VERSION ""

NS_ :

BS_:

BU_: BMS2 BMS1
VAL_TABLE_ PWM_LossOfCom 3 "reserved - same as 0x0 for now" 2 "reserved - same as 0x0 for now" 1 "remain the last received command until communicatino recovers" 0 "default - set output to 0%" ;

BO_ 3221225472 VECTOR__INDEPENDENT_SIG_MSG: 0 Vector__XXX
 SG_ BMS9_N_PosInsR_Copy_1 : 0|16@0+ (1,0) [0|65535] "" Vector__XXX
 SG_ BMS9_N_NegInsR : 0|16@0+ (1,0) [0|65535] "" Vector__XXX
 SG_ BMS9_N_PosInsR : 0|16@0+ (1,0) [0|65535] "" Vector__XXX
 SG_ BMS2_3_Checksum : 0|8@0+ (1,0) [0|255] "" Vector__XXX
 SG_ BMS2_3_F_CellOverV : 0|1@0+ (1,0) [0|1] "" Vector__XXX
 SG_ BMS2_3_F_CellUnderV : 0|1@0+ (1,0) [0|1] "" Vector__XXX
 SG_ BMS2_3_F_CellVoltagedropout : 0|1@0+ (1,0) [0|1] "" Vector__XXX
 SG_ BMS2_3_F_BattOverV : 0|1@0+ (1,0) [0|1] "" Vector__XXX
 SG_ BMS2_3_F_BattUnderV : 0|1@0+ (1,0) [0|1] "" Vector__XXX
 SG_ BMS2_3_RollingCounter : 0|4@0+ (1,0) [0|15] "" Vector__XXX
 SG_ BMS2_9_F_BattSupplyingOverI : 0|2@0+ (1,0) [0|3] "" Vector__XXX
 SG_ BMS2_9_F_QCNegativeRelay : 0|2@0+ (1,0) [0|3] "" Vector__XXX
 SG_ BMS2_9_F_MainPositiveRelayCoil : 0|2@0+ (1,0) [0|3] "" Vector__XXX
 SG_ BMS2_9_F_MainNegativeRelayCoil : 0|2@0+ (1,0) [0|3] "" Vector__XXX
 SG_ BMS2_9_F_PrechargeRelayCoil : 0|2@0+ (1,0) [0|3] "" Vector__XXX
 SG_ BMS2_9_F_QCPositiveRelayCoil : 0|2@0+ (1,0) [0|3] "" Vector__XXX
 SG_ BMS2_9_F_MainPositiveRelay : 0|2@0+ (1,0) [0|3] "" Vector__XXX
 SG_ BMS2_9_F_QCNegativeRelayCoil : 0|2@0+ (1,0) [0|3] "" Vector__XXX
 SG_ BMS2_9_F_CellBalancingCircuit : 0|1@0+ (1,0) [0|1] "" Vector__XXX
 SG_ BMS2_9_F_BattOverChgErr : 0|1@0+ (1,0) [0|1] "" Vector__XXX
 SG_ BMS2_9_F_BattPluginChgOverI : 0|2@0+ (1,0) [0|3] "" Vector__XXX
 SG_ BMS2_9_F_PrechargeRelayOpenStuck : 0|1@0+ (1,0) [0|1] "" Vector__XXX
 SG_ BMS2_9_F_MSDFuse : 0|1@0+ (1,0) [0|1] "" Vector__XXX
 SG_ BMS2_9_F_HVBattTempRisingOverspe : 0|1@0+ (1,0) [0|1] "" Vector__XXX
 SG_ BMS2_9_F_BattRegenerativeOverI : 0|2@0+ (1,0) [0|3] "" Vector__XXX
 SG_ BMS2_9_F_MainNegativeRelay : 0|2@0+ (1,0) [0|3] "" Vector__XXX
 SG_ BMS2_9_F_PrechargeRelay : 0|2@0+ (1,0) [0|3] "" Vector__XXX
 SG_ BMS2_9_F_QCPositiveRelay : 0|2@0+ (1,0) [0|3] "" Vector__XXX
 SG_ BMS3_F_CellOverV : 0|1@0+ (1,0) [0|1] "" Vector__XXX
 SG_ BMS3_F_CellUnderV : 0|1@0+ (1,0) [0|1] "" Vector__XXX
 SG_ BMS3_F_CellVoltagedropout : 0|1@0+ (1,0) [0|1] "" Vector__XXX
 SG_ BMS3_F_BattOverV : 0|1@0+ (1,0) [0|1] "" Vector__XXX
 SG_ BMS3_F_BattUnderV : 0|1@0+ (1,0) [0|1] "" Vector__XXX
 SG_ HCU_2_RelayOn : 0|1@0+ (1,0) [0|1] "" Vector__XXX
 SG_ HCU_2_PWM_LossOfCom : 0|2@0+ (1,0) [0|3] "" Vector__XXX
 SG_ HCU_2_PWM_Dutycycle : 0|8@0+ (0.5,0) [0|127.5] "%" Vector__XXX
 SG_ HCU_2_OBCRelayStatus : 0|1@0+ (1,0) [0|1] "" Vector__XXX
 SG_ HCU_2_ChargingStopRequest : 0|2@0+ (1,0) [0|3] "" Vector__XXX
 SG_ HCU_2_ChargerAllow : 0|1@0+ (1,0) [0|1] "" Vector__XXX
 SG_ HCU_2_CCStatus : 0|1@0+ (1,0) [0|1] "" Vector__XXX
 SG_ HCU2_2_RelayOn : 0|1@0+ (1,0) [0|1] "" Vector__XXX
 SG_ HCU2_2_PWM_LossOfCom : 0|2@0+ (1,0) [0|3] "" Vector__XXX
 SG_ HCU2_2_PWM_Dutycycle : 0|8@0+ (0.5,0) [0|127.5] "%" Vector__XXX
 SG_ HCU2_2_OBCRelayStatus : 0|1@0+ (1,0) [0|1] "" Vector__XXX
 SG_ HCU2_2_ChargingStopRequest : 0|2@0+ (1,0) [0|3] "" Vector__XXX
 SG_ HCU2_2_ChargerAllow : 0|1@0+ (1,0) [0|1] "" Vector__XXX
 SG_ HCU2_2_CCStatus : 0|1@0+ (1,0) [0|1] "" Vector__XXX

BO_ 1192 BMS_12: 4 BMS1
 SG_ BMS12_N_TempMinModule : 31|8@0+ (1,0) [0|44] "" Vector__XXX
 SG_ BMS12_N_TempMaxModule : 23|8@0+ (1,0) [0|44] "" Vector__XXX
 SG_ BMS12_N_CellVolMinModule : 15|8@0+ (1,0) [0|44] "" Vector__XXX
 SG_ BMS12_N_CellVolMaxModule : 7|8@0+ (1,0) [0|44] "" Vector__XXX

BO_ 1208 BMS2_12: 4 BMS2
 SG_ BMS2_12_N_TempMaxModule : 31|8@0+ (1,0) [0|44] ""  BMS2
 SG_ BMS2_12_N_CellVolMinModule : 23|8@0+ (1,0) [0|44] ""  BMS2
 SG_ BMS2_12_N_CellVolMaxModule : 15|8@0+ (1,0) [0|44] ""  BMS2
 SG_ BMS2_12_N_TempMinModule : 7|8@0+ (1,0) [0|44] ""  BMS2

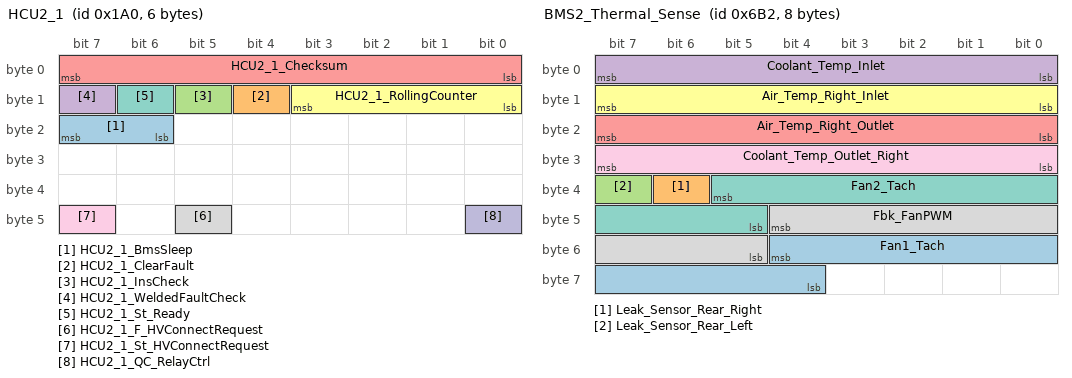
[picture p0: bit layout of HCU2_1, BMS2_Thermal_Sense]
BO_ 416 HCU2_1: 6 Vector__XXX
 SG_ HCU2_1_BmsSleep : 23|2@0+ (1,0) [0|3] ""  BMS2
 SG_ HCU2_1_ClearFault : 12|1@0+ (1,0) [0|0] ""  BMS2
 SG_ HCU2_1_InsCheck : 13|1@0+ (1,0) [0|1] ""  BMS2
 SG_ HCU2_1_WeldedFaultCheck : 15|1@0+ (1,0) [0|1] ""  BMS2
 SG_ HCU2_1_Checksum : 7|8@0+ (1,0) [0|255] ""  BMS2
 SG_ HCU2_1_RollingCounter : 11|4@0+ (1,0) [0|15] ""  BMS2
 SG_ HCU2_1_St_Ready : 14|1@0+ (1,0) [0|1] ""  BMS2
 SG_ HCU2_1_F_HVConnectRequest : 45|1@0+ (1,0) [0|1] ""  BMS2
 SG_ HCU2_1_St_HVConnectRequest : 47|1@0+ (1,0) [0|1] ""  BMS2
 SG_ HCU2_1_QC_RelayCtrl : 40|1@0+ (1,0) [0|1] ""  BMS2

BO_ 1191 BMS_11: 1 BMS1
 SG_ BMS11_St_RSPositiveRelay : 3|1@0+ (1,0) [0|1] "" Vector__XXX
 SG_ BMS11_St_RSNegativeRelay : 4|1@0+ (1,0) [0|1] "" Vector__XXX
 SG_ BMS11_St_LSPositiveRelay : 1|1@0+ (1,0) [0|1] "" Vector__XXX
 SG_ BMS11_St_LSNegativeRelay : 2|1@0+ (1,0) [0|1] "" Vector__XXX
 SG_ BMS11_St_CenterNegativeRelay : 0|1@0+ (1,0) [0|1] "" Vector__XXX

BO_ 1201 BMS2_3: 8 BMS2
 SG_ BMS2_3_N_CellVoltageMin : 52|13@0+ (1,0) [0|5000] "mV" Vector__XXX
 SG_ BMS2_3_N_CellVoltageMax : 36|13@0+ (1,0) [0|5000] "mV" Vector__XXX
 SG_ BMS2_3_N_NegInsR : 23|16@0+ (1,0) [0|65534] "K��" Vector__XXX
 SG_ BMS2_3_N_PosInsR : 7|16@0+ (1,0) [0|65534] "K��" Vector__XXX

BO_ 1185 BMS_3: 8 BMS1
 SG_ BMS3_N_CellVoltageMin : 52|13@0+ (1,0) [0|5000] "mV" Vector__XXX
 SG_ BMS3_N_CellVoltageMax : 36|13@0+ (1,0) [0|5000] "mV" Vector__XXX
 SG_ BMS3_N_NegInsR : 23|16@0+ (1,0) [0|65534] "K��" Vector__XXX
 SG_ BMS3_N_PosInsR : 7|16@0+ (1,0) [0|65534] "k��" Vector__XXX

BO_ 1712 Thermal_Actuator_Cmd: 8 Vector__XXX
 SG_ Pump_PWMFrequency : 39|8@0+ (0.5,0) [0|127.5] "kHz" Vector__XXX
 SG_ WP_DutyCycle : 31|8@0+ (1,0) [0|100] "%" Vector__XXX
 SG_ Fan_PWMFrequency : 16|8@1- (0.5,0) [-64|63.5] "kHz" Vector__XXX
 SG_ Fan_DutyCycle : 15|8@0+ (1,0) [0|100] "%" Vector__XXX
 SG_ TEC_1_Relay : 6|1@0+ (1,0) [0|1] "" Vector__XXX
 SG_ TEC_2_Relay : 7|1@0+ (1,0) [0|1] "" Vector__XXX

BO_ 1714 BMS2_Thermal_Sense: 8 BMS2
 SG_ Fan1_Tach : 52|9@0+ (16,0) [0|8176] "" Vector__XXX
 SG_ Leak_Sensor_Rear_Right : 38|1@0+ (1,0) [0|1] "" Vector__XXX
 SG_ Leak_Sensor_Rear_Left : 39|1@0+ (1,0) [0|1] "" Vector__XXX
 SG_ Coolant_Temp_Inlet : 7|8@0- (1,0) [-128|127] "" Vector__XXX
 SG_ Air_Temp_Right_Outlet : 23|8@0- (1,0) [-128|127] "" Vector__XXX
 SG_ Air_Temp_Right_Inlet : 15|8@0- (1,0) [-128|127] "" Vector__XXX
 SG_ Fan2_Tach : 37|9@0+ (16,0) [0|8176] "" Vector__XXX
 SG_ Fbk_FanPWM : 44|8@0+ (0.4,0) [0|100] "%" Vector__XXX
 SG_ Coolant_Temp_Outlet_Right : 31|8@0- (1,0) [-128|127] "" Vector__XXX

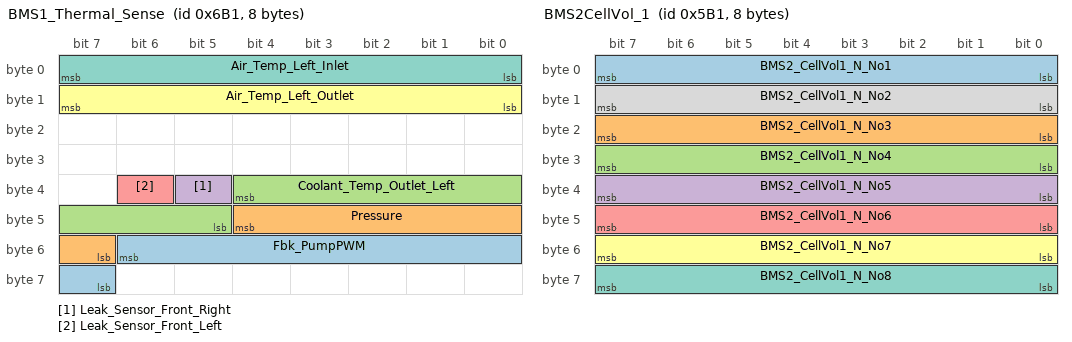
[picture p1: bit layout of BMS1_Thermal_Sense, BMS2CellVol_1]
BO_ 1713 BMS1_Thermal_Sense: 8 BMS1
 SG_ Fbk_PumpPWM : 54|8@0+ (0.4,0) [0|100] "%" Vector__XXX
 SG_ Pressure : 44|6@0+ (1,0) [0|63] "psi" Vector__XXX
 SG_ Coolant_Temp_Outlet_Left : 36|8@0- (1,0) [-128|127] "" Vector__XXX
 SG_ Leak_Sensor_Front_Right : 37|1@0+ (1,0) [0|1] "" Vector__XXX
 SG_ Leak_Sensor_Front_Left : 38|1@0+ (1,0) [0|1] "" Vector__XXX
 SG_ Air_Temp_Left_Outlet : 15|8@0- (1,0) [-128|127] "" Vector__XXX
 SG_ Air_Temp_Left_Inlet : 7|8@0- (1,0) [-128|127] "" Vector__XXX

BO_ 1533 BMS2_HWSerialNumber: 8 BMS2
 SG_ BMS2_HWSerialNumber : 7|64@0+ (1,0) [0|0] "" Vector__XXX

BO_ 1531 BMS1_HWSerialNumber: 8 BMS1
 SG_ BMS1_HWSerialNumber : 7|64@0+ (1,0) [0|1.84467440737096E+019] "" Vector__XXX

BO_ 1483 BMS2Diag: 8 BMS2
 SG_ BCM2Diag_VoltRangeFault m1 : 57|2@0+ (1,0) [0|3] "" Vector__XXX
 SG_ BCM2Diag_TtlVoltSampAbnorm m1 : 55|2@0+ (1,0) [0|3] "" Vector__XXX
 SG_ BCM2Diag_TempRangeFault m1 : 59|2@0+ (1,0) [0|3] "" Vector__XXX
 SG_ BCM2Diag_SuppVoltTooLow m1 : 53|2@0+ (1,0) [0|3] "" Vector__XXX
 SG_ BCM2Diag_SeriousOvercurrFault m1 : 51|2@0+ (1,0) [0|3] "" Vector__XXX
 SG_ BCM2Diag_SDMCommLost m1 : 49|2@0+ (1,0) [0|3] "" Vector__XXX
 SG_ BCM2Diag_RTCFault m1 : 47|2@0+ (1,0) [0|3] "" Vector__XXX
 SG_ BCM2Diag_PrsrSnsrShrtToGnd m1 : 43|2@0+ (1,0) [0|3] "" Vector__XXX
 SG_ BCM2Diag_PrsrSnsrOC m1 : 41|2@0+ (1,0) [0|3] "" Vector__XXX
 SG_ BCM2Diag_PrechrgWthLoadFault m1 : 39|2@0+ (1,0) [0|3] "" Vector__XXX
 SG_ BCM2Diag_PrechrgRelayCantClose m1 : 37|2@0+ (1,0) [0|3] "" Vector__XXX
 SG_ BCM2Diag_PrechrgFail m1 : 35|2@0+ (1,0) [0|3] "" Vector__XXX
 SG_ BCM2Diag_PosRelayStuck m1 : 33|2@0+ (1,0) [0|3] "" Vector__XXX
 SG_ BCM2Diag_PosRelayCantClose m1 : 31|2@0+ (1,0) [0|3] "" Vector__XXX
 SG_ BCM2Diag_PackVoltTooLowLvl2 m1 : 29|2@0+ (1,0) [0|3] "" Vector__XXX
 SG_ BCM2Diag_PackVoltTooLowLvl1 m1 : 27|2@0+ (1,0) [0|3] "" Vector__XXX
 SG_ BCM2Diag_PackVoltTooHighLvl2 m1 : 25|2@0+ (1,0) [0|3] "" Vector__XXX
 SG_ BCM2Diag_PackVoltTooHighLvl1 m1 : 23|2@0+ (1,0) [0|3] "" Vector__XXX
 SG_ BCM2Diag_NVMFault m1 : 21|2@0+ (1,0) [0|3] "" Vector__XXX
 SG_ BCM2Diag_NegRelayStuck m1 : 19|2@0+ (1,0) [0|3] "" Vector__XXX
 SG_ BCM2Diag_NegRelayCantClose m1 : 17|2@0+ (1,0) [0|3] "" Vector__XXX
 SG_ BCM2Diag_Mulitplexer M : 63|2@0+ (1,0) [0|3] "" Vector__XXX
 SG_ BCM2Diag_LeakSnsrShrtToGnd m1 : 15|2@0+ (1,0) [0|3] "" Vector__XXX
 SG_ BCM2Diag_LeakSnsrOC m1 : 13|2@0+ (1,0) [0|3] "" Vector__XXX
 SG_ BCM2Diag_InsFaultLvl3 m1 : 11|2@0+ (1,0) [0|3] "" Vector__XXX
 SG_ BCM2Diag_InsFaultLvl2 m1 : 9|2@0+ (1,0) [0|3] "" Vector__XXX
 SG_ BCM2Diag_InsFaultLvl1 m1 : 7|2@0+ (1,0) [0|3] "" Vector__XXX
 SG_ BCM2Diag_HVModCommLoss m1 : 5|2@0+ (1,0) [0|3] "" Vector__XXX
 SG_ BCM2Diag_HVILFault m1 : 3|2@0+ (1,0) [0|3] "" Vector__XXX
 SG_ BCM2Diag_GenertdCurrTooHighLvl2 m1 : 1|2@0+ (1,0) [0|3] "" Vector__XXX
 SG_ BCM2Diag_GenertdCurrTooHighLvl1 m0 : 57|2@0+ (1,0) [0|3] "" Vector__XXX
 SG_ BCM2Diag_FuseFault m0 : 59|2@0+ (1,0) [0|3] "" Vector__XXX
 SG_ BCM2Diag_DischrgCurrTooHighLvl2 m0 : 61|2@0+ (1,0) [0|3] "" Vector__XXX
 SG_ BCM2Diag_DischrgCurrTooHighLvl1 m1 : 45|2@0+ (1,0) [0|3] "" Vector__XXX
 SG_ BCM2Diag_CurrSnsrNoComRelayStuck m0 : 49|2@0+ (1,0) [0|3] "" Vector__XXX
 SG_ BCM2Diag_CurrSnsrFault m0 : 51|2@0+ (1,0) [0|3] "" Vector__XXX
 SG_ BCM2Diag_CurrSnsrCommTimedout m0 : 53|2@0+ (1,0) [0|3] "" Vector__XXX
 SG_ BCM2Diag_CellVoltSamplLineBrk m0 : 55|2@0+ (1,0) [0|3] "" Vector__XXX
 SG_ BCM2Diag_CellVoltDiffHigh m0 : 41|2@0+ (1,0) [0|3] "" Vector__XXX
 SG_ BCM2Diag_CellUndrVoltLvl3 m0 : 43|2@0+ (1,0) [0|3] "" Vector__XXX
 SG_ BCM2Diag_CellUndrVoltLvl2 m0 : 45|2@0+ (1,0) [0|3] "" Vector__XXX
 SG_ BCM2Diag_CellundrVoltLvl1 m0 : 47|2@0+ (1,0) [0|3] "" Vector__XXX
 SG_ BCM2Diag_CellTempTooLowLvl3 m0 : 33|2@0+ (1,0) [0|3] "" Vector__XXX
 SG_ BCM2Diag_CellTempTooLowLvl2 m0 : 35|2@0+ (1,0) [0|3] "" Vector__XXX
 SG_ BCM2Diag_CellTempTooLowLvl1 m0 : 37|2@0+ (1,0) [0|3] "" Vector__XXX
 SG_ BCM2Diag_CellTempTooHighLvl2 m0 : 39|2@0+ (1,0) [0|3] "" Vector__XXX
 SG_ BCM2Diag_CellTempTooHighLvl1 m0 : 25|2@0+ (1,0) [0|3] "" Vector__XXX
 SG_ BCM2Diag_CellTempTooHighLv3 m0 : 27|2@0+ (1,0) [0|3] "" Vector__XXX
 SG_ BCM2Diag_CellTempSamplLineBrk m0 : 29|2@0+ (1,0) [0|3] "" Vector__XXX
 SG_ BCM2Diag_CellTempDiffHigh m0 : 31|2@0+ (1,0) [0|3] "" Vector__XXX
 SG_ BCM2Diag_CellOvrVoltLvl3 m0 : 17|2@0+ (1,0) [0|3] "" Vector__XXX
 SG_ BCM2Diag_CellOvrVoltLvl2 m0 : 19|2@0+ (1,0) [0|3] "" Vector__XXX
 SG_ BCM2Diag_CellOvrVoltLvl1 m0 : 21|2@0+ (1,0) [0|3] "" Vector__XXX
 SG_ BCM2Diag_CellBalancFault m0 : 23|2@0+ (1,0) [0|3] "" Vector__XXX
 SG_ BCM2Diag_CANCRCFailure m0 : 9|2@0+ (1,0) [0|3] "" Vector__XXX
 SG_ BCM2Diag_CANCounterAbnormal m0 : 11|2@0+ (1,0) [0|3] "" Vector__XXX
 SG_ BCM2Diag_BilatrlPosNegRelayStuck m0 : 13|2@0+ (1,0) [0|3] "" Vector__XXX
 SG_ BCM2Diag_AirTempSnsrShrtToGnd m0 : 15|2@0+ (1,0) [0|3] "" Vector__XXX
 SG_ BCM2Diag_AirTempSnsrOC m0 : 1|2@0+ (1,0) [0|3] "" Vector__XXX
 SG_ BCM2Diag_AFECommLost m0 : 3|2@0+ (1,0) [0|3] "" Vector__XXX
 SG_ BCM2Diag_12VBattVoltTooLow m0 : 5|2@0+ (1,0) [0|3] "" Vector__XXX
 SG_ BCM2Diag_12VBattVoltTooHigh m0 : 7|2@0+ (1,0) [0|3] "" Vector__XXX

BO_ 1440 BMS1Diag: 8 BMS1
 SG_ BCM1Diag_VoltRangeFault m1 : 59|2@0+ (1,0) [0|3] "" Vector__XXX
 SG_ BCM1Diag_TtlVoltSampAbnorm m1 : 57|2@0+ (1,0) [0|3] "" Vector__XXX
 SG_ BCM1Diag_TempRangeFault m1 : 55|2@0+ (1,0) [0|3] "" Vector__XXX
 SG_ BCM1Diag_SuppVoltTooLow m1 : 53|2@0+ (1,0) [0|3] "" Vector__XXX
 SG_ BCM1Diag_SeriousOvercurrFault m1 : 51|2@0+ (1,0) [0|3] "" Vector__XXX
 SG_ BCM1Diag_SDMCommLost m1 : 49|2@0+ (1,0) [0|3] "" Vector__XXX
 SG_ BCM1Diag_RTCFault m1 : 47|2@0+ (1,0) [0|3] "" Vector__XXX
 SG_ BCM1Diag_PrsrSnsrShrtToGnd m1 : 45|2@0+ (1,0) [0|3] "" Vector__XXX
 SG_ BCM1Diag_PrsrSnsrOC m1 : 43|2@0+ (1,0) [0|3] "" Vector__XXX
 SG_ BCM1Diag_PrechrgWthLoadFault m1 : 41|2@0+ (1,0) [0|3] "" Vector__XXX
 SG_ BCM1Diag_PrechrgRelayCantClose m1 : 39|2@0+ (1,0) [0|3] "" Vector__XXX
 SG_ BCM1Diag_PrechrgFail m1 : 37|2@0+ (1,0) [0|3] "" Vector__XXX
 SG_ BCM1Diag_PosRelayStuck m1 : 35|2@0+ (1,0) [0|3] "" Vector__XXX
 SG_ BCM1Diag_PosRelayCantClose m1 : 33|2@0+ (1,0) [0|3] "" Vector__XXX
 SG_ BCM1Diag_PackVoltTooLowLvl2 m1 : 31|2@0+ (1,0) [0|3] "" Vector__XXX
 SG_ BCM1Diag_PackVoltTooLowLvl1 m1 : 29|2@0+ (1,0) [0|3] "" Vector__XXX
 SG_ BCM1Diag_PackVoltTooHighLvl2 m1 : 27|2@0+ (1,0) [0|3] "" Vector__XXX
 SG_ BCM1Diag_PackVoltTooHighLvl1 m1 : 25|2@0+ (1,0) [0|3] "" Vector__XXX
 SG_ BCM1Diag_NVMFault m1 : 23|2@0+ (1,0) [0|3] "" Vector__XXX
 SG_ BCM1Diag_NegRelayStuck m1 : 19|2@0+ (1,0) [0|3] "" Vector__XXX
 SG_ BCM1Diag_NegRelayCantClose m1 : 21|2@0+ (1,0) [0|3] "" Vector__XXX
 SG_ BCM1Diag_Mulitplexer M : 63|2@0+ (1,0) [0|3] "" Vector__XXX
 SG_ BCM1Diag_LeakSnsrShrtToGnd m1 : 17|2@0+ (1,0) [0|3] "" Vector__XXX
 SG_ BCM1Diag_LeakSnsrOC m1 : 15|2@0+ (1,0) [0|3] "" Vector__XXX
 SG_ BCM1Diag_InsFaultLvl3 m1 : 13|2@0+ (1,0) [0|3] "" Vector__XXX
 SG_ BCM1Diag_InsFaultLvl2 m1 : 11|2@0+ (1,0) [0|3] "" Vector__XXX
 SG_ BCM1Diag_InsFaultLvl1 m1 : 9|2@0+ (1,0) [0|3] "" Vector__XXX
 SG_ BCM1Diag_HVModCommLoss m1 : 7|2@0+ (1,0) [0|3] "" Vector__XXX
 SG_ BCM1Diag_HVILFault m1 : 5|2@0+ (1,0) [0|3] "" Vector__XXX
 SG_ BCM1Diag_GenertdCurrTooHighLvl2 m1 : 3|2@0+ (1,0) [0|3] "" Vector__XXX
 SG_ BCM1Diag_GenertdCurrTooHighLvl1 m0 : 57|2@0+ (1,0) [0|3] "" Vector__XXX
 SG_ BCM1Diag_FuseFault m0 : 59|2@0+ (1,0) [0|3] "" Vector__XXX
 SG_ BCM1Diag_DischrgCurrTooHighLvl2 m0 : 61|2@0+ (1,0) [0|3] "" Vector__XXX
 SG_ BCM1Diag_DischrgCurrTooHighLvl1 m1 : 1|2@0+ (1,0) [0|3] "" Vector__XXX
 SG_ BCM1Diag_CurrSnsrNoComRelayStuck m0 : 49|2@0+ (1,0) [0|3] "" Vector__XXX
 SG_ BCM1Diag_CurrSnsrFault m0 : 51|2@0+ (1,0) [0|3] "" Vector__XXX
 SG_ BCM1Diag_CurrSnsrCommTimedout m0 : 53|2@0+ (1,0) [0|3] "" Vector__XXX
 SG_ BCM1Diag_CellVoltSamplLineBrk m0 : 55|2@0+ (1,0) [0|3] "" Vector__XXX
 SG_ BCM1Diag_CellVoltDiffHigh m0 : 41|2@0+ (1,0) [0|3] "" Vector__XXX
 SG_ BCM1Diag_CellUndrVoltLvl3 m0 : 43|2@0+ (1,0) [0|3] "" Vector__XXX
 SG_ BCM1Diag_CellUndrVoltLvl2 m0 : 45|2@0+ (1,0) [0|3] "" Vector__XXX
 SG_ BCM1Diag_CellundrVoltLvl1 m0 : 47|2@0+ (1,0) [0|3] "" Vector__XXX
 SG_ BCM1Diag_CellTempTooLowLvl3 m0 : 33|2@0+ (1,0) [0|3] "" Vector__XXX
 SG_ BCM1Diag_CellTempTooLowLvl2 m0 : 35|2@0+ (1,0) [0|3] "" Vector__XXX
 SG_ BCM1Diag_CellTempTooLowLvl1 m0 : 37|2@0+ (1,0) [0|3] "" Vector__XXX
 SG_ BCM1Diag_CellTempTooHighLvl2 m0 : 39|2@0+ (1,0) [0|3] "" Vector__XXX
 SG_ BCM1Diag_CellTempTooHighLvl1 m0 : 25|2@0+ (1,0) [0|3] "" Vector__XXX
 SG_ BCM1Diag_CellTempTooHighLv3 m0 : 27|2@0+ (1,0) [0|3] "" Vector__XXX
 SG_ BCM1Diag_CellTempSamplLineBrk m0 : 29|2@0+ (1,0) [0|3] "" Vector__XXX
 SG_ BCM1Diag_CellTempDiffHigh m0 : 31|2@0+ (1,0) [0|3] "" Vector__XXX
 SG_ BCM1Diag_CellOvrVoltLvl3 m0 : 17|2@0+ (1,0) [0|3] "" Vector__XXX
 SG_ BCM1Diag_CellOvrVoltLvl2 m0 : 19|2@0+ (1,0) [0|3] "" Vector__XXX
 SG_ BCM1Diag_CellOvrVoltLvl1 m0 : 21|2@0+ (1,0) [0|3] "" Vector__XXX
 SG_ BCM1Diag_CellBalancFault m0 : 23|2@0+ (1,0) [0|3] "" Vector__XXX
 SG_ BCM1Diag_CANCRCFailure m0 : 9|2@0+ (1,0) [0|3] "" Vector__XXX
 SG_ BCM1Diag_CANCounterAbnormal m0 : 11|2@0+ (1,0) [0|3] "" Vector__XXX
 SG_ BCM1Diag_BilatrlPosNegRelayStuck m0 : 13|2@0+ (1,0) [0|3] "" Vector__XXX
 SG_ BCM1Diag_AirTempSnsrShrtToGnd m0 : 15|2@0+ (1,0) [0|3] "" Vector__XXX
 SG_ BCM1Diag_AirTempSnsrOC m0 : 1|2@0+ (1,0) [0|3] "" Vector__XXX
 SG_ BCM1Diag_AFECommLost m0 : 3|2@0+ (1,0) [0|3] "" Vector__XXX
 SG_ BCM1Diag_12VBattVoltTooLow m0 : 5|2@0+ (1,0) [0|3] "" Vector__XXX
 SG_ BCM1Diag_12VBattVoltTooHigh m0 : 7|2@0+ (1,0) [0|3] "" Vector__XXX

BO_ 1532 BMS2_FirmwareVersion: 8 BMS2
 SG_ BMS2_FirmwareVersion : 7|64@0+ (1,0) [0|0] "" Vector__XXX

BO_ 1530 BMS1_FirmwareVersion: 8 BMS1
 SG_ BMS1_FirmwareVersion : 7|64@0+ (1,0) [0|1.84467440737096E+019] "" Vector__XXX

BO_ 1469 BMS2_CMATemp_Fr01: 8 BMS2
 SG_ BMS2_CMATemp_Multiplexer M : 4|4@1+ (1,0) [0|15] "" Vector__XXX
 SG_ BMS2_CMATemp_N_No9 m0 : 43|5@0+ (3,-28) [-28|65] "degC" Vector__XXX
 SG_ BMS2_CMATemp_N_No48 m3 : 60|5@0+ (3,-28) [-28|65] "degC" Vector__XXX
 SG_ BMS2_CMATemp_N_No47 m3 : 49|5@0+ (3,-28) [-28|65] "degC" Vector__XXX
 SG_ BMS2_CMATemp_N_No46 m3 : 54|5@0+ (3,-28) [-28|65] "degC" Vector__XXX
 SG_ BMS2_CMATemp_N_No45 m3 : 43|5@0+ (3,-28) [-28|65] "degC" Vector__XXX
 SG_ BMS2_CMATemp_N_No44 m3 : 32|5@0+ (3,-28) [-28|65] "degC" Vector__XXX
 SG_ BMS2_CMATemp_N_No43 m3 : 37|5@0+ (3,-28) [-28|65] "degC" Vector__XXX
 SG_ BMS2_CMATemp_N_No42 m3 : 26|5@0+ (3,-28) [-28|65] "degC" Vector__XXX
 SG_ BMS2_CMATemp_N_No41 m3 : 31|5@0+ (3,-28) [-28|65] "degC" Vector__XXX
 SG_ BMS2_CMATemp_N_No40 m3 : 20|5@0+ (3,-28) [-28|65] "degC" Vector__XXX
 SG_ BMS2_CMATemp_N_No39 m3 : 9|5@0+ (3,-28) [-28|65] "degC" Vector__XXX
 SG_ BMS2_CMATemp_N_No38 m3 : 14|5@0+ (3,-28) [-28|65] "degC" Vector__XXX
 SG_ BMS2_CMATemp_N_No37 m3 : 3|5@0+ (3,-28) [-28|65] "degC" Vector__XXX
 SG_ BMS2_CMATemp_N_No36 m2 : 60|5@0+ (3,-28) [-28|65] "degC" Vector__XXX
 SG_ BMS2_CMATemp_N_No35 m2 : 49|5@0+ (3,-28) [-28|65] "degC" Vector__XXX
 SG_ BMS2_CMATemp_N_No34 m2 : 54|5@0+ (3,-28) [-28|65] "degC" Vector__XXX
 SG_ BMS2_CMATemp_N_No33 m2 : 43|5@0+ (3,-28) [-28|65] "degC" Vector__XXX
 SG_ BMS2_CMATemp_N_No32 m2 : 32|5@0+ (3,-28) [-28|65] "degC" Vector__XXX
 SG_ BMS2_CMATemp_N_No31 m2 : 37|5@0+ (3,-28) [-28|65] "degC" Vector__XXX
 SG_ BMS2_CMATemp_N_No30 m2 : 26|5@0+ (3,-28) [-28|65] "degC" Vector__XXX
 SG_ BMS2_CMATemp_N_No29 m2 : 31|5@0+ (3,-28) [-28|65] "degC" Vector__XXX
 SG_ BMS2_CMATemp_N_No28 m2 : 20|5@0+ (3,-28) [-28|65] "degC" Vector__XXX
 SG_ BMS2_CMATemp_N_No27 m2 : 9|5@0+ (3,-28) [-28|65] "degC" Vector__XXX
 SG_ BMS2_CMATemp_N_No26 m2 : 14|5@0+ (3,-28) [-28|65] "degC" Vector__XXX
 SG_ BMS2_CMATemp_N_No25 m2 : 3|5@0+ (3,-28) [-28|65] "degC" Vector__XXX
 SG_ BMS2_CMATemp_N_No24 m1 : 60|5@0+ (3,-28) [-28|65] "degC" Vector__XXX
 SG_ BMS2_CMATemp_N_No23 m1 : 49|5@0+ (3,-28) [-28|65] "degC" Vector__XXX
 SG_ BMS2_CMATemp_N_No22 m1 : 54|5@0+ (3,-28) [-28|65] "degC" Vector__XXX
 SG_ BMS2_CMATemp_N_No21 m1 : 43|5@0+ (3,-28) [-28|65] "degC" Vector__XXX
 SG_ BMS2_CMATemp_N_No20 m1 : 32|5@0+ (3,-28) [-28|65] "degC" Vector__XXX
 SG_ BMS2_CMATemp_N_No19 m1 : 37|5@0+ (3,-28) [-28|65] "degC" Vector__XXX
 SG_ BMS2_CMATemp_N_No18 m1 : 26|5@0+ (3,-28) [-28|65] "degC" Vector__XXX
 SG_ BMS2_CMATemp_N_No17 m1 : 31|5@0+ (3,-28) [-28|65] "degC" Vector__XXX
 SG_ BMS2_CMATemp_N_No16 m1 : 20|5@0+ (3,-28) [-28|65] "degC" Vector__XXX
 SG_ BMS2_CMATemp_N_No15 m1 : 9|5@0+ (3,-28) [-28|65] "degC" Vector__XXX
 SG_ BMS2_CMATemp_N_No14 m1 : 14|5@0+ (3,-28) [-28|65] "degC" Vector__XXX
 SG_ BMS2_CMATemp_N_No13 m1 : 3|5@0+ (3,-28) [-28|65] "degC" Vector__XXX
 SG_ BMS2_CMATemp_N_No12 m0 : 60|5@0+ (3,-28) [-28|65] "degC" Vector__XXX
 SG_ BMS2_CMATemp_N_No11 m0 : 49|5@0+ (3,-28) [-28|65] "degC" Vector__XXX
 SG_ BMS2_CMATemp_N_No10 m0 : 54|5@0+ (3,-28) [-28|65] "degC" Vector__XXX
 SG_ BMS2_CMATemp_N_No1 m0 : 3|5@0+ (3,-28) [-28|65] "degC" Vector__XXX
 SG_ BMS2_CMATemp_N_No3 m0 : 9|5@0+ (3,-28) [-28|65] "degC" Vector__XXX
 SG_ BMS2_CMATemp_N_No4 m0 : 20|5@0+ (3,-28) [-28|65] "degC" Vector__XXX
 SG_ BMS2_CMATemp_N_No5 m0 : 31|5@0+ (3,-28) [-28|65] "degC" Vector__XXX
 SG_ BMS2_CMATemp_N_No6 m0 : 26|5@0+ (3,-28) [-28|65] "degC" Vector__XXX
 SG_ BMS2_CMATemp_N_No7 m0 : 37|5@0+ (3,-28) [-28|65] "degC" Vector__XXX
 SG_ BMS2_CMATemp_N_No8 m0 : 32|5@0+ (3,-28) [-28|65] "degC" Vector__XXX
 SG_ BMS2_CMATemp_N_No2 m0 : 14|5@0+ (3,-28) [-28|65] "degC" Vector__XXX

BO_ 1457 BMS2CellVol_1: 8 BMS2
 SG_ BMS2_CellVol1_N_No1 : 7|8@0+ (20,0) [0|5000] "mV" Vector__XXX
 SG_ BMS2_CellVol1_N_No3 : 23|8@0+ (20,0) [0|5000] "mV" Vector__XXX
 SG_ BMS2_CellVol1_N_No4 : 31|8@0+ (20,0) [0|5000] "mV" Vector__XXX
 SG_ BMS2_CellVol1_N_No5 : 39|8@0+ (20,0) [0|5000] "mV" Vector__XXX
 SG_ BMS2_CellVol1_N_No6 : 47|8@0+ (20,0) [0|5000] "mV" Vector__XXX
 SG_ BMS2_CellVol1_N_No7 : 55|8@0+ (20,0) [0|5000] "mV" Vector__XXX
 SG_ BMS2_CellVol1_N_No8 : 63|8@0+ (20,0) [0|5000] "mV" Vector__XXX
 SG_ BMS2_CellVol1_N_No2 : 15|8@0+ (20,0) [0|5000] "mV" Vector__XXX

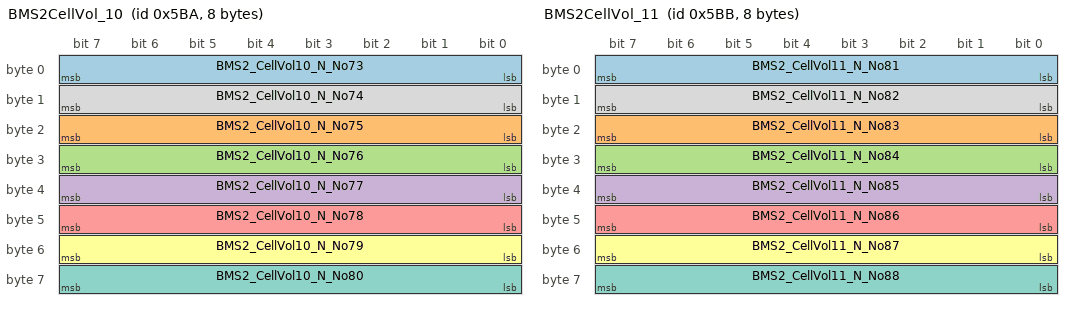
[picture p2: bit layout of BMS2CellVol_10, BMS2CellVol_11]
BO_ 1466 BMS2CellVol_10: 8 BMS2
 SG_ BMS2_CellVol10_N_No73 : 7|8@0+ (20,0) [0|5000] "mV" Vector__XXX
 SG_ BMS2_CellVol10_N_No75 : 23|8@0+ (20,0) [0|5000] "mV" Vector__XXX
 SG_ BMS2_CellVol10_N_No76 : 31|8@0+ (20,0) [0|5000] "mV" Vector__XXX
 SG_ BMS2_CellVol10_N_No77 : 39|8@0+ (20,0) [0|5000] "mV" Vector__XXX
 SG_ BMS2_CellVol10_N_No78 : 47|8@0+ (20,0) [0|5000] "mV" Vector__XXX
 SG_ BMS2_CellVol10_N_No79 : 55|8@0+ (20,0) [0|5000] "mV" Vector__XXX
 SG_ BMS2_CellVol10_N_No80 : 63|8@0+ (20,0) [0|5000] "mV" Vector__XXX
 SG_ BMS2_CellVol10_N_No74 : 15|8@0+ (20,0) [0|5000] "mV" Vector__XXX

BO_ 1467 BMS2CellVol_11: 8 BMS2
 SG_ BMS2_CellVol11_N_No81 : 7|8@0+ (20,0) [0|5000] "mV" Vector__XXX
 SG_ BMS2_CellVol11_N_No83 : 23|8@0+ (20,0) [0|5000] "mV" Vector__XXX
 SG_ BMS2_CellVol11_N_No84 : 31|8@0+ (20,0) [0|5000] "mV" Vector__XXX
 SG_ BMS2_CellVol11_N_No85 : 39|8@0+ (20,0) [0|5000] "mV" Vector__XXX
 SG_ BMS2_CellVol11_N_No86 : 47|8@0+ (20,0) [0|5000] "mV" Vector__XXX
 SG_ BMS2_CellVol11_N_No87 : 55|8@0+ (20,0) [0|5000] "mV" Vector__XXX
 SG_ BMS2_CellVol11_N_No88 : 63|8@0+ (20,0) [0|5000] "mV" Vector__XXX
 SG_ BMS2_CellVol11_N_No82 : 15|8@0+ (20,0) [0|5000] "mV" Vector__XXX

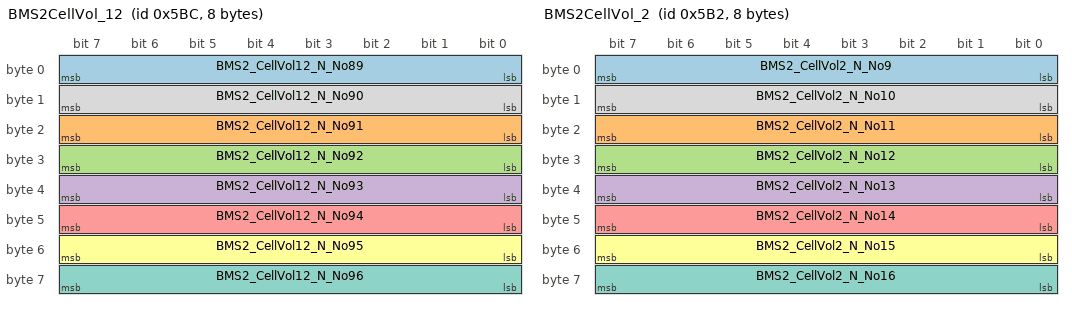
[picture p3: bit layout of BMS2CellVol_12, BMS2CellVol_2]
BO_ 1468 BMS2CellVol_12: 8 BMS2
 SG_ BMS2_CellVol12_N_No89 : 7|8@0+ (20,0) [0|5000] "mV" Vector__XXX
 SG_ BMS2_CellVol12_N_No91 : 23|8@0+ (20,0) [0|5000] "mV" Vector__XXX
 SG_ BMS2_CellVol12_N_No92 : 31|8@0+ (20,0) [0|5000] "mV" Vector__XXX
 SG_ BMS2_CellVol12_N_No93 : 39|8@0+ (20,0) [0|5000] "mV" Vector__XXX
 SG_ BMS2_CellVol12_N_No94 : 47|8@0+ (20,0) [0|5000] "mV" Vector__XXX
 SG_ BMS2_CellVol12_N_No95 : 55|8@0+ (20,0) [0|5000] "mV" Vector__XXX
 SG_ BMS2_CellVol12_N_No96 : 63|8@0+ (20,0) [0|5000] "mV" Vector__XXX
 SG_ BMS2_CellVol12_N_No90 : 15|8@0+ (20,0) [0|5000] "mV" Vector__XXX

BO_ 1458 BMS2CellVol_2: 8 BMS2
 SG_ BMS2_CellVol2_N_No9 : 7|8@0+ (20,0) [0|5000] "mV" Vector__XXX
 SG_ BMS2_CellVol2_N_No11 : 23|8@0+ (20,0) [0|5000] "mV" Vector__XXX
 SG_ BMS2_CellVol2_N_No12 : 31|8@0+ (20,0) [0|5000] "mV" Vector__XXX
 SG_ BMS2_CellVol2_N_No13 : 39|8@0+ (20,0) [0|5000] "mV" Vector__XXX
 SG_ BMS2_CellVol2_N_No14 : 47|8@0+ (20,0) [0|5000] "mV" Vector__XXX
 SG_ BMS2_CellVol2_N_No15 : 55|8@0+ (20,0) [0|5000] "mV" Vector__XXX
 SG_ BMS2_CellVol2_N_No16 : 63|8@0+ (20,0) [0|5000] "mV" Vector__XXX
 SG_ BMS2_CellVol2_N_No10 : 15|8@0+ (20,0) [0|5000] "mV" Vector__XXX

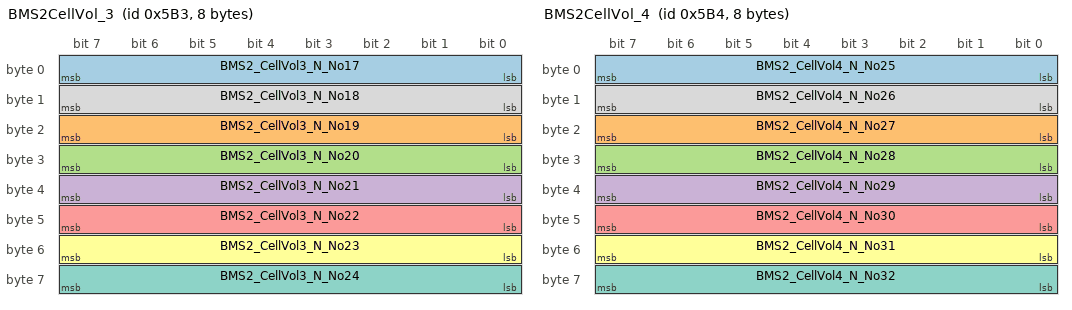
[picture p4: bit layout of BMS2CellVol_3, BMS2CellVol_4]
BO_ 1459 BMS2CellVol_3: 8 BMS2
 SG_ BMS2_CellVol3_N_No17 : 7|8@0+ (20,0) [0|5000] "mV" Vector__XXX
 SG_ BMS2_CellVol3_N_No19 : 23|8@0+ (20,0) [0|5000] "mV" Vector__XXX
 SG_ BMS2_CellVol3_N_No20 : 31|8@0+ (20,0) [0|5000] "mV" Vector__XXX
 SG_ BMS2_CellVol3_N_No21 : 39|8@0+ (20,0) [0|5000] "mV" Vector__XXX
 SG_ BMS2_CellVol3_N_No22 : 47|8@0+ (20,0) [0|5000] "mV" Vector__XXX
 SG_ BMS2_CellVol3_N_No23 : 55|8@0+ (20,0) [0|5000] "mV" Vector__XXX
 SG_ BMS2_CellVol3_N_No24 : 63|8@0+ (20,0) [0|5000] "mV" Vector__XXX
 SG_ BMS2_CellVol3_N_No18 : 15|8@0+ (20,0) [0|5000] "mV" Vector__XXX

BO_ 1460 BMS2CellVol_4: 8 BMS2
 SG_ BMS2_CellVol4_N_No25 : 7|8@0+ (20,0) [0|5000] "mV" Vector__XXX
 SG_ BMS2_CellVol4_N_No27 : 23|8@0+ (20,0) [0|5000] "mV" Vector__XXX
 SG_ BMS2_CellVol4_N_No28 : 31|8@0+ (20,0) [0|5000] "mV" Vector__XXX
 SG_ BMS2_CellVol4_N_No29 : 39|8@0+ (20,0) [0|5000] "mV" Vector__XXX
 SG_ BMS2_CellVol4_N_No30 : 47|8@0+ (20,0) [0|5000] "mV" Vector__XXX
 SG_ BMS2_CellVol4_N_No31 : 55|8@0+ (20,0) [0|5000] "mV" Vector__XXX
 SG_ BMS2_CellVol4_N_No32 : 63|8@0+ (20,0) [0|5000] "mV" Vector__XXX
 SG_ BMS2_CellVol4_N_No26 : 15|8@0+ (20,0) [0|5000] "mV" Vector__XXX

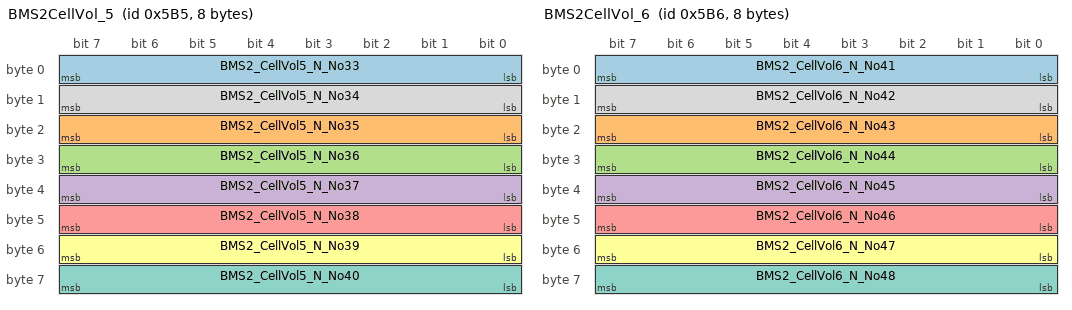
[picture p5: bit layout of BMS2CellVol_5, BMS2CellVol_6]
BO_ 1461 BMS2CellVol_5: 8 BMS2
 SG_ BMS2_CellVol5_N_No33 : 7|8@0+ (20,0) [0|5000] "mV" Vector__XXX
 SG_ BMS2_CellVol5_N_No35 : 23|8@0+ (20,0) [0|5000] "mV" Vector__XXX
 SG_ BMS2_CellVol5_N_No36 : 31|8@0+ (20,0) [0|5000] "mV" Vector__XXX
 SG_ BMS2_CellVol5_N_No37 : 39|8@0+ (20,0) [0|5000] "mV" Vector__XXX
 SG_ BMS2_CellVol5_N_No38 : 47|8@0+ (20,0) [0|5000] "mV" Vector__XXX
 SG_ BMS2_CellVol5_N_No39 : 55|8@0+ (20,0) [0|5000] "mV" Vector__XXX
 SG_ BMS2_CellVol5_N_No40 : 63|8@0+ (20,0) [0|5000] "mV" Vector__XXX
 SG_ BMS2_CellVol5_N_No34 : 15|8@0+ (20,0) [0|5000] "mV" Vector__XXX

BO_ 1462 BMS2CellVol_6: 8 BMS2
 SG_ BMS2_CellVol6_N_No41 : 7|8@0+ (20,0) [0|5000] "mV" Vector__XXX
 SG_ BMS2_CellVol6_N_No43 : 23|8@0+ (20,0) [0|5000] "mV" Vector__XXX
 SG_ BMS2_CellVol6_N_No44 : 31|8@0+ (20,0) [0|5000] "mV" Vector__XXX
 SG_ BMS2_CellVol6_N_No45 : 39|8@0+ (20,0) [0|5000] "mV" Vector__XXX
 SG_ BMS2_CellVol6_N_No46 : 47|8@0+ (20,0) [0|5000] "mV" Vector__XXX
 SG_ BMS2_CellVol6_N_No47 : 55|8@0+ (20,0) [0|5000] "mV" Vector__XXX
 SG_ BMS2_CellVol6_N_No48 : 63|8@0+ (20,0) [0|5000] "mV" Vector__XXX
 SG_ BMS2_CellVol6_N_No42 : 15|8@0+ (20,0) [0|5000] "mV" Vector__XXX

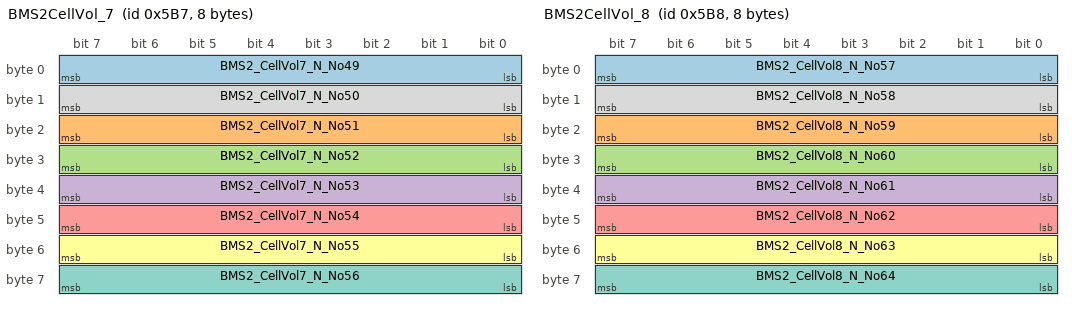
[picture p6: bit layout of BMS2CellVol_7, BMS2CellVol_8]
BO_ 1463 BMS2CellVol_7: 8 BMS2
 SG_ BMS2_CellVol7_N_No49 : 7|8@0+ (20,0) [0|5000] "mV" Vector__XXX
 SG_ BMS2_CellVol7_N_No51 : 23|8@0+ (20,0) [0|5000] "mV" Vector__XXX
 SG_ BMS2_CellVol7_N_No52 : 31|8@0+ (20,0) [0|5000] "mV" Vector__XXX
 SG_ BMS2_CellVol7_N_No53 : 39|8@0+ (20,0) [0|5000] "mV" Vector__XXX
 SG_ BMS2_CellVol7_N_No54 : 47|8@0+ (20,0) [0|5000] "mV" Vector__XXX
 SG_ BMS2_CellVol7_N_No55 : 55|8@0+ (20,0) [0|5000] "mV" Vector__XXX
 SG_ BMS2_CellVol7_N_No56 : 63|8@0+ (20,0) [0|5000] "mV" Vector__XXX
 SG_ BMS2_CellVol7_N_No50 : 15|8@0+ (20,0) [0|5000] "mV" Vector__XXX

BO_ 1464 BMS2CellVol_8: 8 BMS2
 SG_ BMS2_CellVol8_N_No57 : 7|8@0+ (20,0) [0|5000] "mV" Vector__XXX
 SG_ BMS2_CellVol8_N_No59 : 23|8@0+ (20,0) [0|5000] "mV" Vector__XXX
 SG_ BMS2_CellVol8_N_No60 : 31|8@0+ (20,0) [0|5000] "mV" Vector__XXX
 SG_ BMS2_CellVol8_N_No61 : 39|8@0+ (20,0) [0|5000] "mV" Vector__XXX
 SG_ BMS2_CellVol8_N_No62 : 47|8@0+ (20,0) [0|5000] "mV" Vector__XXX
 SG_ BMS2_CellVol8_N_No63 : 55|8@0+ (20,0) [0|5000] "mV" Vector__XXX
 SG_ BMS2_CellVol8_N_No64 : 63|8@0+ (20,0) [0|5000] "mV" Vector__XXX
 SG_ BMS2_CellVol8_N_No58 : 15|8@0+ (20,0) [0|5000] "mV" Vector__XXX

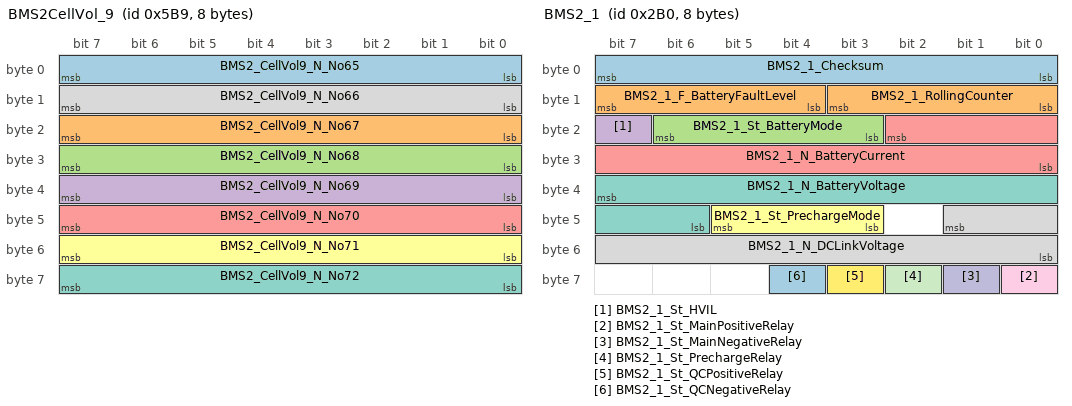
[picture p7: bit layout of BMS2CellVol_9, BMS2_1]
BO_ 1465 BMS2CellVol_9: 8 BMS2
 SG_ BMS2_CellVol9_N_No65 : 7|8@0+ (20,0) [0|5000] "mV" Vector__XXX
 SG_ BMS2_CellVol9_N_No67 : 23|8@0+ (20,0) [0|5000] "mV" Vector__XXX
 SG_ BMS2_CellVol9_N_No68 : 31|8@0+ (20,0) [0|5000] "mV" Vector__XXX
 SG_ BMS2_CellVol9_N_No69 : 39|8@0+ (20,0) [0|5000] "mV" Vector__XXX
 SG_ BMS2_CellVol9_N_No70 : 47|8@0+ (20,0) [0|5000] "mV" Vector__XXX
 SG_ BMS2_CellVol9_N_No71 : 55|8@0+ (20,0) [0|5000] "mV" Vector__XXX
 SG_ BMS2_CellVol9_N_No72 : 63|8@0+ (20,0) [0|5000] "mV" Vector__XXX
 SG_ BMS2_CellVol9_N_No66 : 15|8@0+ (20,0) [0|5000] "mV" Vector__XXX

BO_ 688 BMS2_1: 8 BMS2
 SG_ BMS2_1_Checksum : 7|8@0+ (1,0) [0|255] "" Vector__XXX
 SG_ BMS2_1_F_BatteryFaultLevel : 15|4@0+ (1,0) [0|15] "" Vector__XXX
 SG_ BMS2_1_St_BatteryMode : 22|4@0+ (1,0) [0|15] "" Vector__XXX
 SG_ BMS2_1_St_HVIL : 23|1@0+ (1,0) [0|1] "" Vector__XXX
 SG_ BMS2_1_N_BatteryCurrent : 18|11@0+ (1,-800) [-800|800] "A" Vector__XXX
 SG_ BMS2_1_St_PrechargeMode : 45|3@0+ (1,0) [0|7] "" Vector__XXX
 SG_ BMS2_1_N_BatteryVoltage : 39|10@0+ (1,0) [0|510] "V" Vector__XXX
 SG_ BMS2_1_N_DCLinkVoltage : 41|10@0+ (1,0) [0|510] "V" Vector__XXX
 SG_ BMS2_1_St_MainPositiveRelay : 56|1@0+ (1,0) [0|1] "" Vector__XXX
 SG_ BMS2_1_St_MainNegativeRelay : 57|1@0+ (1,0) [0|1] "" Vector__XXX
 SG_ BMS2_1_St_PrechargeRelay : 58|1@0+ (1,0) [0|1] "" Vector__XXX
 SG_ BMS2_1_St_QCPositiveRelay : 59|1@0+ (1,0) [0|1] "" Vector__XXX
 SG_ BMS2_1_St_QCNegativeRelay : 60|1@0+ (1,0) [0|1] "" Vector__XXX
 SG_ BMS2_1_RollingCounter : 11|4@0+ (1,0) [0|15] "" Vector__XXX

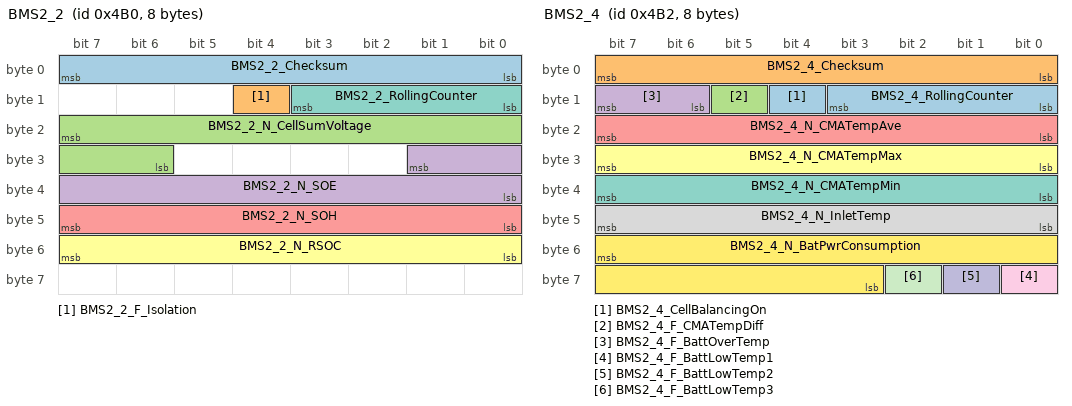
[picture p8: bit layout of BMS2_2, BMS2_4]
BO_ 1200 BMS2_2: 8 BMS2
 SG_ BMS2_2_Checksum : 7|8@0+ (1,0) [0|255] "" Vector__XXX
 SG_ BMS2_2_F_Isolation : 12|1@0+ (1,0) [0|1] "" Vector__XXX
 SG_ BMS2_2_N_CellSumVoltage : 23|10@0+ (1,0) [0|510] "V" Vector__XXX
 SG_ BMS2_2_N_SOE : 25|10@0+ (0.1,0) [0|60] "kWh" Vector__XXX
 SG_ BMS2_2_N_SOH : 47|8@0+ (0.5,0) [0|100] "%" Vector__XXX
 SG_ BMS2_2_N_RSOC : 55|8@0+ (0.5,0) [0|100] "%" Vector__XXX
 SG_ BMS2_2_RollingCounter : 11|4@0+ (1,0) [0|15] "" Vector__XXX

BO_ 1202 BMS2_4: 8 BMS2
 SG_ BMS2_4_CellBalancingOn : 12|1@0+ (1,0) [0|1] "" Vector__XXX
 SG_ BMS2_4_Checksum : 7|8@0+ (1,0) [0|255] "" Vector__XXX
 SG_ BMS2_4_F_CMATempDiff : 13|1@0+ (1,0) [0|1] "" Vector__XXX
 SG_ BMS2_4_F_BattOverTemp : 15|2@0+ (1,0) [0|3] "" Vector__XXX
 SG_ BMS2_4_N_CMATempAve : 23|8@0+ (1,-40) [-40|120] "��" Vector__XXX
 SG_ BMS2_4_N_CMATempMax : 31|8@0+ (1,-40) [-40|120] "��" Vector__XXX
 SG_ BMS2_4_N_CMATempMin : 39|8@0+ (1,-40) [-40|120] "��" Vector__XXX
 SG_ BMS2_4_N_InletTemp : 47|8@0+ (1,-40) [-40|120] "��" Vector__XXX
 SG_ BMS2_4_F_BattLowTemp1 : 56|1@0+ (1,0) [0|1] "" Vector__XXX
 SG_ BMS2_4_F_BattLowTemp2 : 57|1@0+ (1,0) [0|1] "" Vector__XXX
 SG_ BMS2_4_F_BattLowTemp3 : 58|1@0+ (1,0) [0|1] "" Vector__XXX
 SG_ BMS2_4_N_BatPwrConsumption : 55|13@0+ (0.1,-360) [-360|360] "kW" Vector__XXX
 SG_ BMS2_4_RollingCounter : 11|4@0+ (1,0) [0|15] "" Vector__XXX

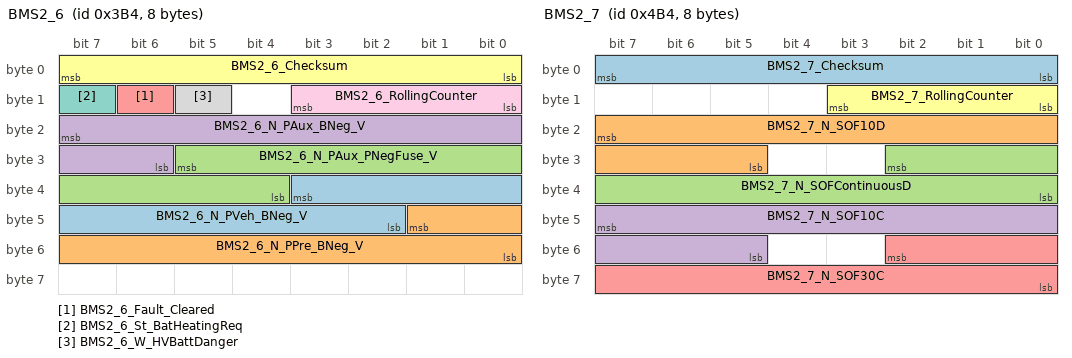
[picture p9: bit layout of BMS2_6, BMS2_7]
BO_ 948 BMS2_6: 8 BMS2
 SG_ BMS2_6_N_PVeh_BNeg_V : 35|10@0+ (1,0) [0|1023] "V" Vector__XXX
 SG_ BMS2_6_N_PPre_BNeg_V : 41|10@0+ (1,0) [0|1023] "V" Vector__XXX
 SG_ BMS2_6_N_PAux_PNegFuse_V : 29|10@0+ (1,0) [0|1023] "V" Vector__XXX
 SG_ BMS2_6_N_PAux_BNeg_V : 23|10@0+ (1,0) [0|1023] "V" Vector__XXX
 SG_ BMS2_6_Fault_Cleared : 14|1@0+ (1,0) [0|1] "" Vector__XXX
 SG_ BMS2_6_Checksum : 7|8@0+ (1,0) [0|255] "" Vector__XXX
 SG_ BMS2_6_St_BatHeatingReq : 15|1@0+ (1,0) [0|1] "" Vector__XXX
 SG_ BMS2_6_W_HVBattDanger : 13|1@0+ (1,0) [0|1] "" Vector__XXX
 SG_ BMS2_6_RollingCounter : 11|4@0+ (1,0) [0|15] "" Vector__XXX

BO_ 1204 BMS2_7: 8 BMS2
 SG_ BMS2_7_Checksum : 7|8@0+ (1,0) [0|255] "" Vector__XXX
 SG_ BMS2_7_N_SOF10D : 23|11@0+ (0.2,0) [0|409.2] "kW" Vector__XXX
 SG_ BMS2_7_N_SOFContinuousD : 26|11@0+ (0.2,0) [0|409.2] "kW" Vector__XXX
 SG_ BMS2_7_N_SOF10C : 47|11@0+ (0.2,0) [0|409.2] "kW" Vector__XXX
 SG_ BMS2_7_N_SOF30C : 50|11@0+ (0.2,0) [0|409.2] "kW" Vector__XXX
 SG_ BMS2_7_RollingCounter : 11|4@0+ (1,0) [0|15] "" Vector__XXX

BO_ 1205 BMS2_8: 8 BMS2
 SG_ BMS2_8_Checksum : 7|8@0+ (1,0) [0|255] "" Vector__XXX
 SG_ BMS2_8_N_SOF30D : 23|11@0+ (0.2,0) [0|409.2] "kW" Vector__XXX
 SG_ BMS2_8_N_SOF2D : 47|11@0+ (0.2,0) [0|409.2] "kW" Vector__XXX
 SG_ BMS2_8_N_SOF2C : 50|11@0+ (0.2,0) [0|409.2] "kW" Vector__XXX
 SG_ BMS2_8_RollingCounter : 11|4@0+ (1,0) [0|15] "" Vector__XXX

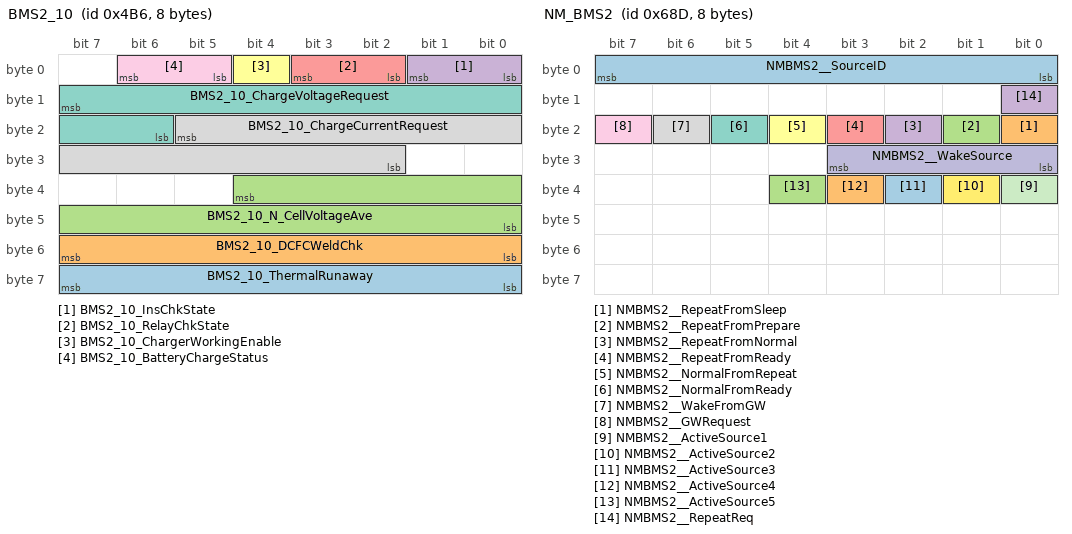
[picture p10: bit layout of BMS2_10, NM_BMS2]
BO_ 1206 BMS2_10: 8 BMS2
 SG_ BMS2_10_ThermalRunaway : 56|8@1- (1,0) [0|0] ""  BMS2
 SG_ BMS2_10_DCFCWeldChk : 48|8@1- (1,0) [0|2] ""  BMS2
 SG_ BMS2_10_N_CellVoltageAve : 36|13@0+ (1,0) [0|5000] "mV" Vector__XXX
 SG_ BMS2_10_InsChkState : 1|2@0+ (1,0) [0|3] "" Vector__XXX
 SG_ BMS2_10_RelayChkState : 3|2@0+ (1,0) [0|3] "" Vector__XXX
 SG_ BMS2_10_ChargerWorkingEnable : 4|1@0+ (1,0) [0|1] "" Vector__XXX
 SG_ BMS2_10_ChargeVoltageRequest : 15|10@0+ (1,0) [0|500] "V" Vector__XXX
 SG_ BMS2_10_ChargeCurrentRequest : 21|12@0+ (1,0) [0|4095] "A" Vector__XXX
 SG_ BMS2_10_BatteryChargeStatus : 6|2@0+ (1,0) [0|3] "" Vector__XXX

BO_ 1696 Dev_BMS2_1: 8 BMS2
 SG_ DevBMS2_1_N_ColdFanPWM : 23|8@0+ (0.4,0) [0|100] "%" Vector__XXX

BO_ 1677 NM_BMS2: 8 BMS2
 SG_ NMBMS2__SourceID : 7|8@0+ (1,0) [0|255] "" Vector__XXX
 SG_ NMBMS2__RepeatFromSleep : 16|1@0+ (1,0) [0|1] "" Vector__XXX
 SG_ NMBMS2__RepeatFromPrepare : 17|1@0+ (1,0) [0|1] "" Vector__XXX
 SG_ NMBMS2__RepeatFromNormal : 18|1@0+ (1,0) [0|1] "" Vector__XXX
 SG_ NMBMS2__RepeatFromReady : 19|1@0+ (1,0) [0|1] "" Vector__XXX
 SG_ NMBMS2__NormalFromRepeat : 20|1@0+ (1,0) [0|1] "" Vector__XXX
 SG_ NMBMS2__NormalFromReady : 21|1@0+ (1,0) [0|1] "" Vector__XXX
 SG_ NMBMS2__WakeFromGW : 22|1@0+ (1,0) [0|1] "" Vector__XXX
 SG_ NMBMS2__GWRequest : 23|1@0+ (1,0) [0|1] "" Vector__XXX
 SG_ NMBMS2__WakeSource : 27|4@0+ (1,0) [0|15] "" Vector__XXX
 SG_ NMBMS2__ActiveSource1 : 32|1@0+ (1,0) [0|1] "" Vector__XXX
 SG_ NMBMS2__ActiveSource2 : 33|1@0+ (1,0) [0|1] "" Vector__XXX
 SG_ NMBMS2__ActiveSource3 : 34|1@0+ (1,0) [0|1] "" Vector__XXX
 SG_ NMBMS2__ActiveSource4 : 35|1@0+ (1,0) [0|1] "" Vector__XXX
 SG_ NMBMS2__ActiveSource5 : 36|1@0+ (1,0) [0|1] "" Vector__XXX
 SG_ NMBMS2__RepeatReq : 8|1@0+ (1,0) [0|1] "" Vector__XXX

BO_ 883 BCM2_1: 8 Vector__XXX
 SG_ BCM2_1_Checksum : 7|8@0+ (1,0) [0|255] ""  BMS2
 SG_ BCM2_1_RollingCounter : 11|4@0+ (1,0) [0|15] ""  BMS2
 SG_ BCM2_1_St_KL15 : 13|1@0+ (1,0) [0|1] ""  BMS2
 SG_ BCM2_1_St_KLR : 14|1@0+ (1,0) [0|1] ""  BMS2
 SG_ BCM2_1_St_KL50 : 15|1@0+ (1,0) [0|1] ""  BMS2

BO_ 320 Brake2_1: 8 Vector__XXX
 SG_ BR2_1_Checksum : 7|8@0+ (1,0) [0|255] ""  BMS2
 SG_ BR2_1_RollingCounter : 11|4@0+ (1,0) [0|15] ""  BMS2
 SG_ BR2_1_F_VehicleSpeed : 39|1@0+ (1,0) [0|1] ""  BMS2
 SG_ BR2_1_N_VehicleSpeed : 38|15@0+ (0.01,0) [0|327.67] "km/h"  BMS2

BO_ 1152 ICM2_1: 8 Vector__XXX
 SG_ ICM2_1_Checksum : 7|8@0+ (1,0) [0|255] ""  BMS2
 SG_ ICM2_1_RollingCounter : 11|4@0+ (1,0) [0|15] ""  BMS2
 SG_ ICM2_1_N_Odograph : 27|20@0+ (1,0) [0|999999] "kilometer"  BMS2

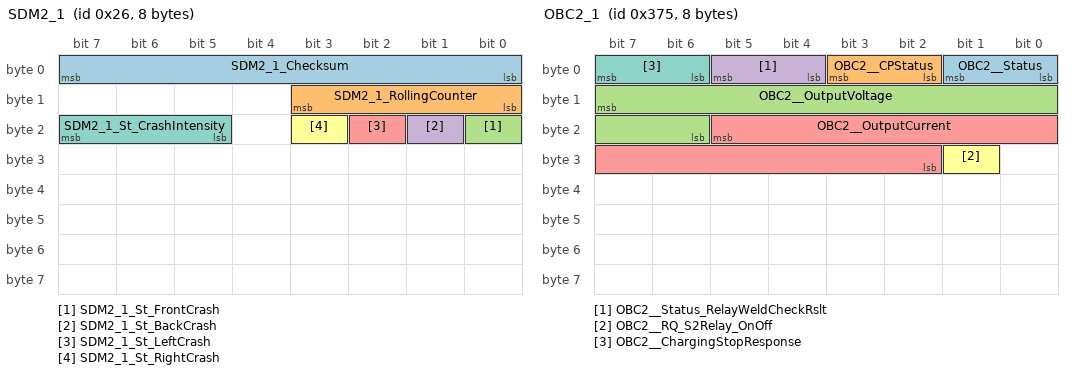
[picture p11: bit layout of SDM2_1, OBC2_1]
BO_ 38 SDM2_1: 8 Vector__XXX
 SG_ SDM2_1_Checksum : 7|8@0+ (1,0) [0|255] ""  BMS2
 SG_ SDM2_1_RollingCounter : 11|4@0+ (1,0) [0|15] ""  BMS2
 SG_ SDM2_1_St_FrontCrash : 16|1@0+ (1,0) [0|1] ""  BMS2
 SG_ SDM2_1_St_BackCrash : 17|1@0+ (1,0) [0|1] ""  BMS2
 SG_ SDM2_1_St_LeftCrash : 18|1@0+ (1,0) [0|1] ""  BMS2
 SG_ SDM2_1_St_RightCrash : 19|1@0+ (1,0) [0|1] ""  BMS2
 SG_ SDM2_1_St_CrashIntensity : 23|3@0+ (1,0) [0|7] ""  BMS2

BO_ 885 OBC2_1: 8 Vector__XXX
 SG_ OBC2__Status : 1|2@0+ (1,0) [0|3] ""  BMS2
 SG_ OBC2__CPStatus : 3|2@0+ (1,0) [0|3] ""  BMS2
 SG_ OBC2__OutputVoltage : 15|10@0+ (1,0) [0|500] "V"  BMS2
 SG_ OBC2__Status_RelayWeldCheckRslt : 5|2@0+ (1,0) [0|3] ""  BMS2
 SG_ OBC2__OutputCurrent : 21|12@0+ (0.01,0) [0|40.94] "A"  BMS2
 SG_ OBC2__RQ_S2Relay_OnOff : 25|1@0+ (1,0) [0|1] ""  BMS2
 SG_ OBC2__ChargingStopResponse : 7|2@0+ (1,0) [0|3] ""  BMS2

BO_ 1453 BMS1_CMATemp_Fr01: 8 BMS1
 SG_ BMSCMATemp_N_No48 m3 : 60|5@0+ (3,-28) [-28|65] "degC" Vector__XXX
 SG_ BMSCMATemp_N_No47 m3 : 49|5@0+ (3,-28) [-28|65] "degC" Vector__XXX
 SG_ BMSCMATemp_N_No46 m3 : 54|5@0+ (3,-28) [-28|65] "degC" Vector__XXX
 SG_ BMSCMATemp_N_No45 m3 : 43|5@0+ (3,-28) [-28|65] "degC" Vector__XXX
 SG_ BMSCMATemp_N_No44 m3 : 32|5@0+ (3,-28) [-28|65] "degC" Vector__XXX
 SG_ BMSCMATemp_N_No43 m3 : 37|5@0+ (3,-28) [-28|65] "degC" Vector__XXX
 SG_ BMSCMATemp_N_No42 m3 : 26|5@0+ (3,-28) [-28|65] "degC" Vector__XXX
 SG_ BMSCMATemp_N_No41 m3 : 31|5@0+ (3,-28) [-28|65] "degC" Vector__XXX
 SG_ BMSCMATemp_N_No40 m3 : 20|5@0+ (3,-28) [-28|65] "degC" Vector__XXX
 SG_ BMSCMATemp_N_No39 m3 : 9|5@0+ (3,-28) [-28|65] "degC" Vector__XXX
 SG_ BMSCMATemp_N_No38 m3 : 14|5@0+ (3,-28) [-28|65] "degC" Vector__XXX
 SG_ BMSCMATemp_N_No37 m3 : 3|5@0+ (3,-28) [-28|65] "degC" Vector__XXX
 SG_ BMSCMATemp_N_No36 m2 : 60|5@0+ (3,-28) [-28|65] "degC" Vector__XXX
 SG_ BMSCMATemp_N_No35 m2 : 49|5@0+ (3,-28) [-28|65] "degC" Vector__XXX
 SG_ BMSCMATemp_N_No34 m2 : 54|5@0+ (3,-28) [-28|65] "degC" Vector__XXX
 SG_ BMSCMATemp_N_No33 m2 : 43|5@0+ (3,-28) [-28|65] "degC" Vector__XXX
 SG_ BMSCMATemp_N_No32 m2 : 32|5@0+ (3,-28) [-28|65] "degC" Vector__XXX
 SG_ BMSCMATemp_N_No31 m2 : 37|5@0+ (3,-28) [-28|65] "degC" Vector__XXX
 SG_ BMSCMATemp_N_No30 m2 : 26|5@0+ (3,-28) [-28|65] "degC" Vector__XXX
 SG_ BMSCMATemp_N_No29 m2 : 31|5@0+ (3,-28) [-28|65] "degC" Vector__XXX
 SG_ BMSCMATemp_N_No28 m2 : 20|5@0+ (3,-28) [-28|65] "degC" Vector__XXX
 SG_ BMSCMATemp_N_No27 m2 : 9|5@0+ (3,-28) [-28|65] "degC" Vector__XXX
 SG_ BMSCMATemp_N_No26 m2 : 14|5@0+ (3,-28) [-28|65] "degC" Vector__XXX
 SG_ BMSCMATemp_N_No25 m2 : 3|5@0+ (3,-28) [-28|65] "degC" Vector__XXX
 SG_ BMSCMATemp_N_No24 m1 : 60|5@0+ (3,-28) [-28|65] "degC" Vector__XXX
 SG_ BMSCMATemp_N_No23 m1 : 49|5@0+ (3,-28) [-28|65] "degC" Vector__XXX
 SG_ BMSCMATemp_N_No22 m1 : 54|5@0+ (3,-28) [-28|65] "degC" Vector__XXX
 SG_ BMSCMATemp_N_No21 m1 : 43|5@0+ (3,-28) [-28|65] "degC" Vector__XXX
 SG_ BMSCMATemp_N_No20 m1 : 32|5@0+ (3,-28) [-28|65] "degC" Vector__XXX
 SG_ BMSCMATemp_N_No19 m1 : 37|5@0+ (3,-28) [-28|65] "degC" Vector__XXX
 SG_ BMSCMATemp_N_No18 m1 : 26|5@0+ (3,-28) [-28|65] "degC" Vector__XXX
 SG_ BMSCMATemp_N_No17 m1 : 31|5@0+ (3,-28) [-28|65] "degC" Vector__XXX
 SG_ BMSCMATemp_N_No16 m1 : 20|5@0+ (3,-28) [-28|65] "degC" Vector__XXX
 SG_ BMSCMATemp_N_No15 m1 : 9|5@0+ (3,-28) [-28|65] "degC" Vector__XXX
 SG_ BMSCMATemp_N_No14 m1 : 14|5@0+ (3,-28) [-28|65] "degC" Vector__XXX
 SG_ BMSCMATemp_N_No13 m1 : 3|5@0+ (3,-28) [-28|65] "degC" Vector__XXX
 SG_ BMSCMATemp_Multiplexer M : 7|4@0+ (1,0) [0|15] "" Vector__XXX
 SG_ BMSCMATemp_N_No9 m0 : 43|5@0+ (3,-28) [-28|65] "degC" Vector__XXX
 SG_ BMSCMATemp_N_No12 m0 : 60|5@0+ (3,-28) [-28|65] "degC" Vector__XXX
 SG_ BMSCMATemp_N_No11 m0 : 49|5@0+ (3,-28) [-28|65] "degC" Vector__XXX
 SG_ BMSCMATemp_N_No10 m0 : 54|5@0+ (3,-28) [-28|65] "degC" Vector__XXX
 SG_ BMSCMATemp_N_No1 m0 : 3|5@0+ (3,-28) [-28|65] "degC" Vector__XXX
 SG_ BMSCMATemp_N_No3 m0 : 9|5@0+ (3,-28) [-28|65] "degC" Vector__XXX
 SG_ BMSCMATemp_N_No4 m0 : 20|5@0+ (3,-28) [-28|65] "degC" Vector__XXX
 SG_ BMSCMATemp_N_No5 m0 : 31|5@0+ (3,-28) [-28|65] "degC" Vector__XXX
 SG_ BMSCMATemp_N_No6 m0 : 26|5@0+ (3,-28) [-28|65] "degC" Vector__XXX
 SG_ BMSCMATemp_N_No7 m0 : 37|5@0+ (3,-28) [-28|65] "degC" Vector__XXX
 SG_ BMSCMATemp_N_No8 m0 : 32|5@0+ (3,-28) [-28|65] "degC" Vector__XXX
 SG_ BMSCMATemp_N_No2 m0 : 14|5@0+ (3,-28) [-28|65] "��" Vector__XXX

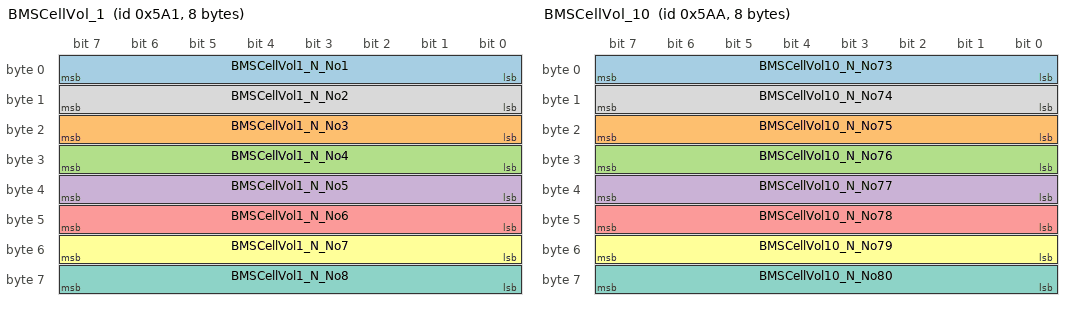
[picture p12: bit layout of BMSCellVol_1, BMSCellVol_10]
BO_ 1441 BMSCellVol_1: 8 BMS1
 SG_ BMSCellVol1_N_No1 : 7|8@0+ (20,0) [0|5000] "mV" Vector__XXX
 SG_ BMSCellVol1_N_No3 : 23|8@0+ (20,0) [0|5000] "mV" Vector__XXX
 SG_ BMSCellVol1_N_No4 : 31|8@0+ (20,0) [0|5000] "mV" Vector__XXX
 SG_ BMSCellVol1_N_No5 : 39|8@0+ (20,0) [0|5000] "mV" Vector__XXX
 SG_ BMSCellVol1_N_No6 : 47|8@0+ (20,0) [0|5000] "mV" Vector__XXX
 SG_ BMSCellVol1_N_No7 : 55|8@0+ (20,0) [0|5000] "mV" Vector__XXX
 SG_ BMSCellVol1_N_No8 : 63|8@0+ (20,0) [0|5000] "mV" Vector__XXX
 SG_ BMSCellVol1_N_No2 : 15|8@0+ (20,0) [0|5000] "mV" Vector__XXX

BO_ 1450 BMSCellVol_10: 8 BMS1
 SG_ BMSCellVol10_N_No73 : 7|8@0+ (20,0) [0|5000] "mV" Vector__XXX
 SG_ BMSCellVol10_N_No75 : 23|8@0+ (20,0) [0|5000] "mV" Vector__XXX
 SG_ BMSCellVol10_N_No76 : 31|8@0+ (20,0) [0|5000] "mV" Vector__XXX
 SG_ BMSCellVol10_N_No77 : 39|8@0+ (20,0) [0|5000] "mV" Vector__XXX
 SG_ BMSCellVol10_N_No78 : 47|8@0+ (20,0) [0|5000] "mV" Vector__XXX
 SG_ BMSCellVol10_N_No79 : 55|8@0+ (20,0) [0|5000] "mV" Vector__XXX
 SG_ BMSCellVol10_N_No80 : 63|8@0+ (20,0) [0|5000] "mV" Vector__XXX
 SG_ BMSCellVol10_N_No74 : 15|8@0+ (20,0) [0|5000] "mV" Vector__XXX

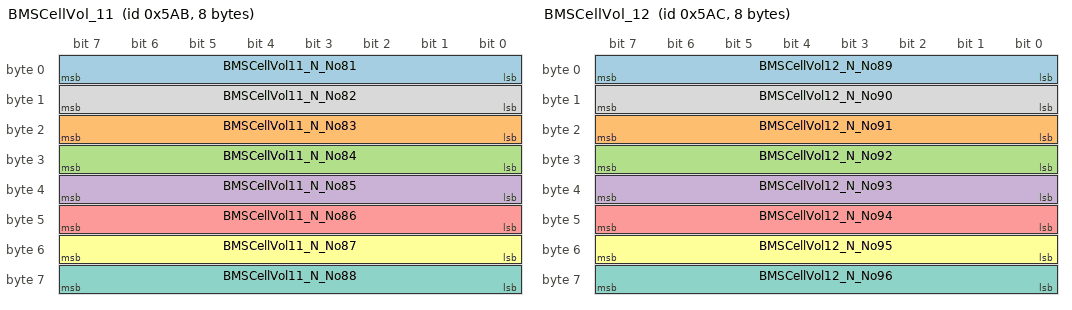
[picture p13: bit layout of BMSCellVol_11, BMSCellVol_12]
BO_ 1451 BMSCellVol_11: 8 BMS1
 SG_ BMSCellVol11_N_No81 : 7|8@0+ (20,0) [0|5000] "mV" Vector__XXX
 SG_ BMSCellVol11_N_No83 : 23|8@0+ (20,0) [0|5000] "mV" Vector__XXX
 SG_ BMSCellVol11_N_No84 : 31|8@0+ (20,0) [0|5000] "mV" Vector__XXX
 SG_ BMSCellVol11_N_No85 : 39|8@0+ (20,0) [0|5000] "mV" Vector__XXX
 SG_ BMSCellVol11_N_No86 : 47|8@0+ (20,0) [0|5000] "mV" Vector__XXX
 SG_ BMSCellVol11_N_No87 : 55|8@0+ (20,0) [0|5000] "mV" Vector__XXX
 SG_ BMSCellVol11_N_No88 : 63|8@0+ (20,0) [0|5000] "mV" Vector__XXX
 SG_ BMSCellVol11_N_No82 : 15|8@0+ (20,0) [0|5000] "mV" Vector__XXX

BO_ 1452 BMSCellVol_12: 8 BMS1
 SG_ BMSCellVol12_N_No89 : 7|8@0+ (20,0) [0|5000] "mV" Vector__XXX
 SG_ BMSCellVol12_N_No91 : 23|8@0+ (20,0) [0|5000] "mV" Vector__XXX
 SG_ BMSCellVol12_N_No92 : 31|8@0+ (20,0) [0|5000] "mV" Vector__XXX
 SG_ BMSCellVol12_N_No93 : 39|8@0+ (20,0) [0|5000] "mV" Vector__XXX
 SG_ BMSCellVol12_N_No94 : 47|8@0+ (20,0) [0|5000] "mV" Vector__XXX
 SG_ BMSCellVol12_N_No95 : 55|8@0+ (20,0) [0|5000] "mV" Vector__XXX
 SG_ BMSCellVol12_N_No96 : 63|8@0+ (20,0) [0|5000] "mV" Vector__XXX
 SG_ BMSCellVol12_N_No90 : 15|8@0+ (20,0) [0|5000] "mV" Vector__XXX

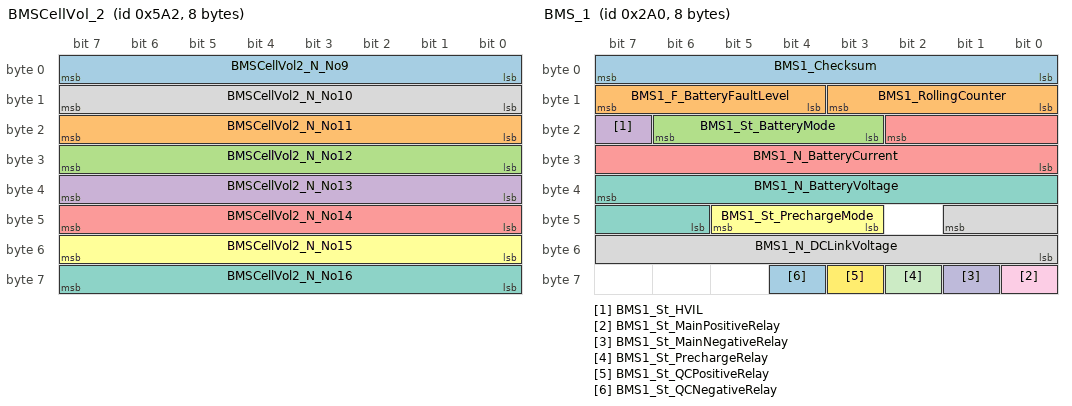
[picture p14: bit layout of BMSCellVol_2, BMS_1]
BO_ 1442 BMSCellVol_2: 8 BMS1
 SG_ BMSCellVol2_N_No9 : 7|8@0+ (20,0) [0|5000] "mV" Vector__XXX
 SG_ BMSCellVol2_N_No11 : 23|8@0+ (20,0) [0|5000] "mV" Vector__XXX
 SG_ BMSCellVol2_N_No12 : 31|8@0+ (20,0) [0|5000] "mV" Vector__XXX
 SG_ BMSCellVol2_N_No13 : 39|8@0+ (20,0) [0|5000] "mV" Vector__XXX
 SG_ BMSCellVol2_N_No14 : 47|8@0+ (20,0) [0|5000] "mV" Vector__XXX
 SG_ BMSCellVol2_N_No15 : 55|8@0+ (20,0) [0|5000] "mV" Vector__XXX
 SG_ BMSCellVol2_N_No16 : 63|8@0+ (20,0) [0|5000] "mV" Vector__XXX
 SG_ BMSCellVol2_N_No10 : 15|8@0+ (20,0) [0|5000] "mV" Vector__XXX

BO_ 1443 BMSCellVol_3: 8 BMS1
 SG_ BMSCellVol3_N_No17 : 7|8@0+ (20,0) [0|5000] "mV" Vector__XXX
 SG_ BMSCellVol3_N_No19 : 23|8@0+ (20,0) [0|5000] "mV" Vector__XXX
 SG_ BMSCellVol3_N_No20 : 31|8@0+ (20,0) [0|5000] "mV" Vector__XXX
 SG_ BMSCellVol3_N_No21 : 39|8@0+ (20,0) [0|5000] "mV" Vector__XXX
 SG_ BMSCellVol3_N_No22 : 47|8@0+ (20,0) [0|5000] "mV" Vector__XXX
 SG_ BMSCellVol3_N_No23 : 55|8@0+ (20,0) [0|5000] "mV" Vector__XXX
 SG_ BMSCellVol3_N_No24 : 63|8@0+ (20,0) [0|5000] "mV" Vector__XXX
 SG_ BMSCellVol3_N_No18 : 15|8@0+ (20,0) [0|5000] "mV" Vector__XXX

BO_ 1444 BMSCellVol_4: 8 BMS1
 SG_ BMSCellVol4_N_No25 : 7|8@0+ (20,0) [0|5000] "mV" Vector__XXX
 SG_ BMSCellVol4_N_No27 : 23|8@0+ (20,0) [0|5000] "mV" Vector__XXX
 SG_ BMSCellVol4_N_No28 : 31|8@0+ (20,0) [0|5000] "mV" Vector__XXX
 SG_ BMSCellVol4_N_No29 : 39|8@0+ (20,0) [0|5000] "mV" Vector__XXX
 SG_ BMSCellVol4_N_No30 : 47|8@0+ (20,0) [0|5000] "mV" Vector__XXX
 SG_ BMSCellVol4_N_No31 : 55|8@0+ (20,0) [0|5000] "mV" Vector__XXX
 SG_ BMSCellVol4_N_No32 : 63|8@0+ (20,0) [0|5000] "mV" Vector__XXX
 SG_ BMSCellVol4_N_No26 : 15|8@0+ (20,0) [0|5000] "mV" Vector__XXX

BO_ 1445 BMSCellVol_5: 8 BMS1
 SG_ BMSCellVol5_N_No33 : 7|8@0+ (20,0) [0|5000] "mV" Vector__XXX
 SG_ BMSCellVol5_N_No35 : 23|8@0+ (20,0) [0|5000] "mV" Vector__XXX
 SG_ BMSCellVol5_N_No36 : 31|8@0+ (20,0) [0|5000] "mV" Vector__XXX
 SG_ BMSCellVol5_N_No37 : 39|8@0+ (20,0) [0|5000] "mV" Vector__XXX
 SG_ BMSCellVol5_N_No38 : 47|8@0+ (20,0) [0|5000] "mV" Vector__XXX
 SG_ BMSCellVol5_N_No39 : 55|8@0+ (20,0) [0|5000] "mV" Vector__XXX
 SG_ BMSCellVol5_N_No40 : 63|8@0+ (20,0) [0|5000] "mV" Vector__XXX
 SG_ BMSCellVol5_N_No34 : 15|8@0+ (20,0) [0|5000] "mV" Vector__XXX

BO_ 1446 BMSCellVol_6: 8 BMS1
 SG_ BMSCellVol6_N_No41 : 7|8@0+ (20,0) [0|5000] "mV" Vector__XXX
 SG_ BMSCellVol6_N_No43 : 23|8@0+ (20,0) [0|5000] "mV" Vector__XXX
 SG_ BMSCellVol6_N_No44 : 31|8@0+ (20,0) [0|5000] "mV" Vector__XXX
 SG_ BMSCellVol6_N_No45 : 39|8@0+ (20,0) [0|5000] "mV" Vector__XXX
 SG_ BMSCellVol6_N_No46 : 47|8@0+ (20,0) [0|5000] "mV" Vector__XXX
 SG_ BMSCellVol6_N_No47 : 55|8@0+ (20,0) [0|5000] "mV" Vector__XXX
 SG_ BMSCellVol6_N_No48 : 63|8@0+ (20,0) [0|5000] "mV" Vector__XXX
 SG_ BMSCellVol6_N_No42 : 15|8@0+ (20,0) [0|5000] "mV" Vector__XXX

BO_ 1447 BMSCellVol_7: 8 BMS1
 SG_ BMSCellVol7_N_No49 : 7|8@0+ (20,0) [0|5000] "mV" Vector__XXX
 SG_ BMSCellVol7_N_No51 : 23|8@0+ (20,0) [0|5000] "mV" Vector__XXX
 SG_ BMSCellVol7_N_No52 : 31|8@0+ (20,0) [0|5000] "mV" Vector__XXX
 SG_ BMSCellVol7_N_No53 : 39|8@0+ (20,0) [0|5000] "mV" Vector__XXX
 SG_ BMSCellVol7_N_No54 : 47|8@0+ (20,0) [0|5000] "mV" Vector__XXX
 SG_ BMSCellVol7_N_No55 : 55|8@0+ (20,0) [0|5000] "mV" Vector__XXX
 SG_ BMSCellVol7_N_No56 : 63|8@0+ (20,0) [0|5000] "mV" Vector__XXX
 SG_ BMSCellVol7_N_No50 : 15|8@0+ (20,0) [0|5000] "mV" Vector__XXX

BO_ 1448 BMSCellVol_8: 8 BMS1
 SG_ BMSCellVol8_N_No57 : 7|8@0+ (20,0) [0|5000] "mV" Vector__XXX
 SG_ BMSCellVol8_N_No59 : 23|8@0+ (20,0) [0|5000] "mV" Vector__XXX
 SG_ BMSCellVol8_N_No60 : 31|8@0+ (20,0) [0|5000] "mV" Vector__XXX
 SG_ BMSCellVol8_N_No61 : 39|8@0+ (20,0) [0|5000] "mV" Vector__XXX
 SG_ BMSCellVol8_N_No62 : 47|8@0+ (20,0) [0|5000] "mV" Vector__XXX
 SG_ BMSCellVol8_N_No63 : 55|8@0+ (20,0) [0|5000] "mV" Vector__XXX
 SG_ BMSCellVol8_N_No64 : 63|8@0+ (20,0) [0|5000] "mV" Vector__XXX
 SG_ BMSCellVol8_N_No58 : 15|8@0+ (20,0) [0|5000] "mV" Vector__XXX

BO_ 1449 BMSCellVol_9: 8 BMS1
 SG_ BMSCellVol9_N_No65 : 7|8@0+ (20,0) [0|5000] "mV" Vector__XXX
 SG_ BMSCellVol9_N_No67 : 23|8@0+ (20,0) [0|5000] "mV" Vector__XXX
 SG_ BMSCellVol9_N_No68 : 31|8@0+ (20,0) [0|5000] "mV" Vector__XXX
 SG_ BMSCellVol9_N_No69 : 39|8@0+ (20,0) [0|5000] "mV" Vector__XXX
 SG_ BMSCellVol9_N_No70 : 47|8@0+ (20,0) [0|5000] "mV" Vector__XXX
 SG_ BMSCellVol9_N_No71 : 55|8@0+ (20,0) [0|5000] "mV" Vector__XXX
 SG_ BMSCellVol9_N_No72 : 63|8@0+ (20,0) [0|5000] "mV" Vector__XXX
 SG_ BMSCellVol9_N_No66 : 15|8@0+ (20,0) [0|5000] "mV" Vector__XXX

BO_ 672 BMS_1: 8 BMS1
 SG_ BMS1_Checksum : 7|8@0+ (1,0) [0|255] "" Vector__XXX
 SG_ BMS1_F_BatteryFaultLevel : 15|4@0+ (1,0) [0|15] "" Vector__XXX
 SG_ BMS1_St_BatteryMode : 22|4@0+ (1,0) [0|15] "" Vector__XXX
 SG_ BMS1_St_HVIL : 23|1@0+ (1,0) [0|1] "" Vector__XXX
 SG_ BMS1_N_BatteryCurrent : 18|11@0+ (1,-800) [-800|800] "A" Vector__XXX
 SG_ BMS1_St_PrechargeMode : 45|3@0+ (1,0) [0|7] "" Vector__XXX
 SG_ BMS1_N_BatteryVoltage : 39|10@0+ (1,0) [0|510] "V" Vector__XXX
 SG_ BMS1_N_DCLinkVoltage : 41|10@0+ (1,0) [0|510] "V" Vector__XXX
 SG_ BMS1_St_MainPositiveRelay : 56|1@0+ (1,0) [0|1] "" Vector__XXX
 SG_ BMS1_St_MainNegativeRelay : 57|1@0+ (1,0) [0|1] "" Vector__XXX
 SG_ BMS1_St_PrechargeRelay : 58|1@0+ (1,0) [0|1] "" Vector__XXX
 SG_ BMS1_St_QCPositiveRelay : 59|1@0+ (1,0) [0|1] "" Vector__XXX
 SG_ BMS1_St_QCNegativeRelay : 60|1@0+ (1,0) [0|1] "" Vector__XXX
 SG_ BMS1_RollingCounter : 11|4@0+ (1,0) [0|15] "" Vector__XXX

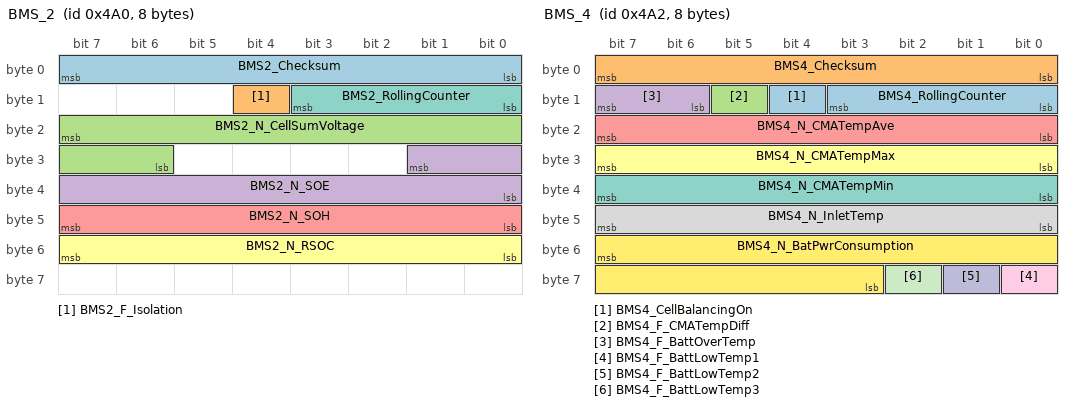
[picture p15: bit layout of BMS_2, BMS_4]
BO_ 1184 BMS_2: 8 BMS1
 SG_ BMS2_Checksum : 7|8@0+ (1,0) [0|255] "" Vector__XXX
 SG_ BMS2_F_Isolation : 12|1@0+ (1,0) [0|1] "" Vector__XXX
 SG_ BMS2_N_CellSumVoltage : 23|10@0+ (1,0) [0|510] "V" Vector__XXX
 SG_ BMS2_N_SOE : 25|10@0+ (0.1,0) [0|60] "kWh" Vector__XXX
 SG_ BMS2_N_SOH : 47|8@0+ (0.5,0) [0|100] "%" Vector__XXX
 SG_ BMS2_N_RSOC : 55|8@0+ (0.5,0) [0|100] "%" Vector__XXX
 SG_ BMS2_RollingCounter : 11|4@0+ (1,0) [0|15] "" Vector__XXX

BO_ 1186 BMS_4: 8 BMS1
 SG_ BMS4_CellBalancingOn : 12|1@0+ (1,0) [0|1] "" Vector__XXX
 SG_ BMS4_Checksum : 7|8@0+ (1,0) [0|255] "" Vector__XXX
 SG_ BMS4_F_CMATempDiff : 13|1@0+ (1,0) [0|1] "" Vector__XXX
 SG_ BMS4_F_BattOverTemp : 15|2@0+ (1,0) [0|3] "" Vector__XXX
 SG_ BMS4_N_CMATempAve : 23|8@0+ (1,-40) [-40|120] "��" Vector__XXX
 SG_ BMS4_N_CMATempMax : 31|8@0+ (1,-40) [-40|120] "��" Vector__XXX
 SG_ BMS4_N_CMATempMin : 39|8@0+ (1,-40) [-40|120] "��" Vector__XXX
 SG_ BMS4_N_InletTemp : 47|8@0+ (1,-40) [-40|120] "��" Vector__XXX
 SG_ BMS4_F_BattLowTemp1 : 56|1@0+ (1,0) [0|1] "" Vector__XXX
 SG_ BMS4_F_BattLowTemp2 : 57|1@0+ (1,0) [0|1] "" Vector__XXX
 SG_ BMS4_F_BattLowTemp3 : 58|1@0+ (1,0) [0|1] "" Vector__XXX
 SG_ BMS4_N_BatPwrConsumption : 55|13@0+ (0.1,-360) [-360|360] "kW" Vector__XXX
 SG_ BMS4_RollingCounter : 11|4@0+ (1,0) [0|15] "" Vector__XXX

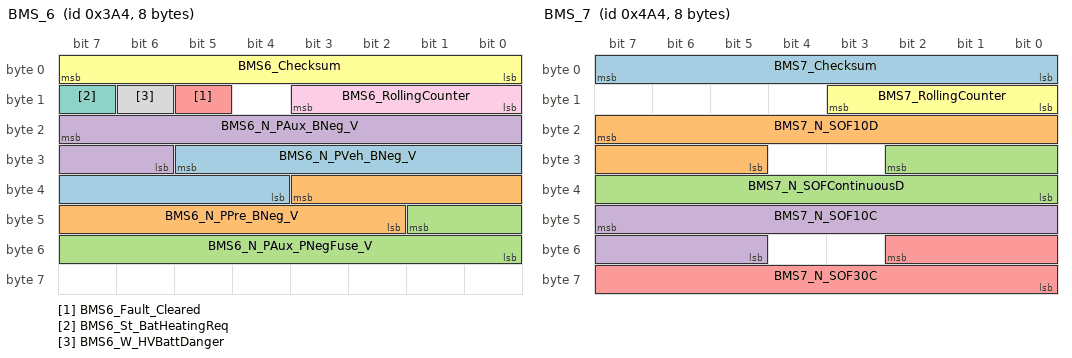
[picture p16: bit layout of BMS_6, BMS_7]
BO_ 932 BMS_6: 8 BMS1
 SG_ BMS6_N_PVeh_BNeg_V : 29|10@0+ (1,0) [0|1023] "V" Vector__XXX
 SG_ BMS6_N_PPre_BNeg_V : 35|10@0+ (1,0) [0|1023] "V" Vector__XXX
 SG_ BMS6_N_PAux_PNegFuse_V : 41|10@0+ (1,0) [0|1023] "V" Vector__XXX
 SG_ BMS6_N_PAux_BNeg_V : 23|10@0+ (1,0) [0|1023] "V" Vector__XXX
 SG_ BMS6_Fault_Cleared : 13|1@0+ (1,0) [0|1] "" Vector__XXX
 SG_ BMS6_Checksum : 7|8@0+ (1,0) [0|255] "" Vector__XXX
 SG_ BMS6_St_BatHeatingReq : 15|1@0+ (1,0) [0|1] "" Vector__XXX
 SG_ BMS6_W_HVBattDanger : 14|1@0+ (1,0) [0|1] "" Vector__XXX
 SG_ BMS6_RollingCounter : 11|4@0+ (1,0) [0|15] "" Vector__XXX

BO_ 1188 BMS_7: 8 BMS1
 SG_ BMS7_Checksum : 7|8@0+ (1,0) [0|255] "" Vector__XXX
 SG_ BMS7_N_SOF10D : 23|11@0+ (0.2,0) [0|409.2] "kW" Vector__XXX
 SG_ BMS7_N_SOFContinuousD : 26|11@0+ (0.2,0) [0|409.2] "kW" Vector__XXX
 SG_ BMS7_N_SOF10C : 47|11@0+ (0.2,0) [0|409.2] "kW" Vector__XXX
 SG_ BMS7_N_SOF30C : 50|11@0+ (0.2,0) [0|409.2] "kW" Vector__XXX
 SG_ BMS7_RollingCounter : 11|4@0+ (1,0) [0|15] "" Vector__XXX

BO_ 1189 BMS_8: 8 BMS1
 SG_ BMS8_Checksum : 7|8@0+ (1,0) [0|255] "" Vector__XXX
 SG_ BMS8_N_SOF30D : 23|11@0+ (0.2,0) [0|409.2] "kW" Vector__XXX
 SG_ BMS8_N_SOF2D : 47|11@0+ (0.2,0) [0|409.2] "kW" Vector__XXX
 SG_ BMS8_N_SOF2C : 50|11@0+ (0.2,0) [0|409.2] "kW" Vector__XXX
 SG_ BMS8_RollingCounter : 11|4@0+ (1,0) [0|15] "" Vector__XXX

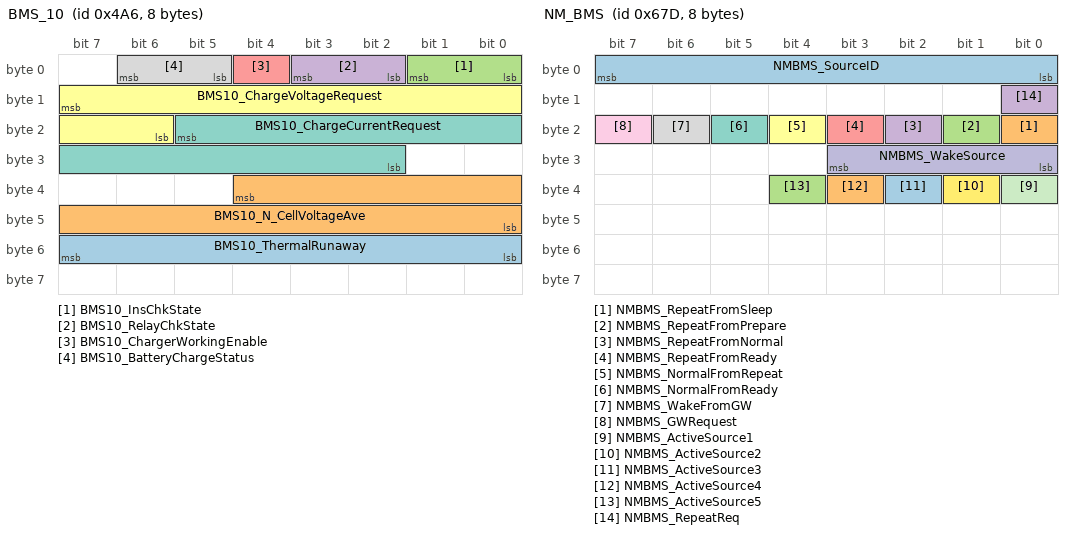
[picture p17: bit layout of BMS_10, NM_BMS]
BO_ 1190 BMS_10: 8 BMS1
 SG_ BMS10_ThermalRunaway : 48|8@1- (1,0) [0|0] ""  BMS1
 SG_ BMS10_N_CellVoltageAve : 36|13@0+ (1,0) [0|5000] "mV" Vector__XXX
 SG_ BMS10_InsChkState : 1|2@0+ (1,0) [0|3] "" Vector__XXX
 SG_ BMS10_RelayChkState : 3|2@0+ (1,0) [0|3] "" Vector__XXX
 SG_ BMS10_ChargerWorkingEnable : 4|1@0+ (1,0) [0|1] "" Vector__XXX
 SG_ BMS10_ChargeVoltageRequest : 15|10@0+ (1,0) [0|500] "" Vector__XXX
 SG_ BMS10_ChargeCurrentRequest : 21|12@0+ (1,0) [0|4095] "A" Vector__XXX
 SG_ BMS10_BatteryChargeStatus : 6|2@0+ (1,0) [0|3] "" Vector__XXX

BO_ 1680 Dev_BMS_1: 8 BMS1
 SG_ DevBMS1_N_ColdFanPWM : 23|8@0+ (0.4,0) [0|100] "%" Vector__XXX

BO_ 1661 NM_BMS: 8 BMS1
 SG_ NMBMS_SourceID : 7|8@0+ (1,0) [0|255] "" Vector__XXX
 SG_ NMBMS_RepeatFromSleep : 16|1@0+ (1,0) [0|1] "" Vector__XXX
 SG_ NMBMS_RepeatFromPrepare : 17|1@0+ (1,0) [0|1] "" Vector__XXX
 SG_ NMBMS_RepeatFromNormal : 18|1@0+ (1,0) [0|1] "" Vector__XXX
 SG_ NMBMS_RepeatFromReady : 19|1@0+ (1,0) [0|1] "" Vector__XXX
 SG_ NMBMS_NormalFromRepeat : 20|1@0+ (1,0) [0|1] "" Vector__XXX
 SG_ NMBMS_NormalFromReady : 21|1@0+ (1,0) [0|1] "" Vector__XXX
 SG_ NMBMS_WakeFromGW : 22|1@0+ (1,0) [0|1] "" Vector__XXX
 SG_ NMBMS_GWRequest : 23|1@0+ (1,0) [0|1] "" Vector__XXX
 SG_ NMBMS_WakeSource : 27|4@0+ (1,0) [0|15] "" Vector__XXX
 SG_ NMBMS_ActiveSource1 : 32|1@0+ (1,0) [0|1] "" Vector__XXX
 SG_ NMBMS_ActiveSource2 : 33|1@0+ (1,0) [0|1] "" Vector__XXX
 SG_ NMBMS_ActiveSource3 : 34|1@0+ (1,0) [0|1] "" Vector__XXX
 SG_ NMBMS_ActiveSource4 : 35|1@0+ (1,0) [0|1] "" Vector__XXX
 SG_ NMBMS_ActiveSource5 : 36|1@0+ (1,0) [0|1] "" Vector__XXX
 SG_ NMBMS_RepeatReq : 8|1@0+ (1,0) [0|1] "" Vector__XXX

BO_ 1848 Diag_BMS_Resp: 8 BMS1
 SG_ Diag_BMS_Resp_b0 : 7|8@0+ (1,0) [0|255] "" Vector__XXX
 SG_ Diag_BMS_Resp_b2 : 23|8@0+ (1,0) [0|255] "" Vector__XXX
 SG_ Diag_BMS_Resp_b3 : 31|8@0+ (1,0) [0|255] "" Vector__XXX
 SG_ Diag_BMS_Resp_b4 : 39|8@0+ (1,0) [0|255] "" Vector__XXX
 SG_ Diag_BMS_Resp_b5 : 47|8@0+ (1,0) [0|255] "" Vector__XXX
 SG_ Diag_BMS_Resp_b6 : 55|8@0+ (1,0) [0|255] "" Vector__XXX
 SG_ Diag_BMS_Resp_b7 : 63|8@0+ (1,0) [0|255] "" Vector__XXX
 SG_ Diag_BMS_Resp_b1 : 15|8@0+ (1,0) [0|255] "" Vector__XXX

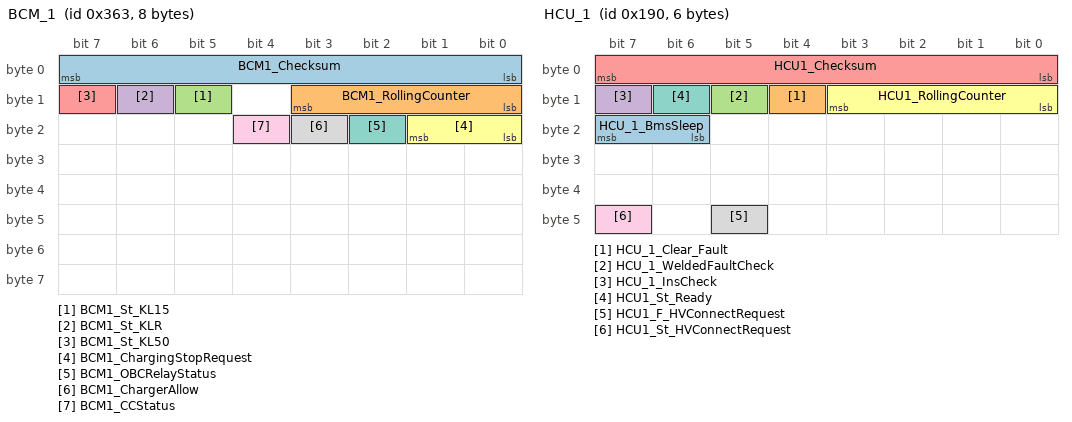
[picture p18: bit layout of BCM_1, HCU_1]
BO_ 867 BCM_1: 8 Vector__XXX
 SG_ BCM1_Checksum : 7|8@0+ (1,0) [0|255] ""  BMS1
 SG_ BCM1_RollingCounter : 11|4@0+ (1,0) [0|15] ""  BMS1
 SG_ BCM1_St_KL15 : 13|1@0+ (1,0) [0|1] ""  BMS1
 SG_ BCM1_St_KLR : 14|1@0+ (1,0) [0|1] ""  BMS1
 SG_ BCM1_St_KL50 : 15|1@0+ (1,0) [0|1] ""  BMS1
 SG_ BCM1_ChargingStopRequest : 17|2@0+ (1,0) [0|3] ""  BMS1
 SG_ BCM1_OBCRelayStatus : 18|1@0+ (1,0) [0|1] ""  BMS1
 SG_ BCM1_ChargerAllow : 19|1@0+ (1,0) [0|1] ""  BMS1
 SG_ BCM1_CCStatus : 20|1@0+ (1,0) [0|1] ""  BMS1

BO_ 304 Brake_1: 8 Vector__XXX
 SG_ BR1_Checksum : 7|8@0+ (1,0) [0|255] ""  BMS1
 SG_ BR1_RollingCounter : 11|4@0+ (1,0) [0|15] ""  BMS1
 SG_ BR1_F_VehicleSpeed : 39|1@0+ (1,0) [0|1] ""  BMS1
 SG_ BR1_N_VehicleSpeed : 38|15@0+ (0.01,0) [0|327.67] "km/h"  BMS1

BO_ 400 HCU_1: 6 Vector__XXX
 SG_ HCU_1_BmsSleep : 23|2@0+ (1,0) [0|3] ""  BMS1
 SG_ HCU_1_Clear_Fault : 12|1@0+ (1,0) [0|1] ""  BMS1
 SG_ HCU_1_WeldedFaultCheck : 13|1@0+ (1,0) [0|1] ""  BMS1
 SG_ HCU_1_InsCheck : 15|1@0+ (1,0) [0|1] ""  BMS1
 SG_ HCU1_Checksum : 7|8@0+ (1,0) [0|255] ""  BMS1
 SG_ HCU1_RollingCounter : 11|4@0+ (1,0) [0|15] ""  BMS1
 SG_ HCU1_St_Ready : 14|1@0+ (1,0) [0|1] ""  BMS1
 SG_ HCU1_F_HVConnectRequest : 45|1@0+ (1,0) [0|1] ""  BMS1
 SG_ HCU1_St_HVConnectRequest : 47|1@0+ (1,0) [0|1] ""  BMS1

BO_ 1136 ICM_1: 8 Vector__XXX
 SG_ ICM1_Checksum : 7|8@0+ (1,0) [0|255] ""  BMS1
 SG_ ICM1_RollingCounter : 11|4@0+ (1,0) [0|15] ""  BMS1
 SG_ ICM1_N_Odograph : 27|20@0+ (1,0) [0|999999] "kilometer"  BMS1

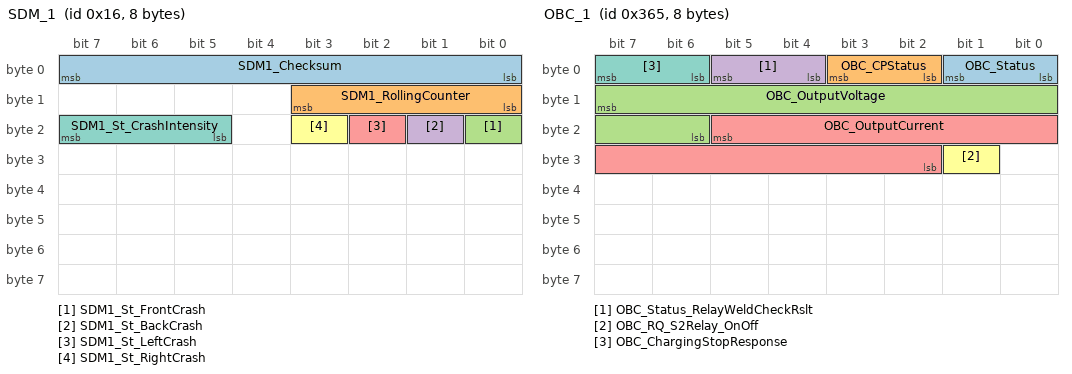
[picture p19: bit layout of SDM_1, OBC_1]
BO_ 22 SDM_1: 8 Vector__XXX
 SG_ SDM1_Checksum : 7|8@0+ (1,0) [0|255] ""  BMS1
 SG_ SDM1_RollingCounter : 11|4@0+ (1,0) [0|15] ""  BMS1
 SG_ SDM1_St_FrontCrash : 16|1@0+ (1,0) [0|1] ""  BMS1
 SG_ SDM1_St_BackCrash : 17|1@0+ (1,0) [0|1] ""  BMS1
 SG_ SDM1_St_LeftCrash : 18|1@0+ (1,0) [0|1] ""  BMS1
 SG_ SDM1_St_RightCrash : 19|1@0+ (1,0) [0|1] ""  BMS1
 SG_ SDM1_St_CrashIntensity : 23|3@0+ (1,0) [0|7] ""  BMS1

BO_ 1840 Diag_BMS_ReqPhsy: 8 Vector__XXX
 SG_ Diag_BMS_ReqPhsy_b0 : 7|8@0+ (1,0) [0|255] ""  BMS1
 SG_ Diag_BMS_ReqPhsy_b1 : 15|8@0+ (1,0) [0|255] ""  BMS1
 SG_ Diag_BMS_ReqPhsy_b2 : 23|8@0+ (1,0) [0|255] ""  BMS1
 SG_ Diag_BMS_ReqPhsy_b3 : 31|8@0+ (1,0) [0|255] ""  BMS1
 SG_ Diag_BMS_ReqPhsy_b4 : 39|8@0+ (1,0) [0|255] ""  BMS1
 SG_ Diag_BMS_ReqPhsy_b5 : 47|8@0+ (1,0) [0|255] ""  BMS1
 SG_ Diag_BMS_ReqPhsy_b6 : 55|8@0+ (1,0) [0|255] ""  BMS1
 SG_ Diag_BMS_ReqPhsy_b7 : 63|8@0+ (1,0) [0|255] ""  BMS1

BO_ 2015 Diag_HCAN_ReqFunc: 8 Vector__XXX
 SG_ Diag_HCAN_ReqFunc_b0 : 7|8@0+ (1,0) [0|255] ""  BMS1
 SG_ Diag_HCAN_ReqFunc_b1 : 15|8@0+ (1,0) [0|255] ""  BMS1
 SG_ Diag_HCAN_ReqFunc_b2 : 23|8@0+ (1,0) [0|255] ""  BMS1
 SG_ Diag_HCAN_ReqFunc_b3 : 31|8@0+ (1,0) [0|255] ""  BMS1
 SG_ Diag_HCAN_ReqFunc_b4 : 39|8@0+ (1,0) [0|255] ""  BMS1
 SG_ Diag_HCAN_ReqFunc_b5 : 47|8@0+ (1,0) [0|255] ""  BMS1
 SG_ Diag_HCAN_ReqFunc_b6 : 55|8@0+ (1,0) [0|255] ""  BMS1
 SG_ Diag_HCAN_ReqFunc_b7 : 63|8@0+ (1,0) [0|255] ""  BMS1

BO_ 869 OBC_1: 8 Vector__XXX
 SG_ OBC_Status : 1|2@0+ (1,0) [0|3] ""  BMS1
 SG_ OBC_CPStatus : 3|2@0+ (1,0) [0|3] ""  BMS1
 SG_ OBC_OutputVoltage : 15|10@0+ (1,0) [0|500] "V"  BMS1
 SG_ OBC_Status_RelayWeldCheckRslt : 5|2@0+ (1,0) [0|3] ""  BMS1
 SG_ OBC_OutputCurrent : 21|12@0+ (0.01,0) [0|40.94] "A"  BMS1
 SG_ OBC_RQ_S2Relay_OnOff : 25|1@0+ (1,0) [0|1] ""  BMS1
 SG_ OBC_ChargingStopResponse : 7|2@0+ (1,0) [0|3] ""  BMS1

CM_ " ";
CM_ BO_ 3221225472 "This is a message for not used signals, created by Vector CANdb++ DBC OLE DB Provider.";
CM_ SG_ 3221225472 BMS2_3_Checksum "Checksum";
CM_ SG_ 3221225472 BMS2_3_F_CellOverV "Cell OverVoltage fault state";
CM_ SG_ 3221225472 BMS2_3_F_CellUnderV "Cell UnderVoltage fault state";
CM_ SG_ 3221225472 BMS2_3_F_CellVoltagedropout "Cell Voltage Dropout fault state";
CM_ SG_ 3221225472 BMS2_3_F_BattOverV "Battery Voltage OverVoltage  fault state";
CM_ SG_ 3221225472 BMS2_3_F_BattUnderV "Battery Voltage UnderVoltage  fault state";
CM_ SG_ 3221225472 BMS2_3_RollingCounter "RollingCounter";
CM_ SG_ 3221225472 BMS2_9_F_BattSupplyingOverI "HV Battery Supplying Over Current";
CM_ SG_ 3221225472 BMS2_9_F_QCNegativeRelay "QC- Relay Diagnosis not used";
CM_ SG_ 3221225472 BMS2_9_F_MainPositiveRelayCoil "Main+ Relay Coil Diagnosis";
CM_ SG_ 3221225472 BMS2_9_F_MainNegativeRelayCoil "Main- Relay Coil Diagnosis";
CM_ SG_ 3221225472 BMS2_9_F_PrechargeRelayCoil "Precharge Relay Coil Diagnosis";
CM_ SG_ 3221225472 BMS2_9_F_QCPositiveRelayCoil "QC+ Relay Coil Diagnosis not used";
CM_ SG_ 3221225472 BMS2_9_F_MainPositiveRelay "Main+ Relay Diagnosis";
CM_ SG_ 3221225472 BMS2_9_F_QCNegativeRelayCoil "QC- Relay Coil Diagnosis not used";
CM_ SG_ 3221225472 BMS2_9_F_CellBalancingCircuit "Cell balancing Circuit Fault";
CM_ SG_ 3221225472 BMS2_9_F_BattOverChgErr "Battery OverCharge Fault";
CM_ SG_ 3221225472 BMS2_9_F_BattPluginChgOverI "HV Battery Plugin Charge Over Current";
CM_ SG_ 3221225472 BMS2_9_F_PrechargeRelayOpenStuck "Precharge Relay Open Stuck Fault";
CM_ SG_ 3221225472 BMS2_9_F_MSDFuse "MSD Fuse Fault";
CM_ SG_ 3221225472 BMS2_9_F_HVBattTempRisingOverspe "HV Battery Temperature Rising Overspeed ";
CM_ SG_ 3221225472 BMS2_9_F_BattRegenerativeOverI "HV Battery Regenerative Over Current";
CM_ SG_ 3221225472 BMS2_9_F_MainNegativeRelay "Main- Relay Diagnosis";
CM_ SG_ 3221225472 BMS2_9_F_PrechargeRelay "Precharge relay Diagnosis";
CM_ SG_ 3221225472 BMS2_9_F_QCPositiveRelay "QC+ Relay Diagnosis not used";
CM_ SG_ 3221225472 BMS3_F_CellOverV "Cell OverVoltage fault state";
CM_ SG_ 3221225472 BMS3_F_CellUnderV "Cell UnderVoltage fault state";
CM_ SG_ 3221225472 BMS3_F_CellVoltagedropout "Cell Voltage Dropout fault state";
CM_ SG_ 3221225472 BMS3_F_BattOverV "Battery Voltage OverVoltage  fault state";
CM_ SG_ 3221225472 BMS3_F_BattUnderV "Battery Voltage UnderVoltage  fault state";
CM_ SG_ 3221225472 HCU_2_RelayOn "Relay  close check comand ";
CM_ SG_ 3221225472 HCU_2_OBCRelayStatus "OBC Relay (+) Status  ";
CM_ SG_ 3221225472 HCU_2_ChargingStopRequest "Charging stop request to Charger";
CM_ SG_ 3221225472 HCU_2_ChargerAllow "Allow to charger";
CM_ SG_ 3221225472 HCU_2_CCStatus "CC Status for normal charge";
CM_ SG_ 3221225472 HCU2_2_OBCRelayStatus "OBC Relay (+) Status  ";
CM_ SG_ 3221225472 HCU2_2_ChargingStopRequest "Charging stop request to Charger";
CM_ SG_ 3221225472 HCU2_2_ChargerAllow "Allow to charger";
CM_ SG_ 3221225472 HCU2_2_CCStatus "CC Status for normal charge";
CM_ SG_ 416 HCU2_1_BmsSleep "Ctrl BMS go to sleep mode";
CM_ SG_ 416 HCU2_1_Checksum "Checksum";
CM_ SG_ 416 HCU2_1_RollingCounter "RollingCounter";
CM_ SG_ 416 HCU2_1_St_Ready "Ready Status";
CM_ SG_ 416 HCU2_1_F_HVConnectRequest "High Voltage Connect Request Valid";
CM_ SG_ 416 HCU2_1_St_HVConnectRequest "High Voltage Connect Request";
CM_ SG_ 1201 BMS2_3_N_CellVoltageMin "Cell Voltage Min";
CM_ SG_ 1201 BMS2_3_N_CellVoltageMax "Cell Voltage Max";
CM_ SG_ 1201 BMS2_3_N_PosInsR "DC Link Positive Insulation";
CM_ SG_ 1185 BMS3_N_CellVoltageMin "Cell Voltage Min";
CM_ SG_ 1185 BMS3_N_CellVoltageMax "Cell Voltage Max";
CM_ SG_ 1185 BMS3_N_NegInsR "DC Link Negative Insulation";
CM_ SG_ 1185 BMS3_N_PosInsR "DC Link Positive Insulation";
CM_ SG_ 1469 BMS2_CMATemp_N_No9 "No9 CMA Temp";
CM_ SG_ 1469 BMS2_CMATemp_N_No24 "No24 CMA Temp";
CM_ SG_ 1469 BMS2_CMATemp_N_No23 "No23 CMA Temp";
CM_ SG_ 1469 BMS2_CMATemp_N_No22 "No22 CMA Temp";
CM_ SG_ 1469 BMS2_CMATemp_N_No21 "No21 CMA Temp";
CM_ SG_ 1469 BMS2_CMATemp_N_No20 "No20 CMA Temp";
CM_ SG_ 1469 BMS2_CMATemp_N_No19 "No19 CMA Temp";
CM_ SG_ 1469 BMS2_CMATemp_N_No18 "No18 CMA Temp";
CM_ SG_ 1469 BMS2_CMATemp_N_No17 "No17 CMA Temp";
CM_ SG_ 1469 BMS2_CMATemp_N_No16 "No16 CMA Temp";
CM_ SG_ 1469 BMS2_CMATemp_N_No15 "No15 CMA Temp";
CM_ SG_ 1469 BMS2_CMATemp_N_No14 "No14 CMA Temp";
CM_ SG_ 1469 BMS2_CMATemp_N_No13 "No13 CMA Temp";
CM_ SG_ 1469 BMS2_CMATemp_N_No12 "No12 CMA Temp";
CM_ SG_ 1469 BMS2_CMATemp_N_No11 "No11 CMA Temp";
CM_ SG_ 1469 BMS2_CMATemp_N_No10 "No10 CMA Temp";
CM_ SG_ 1469 BMS2_CMATemp_N_No1 "No1 CMA Temp";
CM_ SG_ 1469 BMS2_CMATemp_N_No3 "No3 CMA Temp";
CM_ SG_ 1469 BMS2_CMATemp_N_No4 "No4 CMA Temp";
CM_ SG_ 1469 BMS2_CMATemp_N_No5 "No5 CMA Temp";
CM_ SG_ 1469 BMS2_CMATemp_N_No6 "No6 CMA Temp";
CM_ SG_ 1469 BMS2_CMATemp_N_No7 "No7 CMA Temp";
CM_ SG_ 1469 BMS2_CMATemp_N_No8 "No8 CMA Temp";
CM_ SG_ 1469 BMS2_CMATemp_N_No2 "No2 CMA Temp";
CM_ SG_ 1457 BMS2_CellVol1_N_No1 "No1 Cell Voltage";
CM_ SG_ 1457 BMS2_CellVol1_N_No3 "No3 Cell Voltage";
CM_ SG_ 1457 BMS2_CellVol1_N_No4 "No4 Cell Voltage";
CM_ SG_ 1457 BMS2_CellVol1_N_No5 "No5 Cell Voltage";
CM_ SG_ 1457 BMS2_CellVol1_N_No6 "No6 Cell Voltage";
CM_ SG_ 1457 BMS2_CellVol1_N_No7 "No7 Cell Voltage";
CM_ SG_ 1457 BMS2_CellVol1_N_No8 "No8 Cell Voltage";
CM_ SG_ 1457 BMS2_CellVol1_N_No2 "No2 Cell Voltage";
CM_ SG_ 1466 BMS2_CellVol10_N_No73 "No73 Cell Voltage";
CM_ SG_ 1466 BMS2_CellVol10_N_No75 "No75 Cell Voltage";
CM_ SG_ 1466 BMS2_CellVol10_N_No76 "No76 Cell Voltage";
CM_ SG_ 1466 BMS2_CellVol10_N_No77 "No77 Cell Voltage";
CM_ SG_ 1466 BMS2_CellVol10_N_No78 "No78 Cell Voltage";
CM_ SG_ 1466 BMS2_CellVol10_N_No79 "No79 Cell Voltage";
CM_ SG_ 1466 BMS2_CellVol10_N_No80 "No80 Cell Voltage";
CM_ SG_ 1466 BMS2_CellVol10_N_No74 "No74 Cell Voltage";
CM_ SG_ 1467 BMS2_CellVol11_N_No81 "No81 Cell Voltage";
CM_ SG_ 1467 BMS2_CellVol11_N_No83 "No83 Cell Voltage";
CM_ SG_ 1467 BMS2_CellVol11_N_No84 "No84 Cell Voltage";
CM_ SG_ 1467 BMS2_CellVol11_N_No85 "No85 Cell Voltage";
CM_ SG_ 1467 BMS2_CellVol11_N_No86 "No86 Cell Voltage";
CM_ SG_ 1467 BMS2_CellVol11_N_No87 "No87 Cell Voltage";
CM_ SG_ 1467 BMS2_CellVol11_N_No88 "No88 Cell Voltage";
CM_ SG_ 1467 BMS2_CellVol11_N_No82 "No82 Cell Voltage";
CM_ SG_ 1468 BMS2_CellVol12_N_No89 "No89 Cell Voltage";
CM_ SG_ 1468 BMS2_CellVol12_N_No91 "No91 Cell Voltage";
CM_ SG_ 1468 BMS2_CellVol12_N_No92 "No92 Cell Voltage";
CM_ SG_ 1468 BMS2_CellVol12_N_No93 "No93 Cell Voltage";
CM_ SG_ 1468 BMS2_CellVol12_N_No94 "No94 Cell Voltage";
CM_ SG_ 1468 BMS2_CellVol12_N_No95 "No95 Cell Voltage";
CM_ SG_ 1468 BMS2_CellVol12_N_No96 "No96 Cell Voltage";
CM_ SG_ 1468 BMS2_CellVol12_N_No90 "No90 Cell Voltage";
CM_ SG_ 1458 BMS2_CellVol2_N_No9 "No9 Cell Voltage";
CM_ SG_ 1458 BMS2_CellVol2_N_No11 "No11 Cell Voltage";
CM_ SG_ 1458 BMS2_CellVol2_N_No12 "No12 Cell Voltage";
CM_ SG_ 1458 BMS2_CellVol2_N_No13 "No13 Cell Voltage";
CM_ SG_ 1458 BMS2_CellVol2_N_No14 "No14 Cell Voltage";
CM_ SG_ 1458 BMS2_CellVol2_N_No15 "No15 Cell Voltage";
CM_ SG_ 1458 BMS2_CellVol2_N_No16 "No16 Cell Voltage";
CM_ SG_ 1458 BMS2_CellVol2_N_No10 "No10 Cell Voltage";
CM_ SG_ 1459 BMS2_CellVol3_N_No17 "No17 Cell Voltage";
CM_ SG_ 1459 BMS2_CellVol3_N_No19 "No19 Cell Voltage";
CM_ SG_ 1459 BMS2_CellVol3_N_No20 "No20 Cell Voltage";
CM_ SG_ 1459 BMS2_CellVol3_N_No21 "No21 Cell Voltage";
CM_ SG_ 1459 BMS2_CellVol3_N_No22 "No22 Cell Voltage";
CM_ SG_ 1459 BMS2_CellVol3_N_No23 "No23 Cell Voltage";
CM_ SG_ 1459 BMS2_CellVol3_N_No24 "No24 Cell Voltage";
CM_ SG_ 1459 BMS2_CellVol3_N_No18 "No18 Cell Voltage";
CM_ SG_ 1460 BMS2_CellVol4_N_No25 "No25 Cell Voltage";
CM_ SG_ 1460 BMS2_CellVol4_N_No27 "No27 Cell Voltage";
CM_ SG_ 1460 BMS2_CellVol4_N_No28 "No28 Cell Voltage";
CM_ SG_ 1460 BMS2_CellVol4_N_No29 "No29 Cell Voltage";
CM_ SG_ 1460 BMS2_CellVol4_N_No30 "No30 Cell Voltage";
CM_ SG_ 1460 BMS2_CellVol4_N_No31 "No31 Cell Voltage";
CM_ SG_ 1460 BMS2_CellVol4_N_No32 "No32 Cell Voltage";
CM_ SG_ 1460 BMS2_CellVol4_N_No26 "No26 Cell Voltage";
CM_ SG_ 1461 BMS2_CellVol5_N_No33 "No33 Cell Voltage";
CM_ SG_ 1461 BMS2_CellVol5_N_No35 "No35 Cell Voltage";
CM_ SG_ 1461 BMS2_CellVol5_N_No36 "No36 Cell Voltage";
CM_ SG_ 1461 BMS2_CellVol5_N_No37 "No37 Cell Voltage";
CM_ SG_ 1461 BMS2_CellVol5_N_No38 "No38 Cell Voltage";
CM_ SG_ 1461 BMS2_CellVol5_N_No39 "No39 Cell Voltage";
CM_ SG_ 1461 BMS2_CellVol5_N_No40 "No40 Cell Voltage";
CM_ SG_ 1461 BMS2_CellVol5_N_No34 "No34 Cell Voltage";
CM_ SG_ 1462 BMS2_CellVol6_N_No41 "No41 Cell Voltage";
CM_ SG_ 1462 BMS2_CellVol6_N_No43 "No43 Cell Voltage";
CM_ SG_ 1462 BMS2_CellVol6_N_No44 "No44 Cell Voltage";
CM_ SG_ 1462 BMS2_CellVol6_N_No45 "No45 Cell Voltage";
CM_ SG_ 1462 BMS2_CellVol6_N_No46 "No46 Cell Voltage";
CM_ SG_ 1462 BMS2_CellVol6_N_No47 "No47 Cell Voltage";
CM_ SG_ 1462 BMS2_CellVol6_N_No48 "No48 Cell Voltage";
CM_ SG_ 1462 BMS2_CellVol6_N_No42 "No42 Cell Voltage";
CM_ SG_ 1463 BMS2_CellVol7_N_No49 "No49 Cell Voltage";
CM_ SG_ 1463 BMS2_CellVol7_N_No51 "No51 Cell Voltage";
CM_ SG_ 1463 BMS2_CellVol7_N_No52 "No52 Cell Voltage";
CM_ SG_ 1463 BMS2_CellVol7_N_No53 "No53 Cell Voltage";
CM_ SG_ 1463 BMS2_CellVol7_N_No54 "No54 Cell Voltage";
CM_ SG_ 1463 BMS2_CellVol7_N_No55 "No55 Cell Voltage";
CM_ SG_ 1463 BMS2_CellVol7_N_No56 "No56 Cell Voltage";
CM_ SG_ 1463 BMS2_CellVol7_N_No50 "No50 Cell Voltage";
CM_ SG_ 1464 BMS2_CellVol8_N_No57 "No57 Cell Voltage";
CM_ SG_ 1464 BMS2_CellVol8_N_No59 "No59 Cell Voltage";
CM_ SG_ 1464 BMS2_CellVol8_N_No60 "No60 Cell Voltage";
CM_ SG_ 1464 BMS2_CellVol8_N_No61 "No61 Cell Voltage";
CM_ SG_ 1464 BMS2_CellVol8_N_No62 "No62 Cell Voltage";
CM_ SG_ 1464 BMS2_CellVol8_N_No63 "No63 Cell Voltage";
CM_ SG_ 1464 BMS2_CellVol8_N_No64 "No64 Cell Voltage";
CM_ SG_ 1464 BMS2_CellVol8_N_No58 "No58 Cell Voltage";
CM_ SG_ 1465 BMS2_CellVol9_N_No65 "No65 Cell Voltage";
CM_ SG_ 1465 BMS2_CellVol9_N_No67 "No67 Cell Voltage";
CM_ SG_ 1465 BMS2_CellVol9_N_No68 "No68 Cell Voltage";
CM_ SG_ 1465 BMS2_CellVol9_N_No69 "No69 Cell Voltage";
CM_ SG_ 1465 BMS2_CellVol9_N_No70 "No70 Cell Voltage";
CM_ SG_ 1465 BMS2_CellVol9_N_No71 "No71 Cell Voltage";
CM_ SG_ 1465 BMS2_CellVol9_N_No72 "No72 Cell Voltage";
CM_ SG_ 1465 BMS2_CellVol9_N_No66 "No66 Cell Voltage";
CM_ SG_ 688 BMS2_1_Checksum "Checksum";
CM_ SG_ 688 BMS2_1_F_BatteryFaultLevel "Battery Fault Level";
CM_ SG_ 688 BMS2_1_St_BatteryMode "Battery Mode";
CM_ SG_ 688 BMS2_1_St_HVIL "HVIL Status";
CM_ SG_ 688 BMS2_1_N_BatteryCurrent "Battery Current
Charge is Negative polarity
Discharge is Positive Polarity";
CM_ SG_ 688 BMS2_1_St_PrechargeMode "Precharge Mode";
CM_ SG_ 688 BMS2_1_N_BatteryVoltage "Battery Voltage";
CM_ SG_ 688 BMS2_1_N_DCLinkVoltage "DC Link Voltage(Bus Voltage)";
CM_ SG_ 688 BMS2_1_St_MainPositiveRelay "Main+ Relay Status";
CM_ SG_ 688 BMS2_1_St_MainNegativeRelay "Main- Relay Status";
CM_ SG_ 688 BMS2_1_St_PrechargeRelay "Precharge Relay Status";
CM_ SG_ 688 BMS2_1_St_QCPositiveRelay "QC + Relay Status
S7N0 not used";
CM_ SG_ 688 BMS2_1_St_QCNegativeRelay "QC - Relay Status
S7N0 not used";
CM_ SG_ 688 BMS2_1_RollingCounter "RollingCounter";
CM_ SG_ 1200 BMS2_2_Checksum "Checksum";
CM_ SG_ 1200 BMS2_2_F_Isolation "Isolation Status";
CM_ SG_ 1200 BMS2_2_N_CellSumVoltage "Cell Sum Voltage";
CM_ SG_ 1200 BMS2_2_N_SOE "SOE";
CM_ SG_ 1200 BMS2_2_N_SOH "SOH";
CM_ SG_ 1200 BMS2_2_N_RSOC "RSOC(Related SOC)";
CM_ SG_ 1200 BMS2_2_RollingCounter "RollingCounter";
CM_ SG_ 1202 BMS2_4_Checksum "Checksum";
CM_ SG_ 1202 BMS2_4_F_CMATempDiff "CMA Temp Difference  fault state";
CM_ SG_ 1202 BMS2_4_F_BattOverTemp "Battery Over Temperature Fault";
CM_ SG_ 1202 BMS2_4_N_CMATempAve "CMA Temp Ave";
CM_ SG_ 1202 BMS2_4_N_CMATempMax "CMA Temp Max";
CM_ SG_ 1202 BMS2_4_N_CMATempMin "CMA Temp Min";
CM_ SG_ 1202 BMS2_4_N_InletTemp "Inlet Temp.(water inlet)";
CM_ SG_ 1202 BMS2_4_F_BattLowTemp1 "Battery Low Temperature Fault��Prohibit DC Charge��";
CM_ SG_ 1202 BMS2_4_F_BattLowTemp2 "Battery Low Temperature Fault��Prohibit AC Charge��";
CM_ SG_ 1202 BMS2_4_F_BattLowTemp3 "Battery Low Temperature Fault��Prohibit Discharge��";
CM_ SG_ 1202 BMS2_4_N_BatPwrConsumption "Battery Power Consumption
(the product of Cell Sum Voltage & Battery Current) 
Charge is Negative polarity
Discharge is Positive Polarity";
CM_ SG_ 1202 BMS2_4_RollingCounter "RollingCounter";
CM_ SG_ 948 BMS2_6_Checksum "Checksum";
CM_ SG_ 948 BMS2_6_St_BatHeatingReq "Battery Heating Request";
CM_ SG_ 948 BMS2_6_W_HVBattDanger "The warning for the HV battery danger status";
CM_ SG_ 948 BMS2_6_RollingCounter "RollingCounter";
CM_ SG_ 1204 BMS2_7_Checksum "Checksum";
CM_ SG_ 1204 BMS2_7_N_SOF10D "SOF 10sec(Discharge)";
CM_ SG_ 1204 BMS2_7_N_SOFContinuousD "SOF Continuoous(Discharge)";
CM_ SG_ 1204 BMS2_7_N_SOF10C "SOF 10sec(Charge)";
CM_ SG_ 1204 BMS2_7_N_SOF30C "SOF 30sec(Charge)";
CM_ SG_ 1204 BMS2_7_RollingCounter "RollingCounter";
CM_ SG_ 1205 BMS2_8_Checksum "Checksum";
CM_ SG_ 1205 BMS2_8_N_SOF30D "SOF 30sec(Discharge)";
CM_ SG_ 1205 BMS2_8_N_SOF2D "SOF 2sec(Discharge)";
CM_ SG_ 1205 BMS2_8_N_SOF2C "SOF 2sec(Charge)";
CM_ SG_ 1205 BMS2_8_RollingCounter "RollingCounter";
CM_ SG_ 1206 BMS2_10_N_CellVoltageAve "Cell Voltage Ave";
CM_ SG_ 1206 BMS2_10_InsChkState "Insulation checking  status ";
CM_ SG_ 1206 BMS2_10_RelayChkState " Relay checking  status  ";
CM_ SG_ 1206 BMS2_10_ChargerWorkingEnable "Charger working enable";
CM_ SG_ 1206 BMS2_10_ChargeVoltageRequest "Charge voltage request  ";
CM_ SG_ 1206 BMS2_10_ChargeCurrentRequest "Charge current request    ";
CM_ SG_ 1206 BMS2_10_BatteryChargeStatus "BMS charge status ";
CM_ SG_ 1677 NMBMS2__SourceID "The source node id";
CM_ SG_ 1677 NMBMS2__WakeSource "The wakeup source";
CM_ SG_ 1677 NMBMS2__ActiveSource1 "The NM active sorce is KL15";
CM_ SG_ 1677 NMBMS2__ActiveSource2 "The NM active sorce is Diagnose";
CM_ SG_ 1677 NMBMS2__ActiveSource3 "The NM active sorce is Repeat message timer has not expired";
CM_ SG_ 1677 NMBMS2__ActiveSource4 "The NM active sorce is AC Charging";
CM_ SG_ 1677 NMBMS2__ActiveSource5 "The NM active sorce is DC Charging";
CM_ SG_ 1677 NMBMS2__RepeatReq "The repeat message request";
CM_ SG_ 883 BCM2_1_Checksum "Checksum";
CM_ SG_ 883 BCM2_1_RollingCounter "RollingCounter";
CM_ SG_ 883 BCM2_1_St_KL15 "KL_15 Status";
CM_ SG_ 883 BCM2_1_St_KLR "KL_R Status";
CM_ SG_ 883 BCM2_1_St_KL50 "KL_50 Status";
CM_ SG_ 320 BR2_1_Checksum "Checksum";
CM_ SG_ 320 BR2_1_RollingCounter "RollingCounter";
CM_ SG_ 320 BR2_1_F_VehicleSpeed "Vehicle speed value valid";
CM_ SG_ 320 BR2_1_N_VehicleSpeed "Vehicle speed value";
CM_ SG_ 1152 ICM2_1_Checksum "Checksum";
CM_ SG_ 1152 ICM2_1_RollingCounter "RollingCounter";
CM_ SG_ 1152 ICM2_1_N_Odograph "The odograph output";
CM_ SG_ 38 SDM2_1_Checksum "Checksum";
CM_ SG_ 38 SDM2_1_RollingCounter "RollingCounter";
CM_ SG_ 38 SDM2_1_St_FrontCrash "Front Crash";
CM_ SG_ 38 SDM2_1_St_BackCrash "Back Crash";
CM_ SG_ 38 SDM2_1_St_LeftCrash "Left Crash";
CM_ SG_ 38 SDM2_1_St_RightCrash "Right Crash";
CM_ SG_ 38 SDM2_1_St_CrashIntensity "Crash Intensity";
CM_ SG_ 885 OBC2__Status "Charger status";
CM_ SG_ 885 OBC2__CPStatus "CP status";
CM_ SG_ 885 OBC2__OutputVoltage "Charger output voltage";
CM_ SG_ 885 OBC2__Status_RelayWeldCheckRslt "Relay Weld Check Result Status";
CM_ SG_ 885 OBC2__OutputCurrent "Charger output current";
CM_ SG_ 885 OBC2__RQ_S2Relay_OnOff "S2 Switch of Vehicle 220V AC Charging Relay On/Off Request";
CM_ SG_ 885 OBC2__ChargingStopResponse "Response for VCM_Charging stop request";
CM_ SG_ 1453 BMSCMATemp_N_No24 "No24 CMA Temp";
CM_ SG_ 1453 BMSCMATemp_N_No23 "No23 CMA Temp";
CM_ SG_ 1453 BMSCMATemp_N_No22 "No22 CMA Temp";
CM_ SG_ 1453 BMSCMATemp_N_No21 "No21 CMA Temp";
CM_ SG_ 1453 BMSCMATemp_N_No20 "No20 CMA Temp";
CM_ SG_ 1453 BMSCMATemp_N_No19 "No19 CMA Temp";
CM_ SG_ 1453 BMSCMATemp_N_No18 "No18 CMA Temp";
CM_ SG_ 1453 BMSCMATemp_N_No17 "No17 CMA Temp";
CM_ SG_ 1453 BMSCMATemp_N_No16 "No16 CMA Temp";
CM_ SG_ 1453 BMSCMATemp_N_No15 "No15 CMA Temp";
CM_ SG_ 1453 BMSCMATemp_N_No14 "No14 CMA Temp";
CM_ SG_ 1453 BMSCMATemp_N_No13 "No13 CMA Temp";
CM_ SG_ 1453 BMSCMATemp_N_No9 "No9 CMA Temp";
CM_ SG_ 1453 BMSCMATemp_N_No12 "No12 CMA Temp";
CM_ SG_ 1453 BMSCMATemp_N_No11 "No11 CMA Temp";
CM_ SG_ 1453 BMSCMATemp_N_No10 "No10 CMA Temp";
CM_ SG_ 1453 BMSCMATemp_N_No1 "No1 CMA Temp";
CM_ SG_ 1453 BMSCMATemp_N_No3 "No3 CMA Temp";
CM_ SG_ 1453 BMSCMATemp_N_No4 "No4 CMA Temp";
CM_ SG_ 1453 BMSCMATemp_N_No5 "No5 CMA Temp";
CM_ SG_ 1453 BMSCMATemp_N_No6 "No6 CMA Temp";
CM_ SG_ 1453 BMSCMATemp_N_No7 "No7 CMA Temp";
CM_ SG_ 1453 BMSCMATemp_N_No8 "No8 CMA Temp";
CM_ SG_ 1453 BMSCMATemp_N_No2 "No2 CMA Temp";
CM_ SG_ 1441 BMSCellVol1_N_No1 "No1 Cell Voltage";
CM_ SG_ 1441 BMSCellVol1_N_No3 "No3 Cell Voltage";
CM_ SG_ 1441 BMSCellVol1_N_No4 "No4 Cell Voltage";
CM_ SG_ 1441 BMSCellVol1_N_No5 "No5 Cell Voltage";
CM_ SG_ 1441 BMSCellVol1_N_No6 "No6 Cell Voltage";
CM_ SG_ 1441 BMSCellVol1_N_No7 "No7 Cell Voltage";
CM_ SG_ 1441 BMSCellVol1_N_No8 "No8 Cell Voltage";
CM_ SG_ 1441 BMSCellVol1_N_No2 "No2 Cell Voltage";
CM_ SG_ 1450 BMSCellVol10_N_No73 "No73 Cell Voltage";
CM_ SG_ 1450 BMSCellVol10_N_No75 "No75 Cell Voltage";
CM_ SG_ 1450 BMSCellVol10_N_No76 "No76 Cell Voltage";
CM_ SG_ 1450 BMSCellVol10_N_No77 "No77 Cell Voltage";
CM_ SG_ 1450 BMSCellVol10_N_No78 "No78 Cell Voltage";
CM_ SG_ 1450 BMSCellVol10_N_No79 "No79 Cell Voltage";
CM_ SG_ 1450 BMSCellVol10_N_No80 "No80 Cell Voltage";
CM_ SG_ 1450 BMSCellVol10_N_No74 "No74 Cell Voltage";
CM_ SG_ 1451 BMSCellVol11_N_No81 "No81 Cell Voltage";
CM_ SG_ 1451 BMSCellVol11_N_No83 "No83 Cell Voltage";
CM_ SG_ 1451 BMSCellVol11_N_No84 "No84 Cell Voltage";
CM_ SG_ 1451 BMSCellVol11_N_No85 "No85 Cell Voltage";
CM_ SG_ 1451 BMSCellVol11_N_No86 "No86 Cell Voltage";
CM_ SG_ 1451 BMSCellVol11_N_No87 "No87 Cell Voltage";
CM_ SG_ 1451 BMSCellVol11_N_No88 "No88 Cell Voltage";
CM_ SG_ 1451 BMSCellVol11_N_No82 "No82 Cell Voltage";
CM_ SG_ 1452 BMSCellVol12_N_No89 "No89 Cell Voltage";
CM_ SG_ 1452 BMSCellVol12_N_No91 "No91 Cell Voltage";
CM_ SG_ 1452 BMSCellVol12_N_No92 "No92 Cell Voltage";
CM_ SG_ 1452 BMSCellVol12_N_No93 "No93 Cell Voltage";
CM_ SG_ 1452 BMSCellVol12_N_No94 "No94 Cell Voltage";
CM_ SG_ 1452 BMSCellVol12_N_No95 "No95 Cell Voltage";
CM_ SG_ 1452 BMSCellVol12_N_No96 "No96 Cell Voltage";
CM_ SG_ 1452 BMSCellVol12_N_No90 "No90 Cell Voltage";
CM_ SG_ 1442 BMSCellVol2_N_No9 "No9 Cell Voltage";
CM_ SG_ 1442 BMSCellVol2_N_No11 "No11 Cell Voltage";
CM_ SG_ 1442 BMSCellVol2_N_No12 "No12 Cell Voltage";
CM_ SG_ 1442 BMSCellVol2_N_No13 "No13 Cell Voltage";
CM_ SG_ 1442 BMSCellVol2_N_No14 "No14 Cell Voltage";
CM_ SG_ 1442 BMSCellVol2_N_No15 "No15 Cell Voltage";
CM_ SG_ 1442 BMSCellVol2_N_No16 "No16 Cell Voltage";
CM_ SG_ 1442 BMSCellVol2_N_No10 "No10 Cell Voltage";
CM_ SG_ 1443 BMSCellVol3_N_No17 "No17 Cell Voltage";
CM_ SG_ 1443 BMSCellVol3_N_No19 "No19 Cell Voltage";
CM_ SG_ 1443 BMSCellVol3_N_No20 "No20 Cell Voltage";
CM_ SG_ 1443 BMSCellVol3_N_No21 "No21 Cell Voltage";
CM_ SG_ 1443 BMSCellVol3_N_No22 "No22 Cell Voltage";
CM_ SG_ 1443 BMSCellVol3_N_No23 "No23 Cell Voltage";
CM_ SG_ 1443 BMSCellVol3_N_No24 "No24 Cell Voltage";
CM_ SG_ 1443 BMSCellVol3_N_No18 "No18 Cell Voltage";
CM_ SG_ 1444 BMSCellVol4_N_No25 "No25 Cell Voltage";
CM_ SG_ 1444 BMSCellVol4_N_No27 "No27 Cell Voltage";
CM_ SG_ 1444 BMSCellVol4_N_No28 "No28 Cell Voltage";
CM_ SG_ 1444 BMSCellVol4_N_No29 "No29 Cell Voltage";
CM_ SG_ 1444 BMSCellVol4_N_No30 "No30 Cell Voltage";
CM_ SG_ 1444 BMSCellVol4_N_No31 "No31 Cell Voltage";
CM_ SG_ 1444 BMSCellVol4_N_No32 "No32 Cell Voltage";
CM_ SG_ 1444 BMSCellVol4_N_No26 "No26 Cell Voltage";
CM_ SG_ 1445 BMSCellVol5_N_No33 "No33 Cell Voltage";
CM_ SG_ 1445 BMSCellVol5_N_No35 "No35 Cell Voltage";
CM_ SG_ 1445 BMSCellVol5_N_No36 "No36 Cell Voltage";
CM_ SG_ 1445 BMSCellVol5_N_No37 "No37 Cell Voltage";
CM_ SG_ 1445 BMSCellVol5_N_No38 "No38 Cell Voltage";
CM_ SG_ 1445 BMSCellVol5_N_No39 "No39 Cell Voltage";
CM_ SG_ 1445 BMSCellVol5_N_No40 "No40 Cell Voltage";
CM_ SG_ 1445 BMSCellVol5_N_No34 "No34 Cell Voltage";
CM_ SG_ 1446 BMSCellVol6_N_No41 "No41 Cell Voltage";
CM_ SG_ 1446 BMSCellVol6_N_No43 "No43 Cell Voltage";
CM_ SG_ 1446 BMSCellVol6_N_No44 "No44 Cell Voltage";
CM_ SG_ 1446 BMSCellVol6_N_No45 "No45 Cell Voltage";
CM_ SG_ 1446 BMSCellVol6_N_No46 "No46 Cell Voltage";
CM_ SG_ 1446 BMSCellVol6_N_No47 "No47 Cell Voltage";
CM_ SG_ 1446 BMSCellVol6_N_No48 "No48 Cell Voltage";
CM_ SG_ 1446 BMSCellVol6_N_No42 "No42 Cell Voltage";
CM_ SG_ 1447 BMSCellVol7_N_No49 "No49 Cell Voltage";
CM_ SG_ 1447 BMSCellVol7_N_No51 "No51 Cell Voltage";
CM_ SG_ 1447 BMSCellVol7_N_No52 "No52 Cell Voltage";
CM_ SG_ 1447 BMSCellVol7_N_No53 "No53 Cell Voltage";
CM_ SG_ 1447 BMSCellVol7_N_No54 "No54 Cell Voltage";
CM_ SG_ 1447 BMSCellVol7_N_No55 "No55 Cell Voltage";
CM_ SG_ 1447 BMSCellVol7_N_No56 "No56 Cell Voltage";
CM_ SG_ 1447 BMSCellVol7_N_No50 "No50 Cell Voltage";
CM_ SG_ 1448 BMSCellVol8_N_No57 "No57 Cell Voltage";
CM_ SG_ 1448 BMSCellVol8_N_No59 "No59 Cell Voltage";
CM_ SG_ 1448 BMSCellVol8_N_No60 "No60 Cell Voltage";
CM_ SG_ 1448 BMSCellVol8_N_No61 "No61 Cell Voltage";
CM_ SG_ 1448 BMSCellVol8_N_No62 "No62 Cell Voltage";
CM_ SG_ 1448 BMSCellVol8_N_No63 "No63 Cell Voltage";
CM_ SG_ 1448 BMSCellVol8_N_No64 "No64 Cell Voltage";
CM_ SG_ 1448 BMSCellVol8_N_No58 "No58 Cell Voltage";
CM_ SG_ 1449 BMSCellVol9_N_No65 "No65 Cell Voltage";
CM_ SG_ 1449 BMSCellVol9_N_No67 "No67 Cell Voltage";
CM_ SG_ 1449 BMSCellVol9_N_No68 "No68 Cell Voltage";
CM_ SG_ 1449 BMSCellVol9_N_No69 "No69 Cell Voltage";
CM_ SG_ 1449 BMSCellVol9_N_No70 "No70 Cell Voltage";
CM_ SG_ 1449 BMSCellVol9_N_No71 "No71 Cell Voltage";
CM_ SG_ 1449 BMSCellVol9_N_No72 "No72 Cell Voltage";
CM_ SG_ 1449 BMSCellVol9_N_No66 "No66 Cell Voltage";
CM_ SG_ 672 BMS1_Checksum "Checksum";
CM_ SG_ 672 BMS1_F_BatteryFaultLevel "Battery Fault Level";
CM_ SG_ 672 BMS1_St_BatteryMode "Battery Mode";
CM_ SG_ 672 BMS1_St_HVIL "HVIL Status";
CM_ SG_ 672 BMS1_N_BatteryCurrent "Battery Current
Charge is Negative polarity
Discharge is Positive Polarity";
CM_ SG_ 672 BMS1_St_PrechargeMode "Precharge Mode";
CM_ SG_ 672 BMS1_N_BatteryVoltage "Battery Voltage";
CM_ SG_ 672 BMS1_N_DCLinkVoltage "DC Link Voltage(Bus Voltage)";
CM_ SG_ 672 BMS1_St_MainPositiveRelay "Main+ Relay Status";
CM_ SG_ 672 BMS1_St_MainNegativeRelay "Main- Relay Status";
CM_ SG_ 672 BMS1_St_PrechargeRelay "Precharge Relay Status";
CM_ SG_ 672 BMS1_St_QCPositiveRelay "QC + Relay Status
S7N0 not used";
CM_ SG_ 672 BMS1_St_QCNegativeRelay "QC - Relay Status
S7N0 not used";
CM_ SG_ 672 BMS1_RollingCounter "RollingCounter";
CM_ SG_ 1184 BMS2_Checksum "Checksum";
CM_ SG_ 1184 BMS2_F_Isolation "Isolation Status";
CM_ SG_ 1184 BMS2_N_CellSumVoltage "Cell Sum Voltage";
CM_ SG_ 1184 BMS2_N_SOE "SOE";
CM_ SG_ 1184 BMS2_N_SOH "SOH";
CM_ SG_ 1184 BMS2_N_RSOC "RSOC(Related SOC)";
CM_ SG_ 1184 BMS2_RollingCounter "RollingCounter";
CM_ SG_ 1186 BMS4_Checksum "Checksum";
CM_ SG_ 1186 BMS4_F_CMATempDiff "CMA Temp Difference  fault state";
CM_ SG_ 1186 BMS4_F_BattOverTemp "Battery Over Temperature Fault";
CM_ SG_ 1186 BMS4_N_CMATempAve "CMA Temp Ave";
CM_ SG_ 1186 BMS4_N_CMATempMax "CMA Temp Max";
CM_ SG_ 1186 BMS4_N_CMATempMin "CMA Temp Min";
CM_ SG_ 1186 BMS4_N_InletTemp "Inlet Temp.(water inlet)";
CM_ SG_ 1186 BMS4_F_BattLowTemp1 "Battery Low Temperature Fault��Prohibit DC Charge��";
CM_ SG_ 1186 BMS4_F_BattLowTemp2 "Battery Low Temperature Fault��Prohibit AC Charge��";
CM_ SG_ 1186 BMS4_F_BattLowTemp3 "Battery Low Temperature Fault��Prohibit Discharge��";
CM_ SG_ 1186 BMS4_N_BatPwrConsumption "Battery Power Consumption
(the product of Cell Sum Voltage & Battery Current) 
Charge is Negative polarity
Discharge is Positive Polarity";
CM_ SG_ 1186 BMS4_RollingCounter "RollingCounter";
CM_ SG_ 932 BMS6_Checksum "Checksum";
CM_ SG_ 932 BMS6_St_BatHeatingReq "Battery Heating Request";
CM_ SG_ 932 BMS6_W_HVBattDanger "The warning for the HV battery danger status";
CM_ SG_ 932 BMS6_RollingCounter "RollingCounter";
CM_ SG_ 1188 BMS7_Checksum "Checksum";
CM_ SG_ 1188 BMS7_N_SOF10D "SOF 10sec(Discharge)";
CM_ SG_ 1188 BMS7_N_SOFContinuousD "SOF Continuoous(Discharge)";
CM_ SG_ 1188 BMS7_N_SOF10C "SOF 10sec(Charge)";
CM_ SG_ 1188 BMS7_N_SOF30C "SOF 30sec(Charge)";
CM_ SG_ 1188 BMS7_RollingCounter "RollingCounter";
CM_ SG_ 1189 BMS8_Checksum "Checksum";
CM_ SG_ 1189 BMS8_N_SOF30D "SOF 30sec(Discharge)";
CM_ SG_ 1189 BMS8_N_SOF2D "SOF 2sec(Discharge)";
CM_ SG_ 1189 BMS8_N_SOF2C "SOF 2sec(Charge)";
CM_ SG_ 1189 BMS8_RollingCounter "RollingCounter";
CM_ SG_ 1190 BMS10_N_CellVoltageAve "Cell Voltage Ave";
CM_ SG_ 1190 BMS10_InsChkState "Insulation checking  status ";
CM_ SG_ 1190 BMS10_RelayChkState " Relay checking  status  ";
CM_ SG_ 1190 BMS10_ChargerWorkingEnable "Charger working enable";
CM_ SG_ 1190 BMS10_ChargeVoltageRequest "Charge voltage request  ";
CM_ SG_ 1190 BMS10_ChargeCurrentRequest "Charge current request    ";
CM_ SG_ 1190 BMS10_BatteryChargeStatus "BMS charge status ";
CM_ SG_ 1661 NMBMS_SourceID "The source node id";
CM_ SG_ 1661 NMBMS_WakeSource "The wakeup source";
CM_ SG_ 1661 NMBMS_ActiveSource1 "The NM active sorce is KL15";
CM_ SG_ 1661 NMBMS_ActiveSource2 "The NM active sorce is Diagnose";
CM_ SG_ 1661 NMBMS_ActiveSource3 "The NM active sorce is Repeat message timer has not expired";
CM_ SG_ 1661 NMBMS_ActiveSource4 "The NM active sorce is AC Charging";
CM_ SG_ 1661 NMBMS_ActiveSource5 "The NM active sorce is DC Charging";
CM_ SG_ 1661 NMBMS_RepeatReq "The repeat message request";
CM_ SG_ 867 BCM1_Checksum "Checksum";
CM_ SG_ 867 BCM1_RollingCounter "RollingCounter";
CM_ SG_ 867 BCM1_St_KL15 "KL_15 Status";
CM_ SG_ 867 BCM1_St_KLR "KL_R Status";
CM_ SG_ 867 BCM1_St_KL50 "KL_50 Status";
CM_ SG_ 304 BR1_Checksum "Checksum";
CM_ SG_ 304 BR1_RollingCounter "RollingCounter";
CM_ SG_ 304 BR1_F_VehicleSpeed "Vehicle speed value valid";
CM_ SG_ 304 BR1_N_VehicleSpeed "Vehicle speed value";
CM_ SG_ 400 HCU_1_BmsSleep "Ctrl BMS go to sleep mode";
CM_ SG_ 400 HCU_1_WeldedFaultCheck "Relay  open check comand";
CM_ SG_ 400 HCU_1_InsCheck "BMS  insulation check  command ";
CM_ SG_ 400 HCU1_Checksum "Checksum";
CM_ SG_ 400 HCU1_RollingCounter "RollingCounter";
CM_ SG_ 400 HCU1_St_Ready "Ready Status";
CM_ SG_ 400 HCU1_F_HVConnectRequest "High Voltage Connect Request Valid";
CM_ SG_ 400 HCU1_St_HVConnectRequest "High Voltage Connect Request";
CM_ SG_ 1136 ICM1_Checksum "Checksum";
CM_ SG_ 1136 ICM1_RollingCounter "RollingCounter";
CM_ SG_ 1136 ICM1_N_Odograph "The odograph output";
CM_ SG_ 22 SDM1_Checksum "Checksum";
CM_ SG_ 22 SDM1_RollingCounter "RollingCounter";
CM_ SG_ 22 SDM1_St_FrontCrash "Front Crash";
CM_ SG_ 22 SDM1_St_BackCrash "Back Crash";
CM_ SG_ 22 SDM1_St_LeftCrash "Left Crash";
CM_ SG_ 22 SDM1_St_RightCrash "Right Crash";
CM_ SG_ 22 SDM1_St_CrashIntensity "Crash Intensity";
CM_ SG_ 869 OBC_Status "Charger status";
CM_ SG_ 869 OBC_CPStatus "CP status";
CM_ SG_ 869 OBC_OutputVoltage "Charger output voltage";
CM_ SG_ 869 OBC_Status_RelayWeldCheckRslt "Relay Weld Check Result Status";
CM_ SG_ 869 OBC_OutputCurrent "Charger output current";
CM_ SG_ 869 OBC_RQ_S2Relay_OnOff "S2 Switch of Vehicle 220V AC Charging Relay On/Off Request";
CM_ SG_ 869 OBC_ChargingStopResponse "Response for VCM_Charging stop request";
BA_DEF_ BO_  "NmMessage" ENUM  "No","Yes";
BA_DEF_ BO_  "DiagState" ENUM  "No","Yes";
BA_DEF_ BO_  "DiagRequest" ENUM  "No","Yes";
BA_DEF_ BO_  "DiagResponse" ENUM  "No","Yes";
BA_DEF_ BO_  "GenMsgSendType" ENUM  "Cyclic","Event","Mixed";
BA_DEF_ BO_  "GenMsgCycleTime" INT 0 300000;
BA_DEF_ SG_  "GenSigStartValue" INT 0 300000;
BA_DEF_ BO_  "GenMsgCycleTimeFast" INT 0 300000;
BA_DEF_ BO_  "GenMsgNrOfRepetition" INT 0 300000;
BA_DEF_  "DBName" STRING ;
BA_DEF_ SG_  "GenSigValidAfterKL15" ENUM  "Y","N","Null";
BA_DEF_ SG_  "GenSigNote" STRING ;
BA_DEF_  "NmAsrWaitBusSleepTime" INT 0 65535;
BA_DEF_  "NmAsrRepeatMessageTime" INT 0 65535;
BA_DEF_  "NmAsrMessageCount" INT 1 256;
BA_DEF_  "NmAsrBaseAddress" HEX 0 2047;
BA_DEF_ BU_  "NmAsrCanMsgReducedTime" INT 0 65535;
BA_DEF_  "NmAsrCanMsgCycleTime" INT 1 65535;
BA_DEF_  "NmAsrTimeoutTime" INT 1 65535;
BA_DEF_ BU_  "NodeLayerModules" STRING ;
BA_DEF_ BU_  "ILUsed" ENUM  "No","Yes";
BA_DEF_  "Manufacturer" STRING ;
BA_DEF_  "NmType" STRING ;
BA_DEF_ BO_  "GenMsgILSupport" ENUM  "No","Yes";
BA_DEF_  "BusType" STRING ;
BA_DEF_ SG_  "SystemSignalLongSymbol" STRING ;
BA_DEF_DEF_  "NmMessage" "No";
BA_DEF_DEF_  "DiagState" "No";
BA_DEF_DEF_  "DiagRequest" "No";
BA_DEF_DEF_  "DiagResponse" "No";
BA_DEF_DEF_  "GenMsgSendType" "Cyclic";
BA_DEF_DEF_  "GenMsgCycleTime" 0;
BA_DEF_DEF_  "GenSigStartValue" 0;
BA_DEF_DEF_  "GenMsgCycleTimeFast" 0;
BA_DEF_DEF_  "GenMsgNrOfRepetition" 0;
BA_DEF_DEF_  "DBName" "";
BA_DEF_DEF_  "GenSigValidAfterKL15" "Null";
BA_DEF_DEF_  "GenSigNote" "";
BA_DEF_DEF_  "NmAsrWaitBusSleepTime" 1500;
BA_DEF_DEF_  "NmAsrRepeatMessageTime" 500;
BA_DEF_DEF_  "NmAsrMessageCount" 128;
BA_DEF_DEF_  "NmAsrBaseAddress" 1536;
BA_DEF_DEF_  "NmAsrCanMsgReducedTime" 100;
BA_DEF_DEF_  "NmAsrCanMsgCycleTime" 200;
BA_DEF_DEF_  "NmAsrTimeoutTime" 5000;
BA_DEF_DEF_  "NodeLayerModules" "CANoeILNLVector.dll";
BA_DEF_DEF_  "ILUsed" "Yes";
BA_DEF_DEF_  "Manufacturer" "Borgward";
BA_DEF_DEF_  "NmType" "NmAsr";
BA_DEF_DEF_  "GenMsgILSupport" "Yes";
BA_DEF_DEF_  "BusType" "CAN";
BA_DEF_DEF_  "SystemSignalLongSymbol" "";
BA_ "DBName" "HCAN";
BA_ "GenMsgCycleTime" BO_ 1192 1000;
BA_ "GenMsgCycleTime" BO_ 1208 1000;
BA_ "GenMsgCycleTime" BO_ 1191 10;
BA_ "GenMsgCycleTime" BO_ 1533 1000;
BA_ "GenMsgCycleTime" BO_ 1531 1000;
BA_ "GenMsgCycleTime" BO_ 1483 500;
BA_ "GenMsgCycleTime" BO_ 1440 500;
BA_ "GenMsgCycleTime" BO_ 1532 1000;
BA_ "GenMsgCycleTime" BO_ 1530 1000;
BA_ "GenMsgCycleTime" BO_ 1469 1000;
BA_ "GenMsgCycleTime" BO_ 1457 1000;
BA_ "GenMsgCycleTime" BO_ 1466 1000;
BA_ "GenMsgCycleTime" BO_ 1467 1000;
BA_ "GenMsgCycleTime" BO_ 1468 1000;
BA_ "GenMsgCycleTime" BO_ 1458 1000;
BA_ "GenMsgCycleTime" BO_ 1459 1000;
BA_ "GenMsgCycleTime" BO_ 1460 1000;
BA_ "GenMsgCycleTime" BO_ 1461 1000;
BA_ "GenMsgCycleTime" BO_ 1462 1000;
BA_ "GenMsgCycleTime" BO_ 1463 1000;
BA_ "GenMsgCycleTime" BO_ 1464 1000;
BA_ "GenMsgCycleTime" BO_ 1465 1000;
BA_ "GenMsgCycleTime" BO_ 688 10;
BA_ "GenMsgCycleTime" BO_ 1200 100;
BA_ "GenMsgCycleTime" BO_ 1202 200;
BA_ "GenMsgCycleTime" BO_ 948 200;
BA_ "GenMsgCycleTime" BO_ 1204 100;
BA_ "GenMsgCycleTime" BO_ 1205 100;
BA_ "GenMsgCycleTime" BO_ 1206 100;
BA_ "GenMsgCycleTime" BO_ 1696 500;
BA_ "GenMsgCycleTimeFast" BO_ 1677 100;
BA_ "GenMsgCycleTime" BO_ 1677 200;
BA_ "GenMsgSendType" BO_ 1677 2;
BA_ "NmMessage" BO_ 1677 1;
BA_ "GenMsgCycleTime" BO_ 883 100;
BA_ "GenMsgCycleTime" BO_ 320 10;
BA_ "GenMsgCycleTime" BO_ 1152 500;
BA_ "GenMsgNrOfRepetition" BO_ 38 250;
BA_ "GenMsgCycleTimeFast" BO_ 38 20;
BA_ "GenMsgCycleTime" BO_ 38 100;
BA_ "GenMsgSendType" BO_ 38 2;
BA_ "GenMsgCycleTime" BO_ 885 100;
BA_ "GenMsgCycleTime" BO_ 1453 1000;
BA_ "GenMsgCycleTime" BO_ 1441 1000;
BA_ "GenMsgCycleTime" BO_ 1450 1000;
BA_ "GenMsgCycleTime" BO_ 1451 1000;
BA_ "GenMsgCycleTime" BO_ 1452 1000;
BA_ "GenMsgCycleTime" BO_ 1442 1000;
BA_ "GenMsgCycleTime" BO_ 1443 1000;
BA_ "GenMsgCycleTime" BO_ 1444 1000;
BA_ "GenMsgCycleTime" BO_ 1445 1000;
BA_ "GenMsgCycleTime" BO_ 1446 1000;
BA_ "GenMsgCycleTime" BO_ 1447 1000;
BA_ "GenMsgCycleTime" BO_ 1448 1000;
BA_ "GenMsgCycleTime" BO_ 1449 1000;
BA_ "GenMsgCycleTime" BO_ 672 10;
BA_ "GenMsgCycleTime" BO_ 1184 100;
BA_ "GenMsgCycleTime" BO_ 1186 200;
BA_ "GenMsgCycleTime" BO_ 932 200;
BA_ "GenMsgCycleTime" BO_ 1188 100;
BA_ "GenMsgCycleTime" BO_ 1189 100;
BA_ "GenMsgCycleTime" BO_ 1190 100;
BA_ "GenMsgCycleTime" BO_ 1680 500;
BA_ "GenMsgCycleTimeFast" BO_ 1661 100;
BA_ "GenMsgCycleTime" BO_ 1661 200;
BA_ "GenMsgSendType" BO_ 1661 2;
BA_ "NmMessage" BO_ 1661 1;
BA_ "GenMsgSendType" BO_ 1848 1;
BA_ "DiagResponse" BO_ 1848 1;
BA_ "GenMsgCycleTime" BO_ 867 100;
BA_ "GenMsgCycleTime" BO_ 304 10;
BA_ "GenMsgCycleTime" BO_ 400 10;
BA_ "GenMsgCycleTime" BO_ 1136 500;
BA_ "GenMsgNrOfRepetition" BO_ 22 250;
BA_ "GenMsgCycleTimeFast" BO_ 22 20;
BA_ "GenMsgCycleTime" BO_ 22 100;
BA_ "GenMsgSendType" BO_ 22 2;
BA_ "GenMsgSendType" BO_ 1840 1;
BA_ "DiagRequest" BO_ 1840 1;
BA_ "GenMsgSendType" BO_ 2015 1;
BA_ "DiagState" BO_ 2015 1;
BA_ "GenMsgCycleTime" BO_ 869 100;
BA_ "GenSigNote" SG_ 3221225472 BMS2_3_F_CellOverV "�����ع�ѹ����";
BA_ "GenSigNote" SG_ 3221225472 BMS2_3_F_CellUnderV "������Ƿѹ����";
BA_ "GenSigNote" SG_ 3221225472 BMS2_3_F_CellVoltagedropout "��������һ���Բ��������ѹ�����";
BA_ "GenSigNote" SG_ 3221225472 BMS2_3_F_BattOverV "������ع�ѹ���������޵����ѹ*�ܵ�������";
BA_ "GenSigNote" SG_ 3221225472 BMS2_3_F_BattUnderV "�������Ƿѹ����";
BA_ "GenSigNote" SG_ 3221225472 BMS2_9_F_BattSupplyingOverI "������طŵ��������";
BA_ "GenSigNote" SG_ 3221225472 BMS2_9_F_QCNegativeRelay "ֱ����縺�̵����������";
BA_ "GenSigNote" SG_ 3221225472 BMS2_9_F_MainPositiveRelayCoil "�����̵�����Ȧ����";
BA_ "GenSigNote" SG_ 3221225472 BMS2_9_F_MainNegativeRelayCoil "�����̵�����Ȧ����";
BA_ "GenSigNote" SG_ 3221225472 BMS2_9_F_PrechargeRelayCoil "Ԥ��̵�����Ȧ����";
BA_ "GenSigNote" SG_ 3221225472 BMS2_9_F_QCPositiveRelayCoil "ֱ��������̵�����Ȧ����";
BA_ "GenSigNote" SG_ 3221225472 BMS2_9_F_MainPositiveRelay "�����̵����������";
BA_ "GenSigNote" SG_ 3221225472 BMS2_9_F_QCNegativeRelayCoil "ֱ����縺�̵�����Ȧ����";
BA_ "GenSigNote" SG_ 3221225472 BMS2_9_F_CellBalancingCircuit "�����·����";
BA_ "GenSigNote" SG_ 3221225472 BMS2_9_F_BattOverChgErr "������ع������";
BA_ "GenSigNote" SG_ 3221225472 BMS2_9_F_BattPluginChgOverI "���������ӳ���������";
BA_ "GenSigNote" SG_ 3221225472 BMS2_9_F_PrechargeRelayOpenStuck "Ԥ����迪·����";
BA_ "GenSigNote" SG_ 3221225472 BMS2_9_F_MSDFuse "MSD�۶�������";
BA_ "GenSigNote" SG_ 3221225472 BMS2_9_F_HVBattTempRisingOverspe "�����������";
BA_ "SystemSignalLongSymbol" SG_ 3221225472 BMS2_9_F_HVBattTempRisingOverspe "BMS2_9_F_HVBattTempRisingOverspeed";
BA_ "GenSigNote" SG_ 3221225472 BMS2_9_F_BattRegenerativeOverI "������ػس����������";
BA_ "GenSigNote" SG_ 3221225472 BMS2_9_F_MainNegativeRelay "�����̵����������";
BA_ "GenSigNote" SG_ 3221225472 BMS2_9_F_PrechargeRelay "Ԥ��̵����������";
BA_ "GenSigNote" SG_ 3221225472 BMS2_9_F_QCPositiveRelay "ֱ��������̵����������";
BA_ "GenSigNote" SG_ 3221225472 BMS3_F_CellOverV "�����ع�ѹ����";
BA_ "GenSigNote" SG_ 3221225472 BMS3_F_CellUnderV "������Ƿѹ����";
BA_ "GenSigNote" SG_ 3221225472 BMS3_F_CellVoltagedropout "��������һ���Բ��������ѹ�����";
BA_ "GenSigNote" SG_ 3221225472 BMS3_F_BattOverV "������ع�ѹ���������޵����ѹ*�ܵ�������";
BA_ "GenSigNote" SG_ 3221225472 BMS3_F_BattUnderV "�������Ƿѹ����";
BA_ "GenSigNote" SG_ 3221225472 HCU_2_RelayOn "�Ӵ����պϼ��";
BA_ "GenSigNote" SG_ 3221225472 HCU_2_OBCRelayStatus "OBC�̵���״̬";
BA_ "GenSigNote" SG_ 3221225472 HCU_2_ChargingStopRequest "VCM���ֹͣ����";
BA_ "GenSigNote" SG_ 3221225472 HCU_2_ChargerAllow "VCM����������";
BA_ "GenSigNote" SG_ 3221225472 HCU_2_CCStatus "CC��������״̬";
BA_ "GenSigNote" SG_ 3221225472 HCU2_2_OBCRelayStatus "OBC�̵���״̬";
BA_ "GenSigNote" SG_ 3221225472 HCU2_2_ChargingStopRequest "VCM���ֹͣ����";
BA_ "GenSigNote" SG_ 3221225472 HCU2_2_ChargerAllow "VCM����������";
BA_ "GenSigNote" SG_ 3221225472 HCU2_2_CCStatus "CC��������״̬";
BA_ "GenSigNote" SG_ 416 HCU2_1_BmsSleep "HCU����BMS����";
BA_ "GenSigNote" SG_ 416 HCU2_1_Checksum "Checksum";
BA_ "GenSigNote" SG_ 416 HCU2_1_RollingCounter "RollingCounter";
BA_ "GenSigNote" SG_ 416 HCU2_1_St_Ready "����ϵͳ׼������״̬";
BA_ "GenSigNote" SG_ 416 HCU2_1_F_HVConnectRequest "��ѹ����������Ч";
BA_ "GenSigStartValue" SG_ 416 HCU2_1_F_HVConnectRequest 1;
BA_ "GenSigNote" SG_ 416 HCU2_1_St_HVConnectRequest "��ѹ��������";
BA_ "GenSigNote" SG_ 1201 BMS2_3_N_CellVoltageMin "��С�����ѹ";
BA_ "GenSigNote" SG_ 1201 BMS2_3_N_CellVoltageMax "������ѹ";
BA_ "GenSigNote" SG_ 1201 BMS2_3_N_PosInsR "ĸ�������Գ����Ե����ֵ";
BA_ "GenSigNote" SG_ 1185 BMS3_N_CellVoltageMin "��С�����ѹ";
BA_ "GenSigNote" SG_ 1185 BMS3_N_CellVoltageMax "������ѹ";
BA_ "GenSigNote" SG_ 1185 BMS3_N_NegInsR "ĸ�߸����Գ����Ե����ֵ";
BA_ "GenSigNote" SG_ 1185 BMS3_N_PosInsR "ĸ�������Գ����Ե����ֵ";
BA_ "GenSigStartValue" SG_ 1714 Coolant_Temp_Inlet 30.4;
BA_ "GenSigStartValue" SG_ 1714 Coolant_Temp_Outlet_Right 30.4;
BA_ "GenSigStartValue" SG_ 1713 Coolant_Temp_Outlet_Left 30.4;
BA_ "GenSigNote" SG_ 1457 BMS2_CellVol1_N_No1 "�����ѹ";
BA_ "GenSigNote" SG_ 688 BMS2_1_Checksum "У���";
BA_ "GenSigNote" SG_ 688 BMS2_1_F_BatteryFaultLevel "��ع���״̬";
BA_ "GenSigNote" SG_ 688 BMS2_1_St_BatteryMode "���ģʽ";
BA_ "GenSigNote" SG_ 688 BMS2_1_St_HVIL "������ذ���ѹ����״̬";
BA_ "GenSigNote" SG_ 688 BMS2_1_N_BatteryCurrent "��ص���";
BA_ "GenSigStartValue" SG_ 688 BMS2_1_N_BatteryCurrent 800;
BA_ "GenSigNote" SG_ 688 BMS2_1_N_BatteryVoltage "��ص�ѹ���Ӵ���֮ǰ��";
BA_ "GenSigNote" SG_ 688 BMS2_1_N_DCLinkVoltage "ĸ�ߵ�ѹ���Ӵ���֮��";
BA_ "GenSigNote" SG_ 688 BMS2_1_St_MainPositiveRelay "�����̵���״̬";
BA_ "GenSigNote" SG_ 688 BMS2_1_St_MainNegativeRelay "�����̵���״̬";
BA_ "GenSigNote" SG_ 688 BMS2_1_St_PrechargeRelay "Ԥ��̵���״̬";
BA_ "GenSigNote" SG_ 688 BMS2_1_St_QCPositiveRelay "������̵���״̬";
BA_ "GenSigNote" SG_ 688 BMS2_1_St_QCNegativeRelay "��为�̵���״̬";
BA_ "GenSigNote" SG_ 688 BMS2_1_RollingCounter "������";
BA_ "GenSigNote" SG_ 1200 BMS2_2_Checksum "Checksum";
BA_ "GenSigNote" SG_ 1200 BMS2_2_F_Isolation "��Ե����״̬";
BA_ "GenSigNote" SG_ 1200 BMS2_2_N_CellSumVoltage "�����ܺ͵�ѹ";
BA_ "GenSigNote" SG_ 1200 BMS2_2_N_SOE "��ص���SOE";
BA_ "GenSigNote" SG_ 1200 BMS2_2_N_SOH "��ؽ�����SOH";
BA_ "GenSigNote" SG_ 1200 BMS2_2_N_RSOC "��ع���SOC";
BA_ "GenSigNote" SG_ 1200 BMS2_2_RollingCounter "RollingCounter";
BA_ "GenSigNote" SG_ 1202 BMS2_4_F_CMATempDiff "�¶Ȳ��챨��";
BA_ "GenSigNote" SG_ 1202 BMS2_4_F_BattOverTemp "��ظ��±���";
BA_ "GenSigNote" SG_ 1202 BMS2_4_N_CMATempAve "ģ��ƽ���¶�";
BA_ "GenSigStartValue" SG_ 1202 BMS2_4_N_CMATempAve 40;
BA_ "GenSigNote" SG_ 1202 BMS2_4_N_CMATempMax "ģ������¶�";
BA_ "GenSigStartValue" SG_ 1202 BMS2_4_N_CMATempMax 40;
BA_ "GenSigNote" SG_ 1202 BMS2_4_N_CMATempMin "ģ����С�¶�";
BA_ "GenSigStartValue" SG_ 1202 BMS2_4_N_CMATempMin 40;
BA_ "GenSigNote" SG_ 1202 BMS2_4_N_InletTemp "��ȴҺ��ˮ���¶�";
BA_ "GenSigStartValue" SG_ 1202 BMS2_4_N_InletTemp 40;
BA_ "GenSigNote" SG_ 1202 BMS2_4_F_BattLowTemp1 "��ص��±���(��ֹDC���)";
BA_ "GenSigNote" SG_ 1202 BMS2_4_F_BattLowTemp2 "��ص��±�������ֹAC��磩";
BA_ "GenSigNote" SG_ 1202 BMS2_4_F_BattLowTemp3 "��ص��±�������ֹ�ŵ磩";
BA_ "GenSigNote" SG_ 1202 BMS2_4_N_BatPwrConsumption "��ع��ʣ������ܵ�ѹ���ص����ĳ˻���";
BA_ "GenSigStartValue" SG_ 1202 BMS2_4_N_BatPwrConsumption 3600;
BA_ "GenSigNote" SG_ 948 BMS2_6_Checksum "У���";
BA_ "GenSigNote" SG_ 948 BMS2_6_St_BatHeatingReq "��ؼ�������";
BA_ "GenSigNote" SG_ 948 BMS2_6_W_HVBattDanger "���Σ�ձ���";
BA_ "GenSigNote" SG_ 948 BMS2_6_RollingCounter "������";
BA_ "GenSigNote" SG_ 1204 BMS2_7_N_SOF10D "���10s���ŵ繦�ʣ���ֵ�ŵ�SOF��";
BA_ "GenSigNote" SG_ 1204 BMS2_7_N_SOFContinuousD "��س������ŵ繦�ʣ������ŵ�SOF��";
BA_ "GenSigNote" SG_ 1204 BMS2_7_N_SOF10C "���10s����繦�ʣ���ֵ����SOF��";
BA_ "GenSigNote" SG_ 1204 BMS2_7_N_SOF30C "���30s����繦�ʣ���������SOF��";
BA_ "GenSigNote" SG_ 1205 BMS2_8_N_SOF30D "���30s���ŵ繦��";
BA_ "GenSigNote" SG_ 1205 BMS2_8_N_SOF2D "���2s���ŵ繦��";
BA_ "GenSigNote" SG_ 1205 BMS2_8_N_SOF2C "���2s����繦��";
BA_ "GenSigNote" SG_ 1206 BMS2_10_N_CellVoltageAve "ƽ�������ѹ";
BA_ "GenSigNote" SG_ 1206 BMS2_10_InsChkState "��Ե���״̬";
BA_ "GenSigNote" SG_ 1206 BMS2_10_RelayChkState "�Ӵ���ճ�����״̬";
BA_ "GenSigNote" SG_ 1206 BMS2_10_ChargerWorkingEnable "�������ʹ��״̬";
BA_ "GenSigNote" SG_ 1206 BMS2_10_ChargeVoltageRequest "��������ѹ";
BA_ "GenSigNote" SG_ 1206 BMS2_10_ChargeCurrentRequest "����������";
BA_ "GenSigNote" SG_ 1206 BMS2_10_BatteryChargeStatus "���״̬";
BA_ "GenSigNote" SG_ 1696 DevBMS2_1_N_ColdFanPWM "���PWMֵ(�����ӳ��������ȴ״̬��)";
BA_ "GenSigStartValue" SG_ 1677 NMBMS2__SourceID 125;
BA_ "GenSigNote" SG_ 883 BCM2_1_Checksum "checksum";
BA_ "GenSigNote" SG_ 883 BCM2_1_RollingCounter "rollingcounter";
BA_ "GenSigNote" SG_ 883 BCM2_1_St_KL15 "KL_15״̬��On��";
BA_ "GenSigNote" SG_ 883 BCM2_1_St_KLR "KL_R״̬��Acc��";
BA_ "GenSigNote" SG_ 883 BCM2_1_St_KL50 "KL_50״̬��Start��";
BA_ "GenSigNote" SG_ 320 BR2_1_Checksum "Checksum";
BA_ "GenSigNote" SG_ 320 BR2_1_RollingCounter "Rollingcounter";
BA_ "GenSigNote" SG_ 320 BR2_1_F_VehicleSpeed "����ֵ�Ƿ�Ϊ��Чֵ";
BA_ "GenSigStartValue" SG_ 320 BR2_1_F_VehicleSpeed 1;
BA_ "GenSigNote" SG_ 320 BR2_1_N_VehicleSpeed "����";
BA_ "GenSigNote" SG_ 1152 ICM2_1_Checksum "checksum";
BA_ "GenSigNote" SG_ 1152 ICM2_1_RollingCounter "Rollingcounter";
BA_ "GenSigNote" SG_ 1152 ICM2_1_N_Odograph "���";
BA_ "GenSigNote" SG_ 38 SDM2_1_Checksum "checksum";
BA_ "GenSigNote" SG_ 38 SDM2_1_RollingCounter "rollingcounter";
BA_ "GenSigNote" SG_ 38 SDM2_1_St_FrontCrash "ǰײ";
BA_ "GenSigNote" SG_ 38 SDM2_1_St_BackCrash "��ײ";
BA_ "GenSigNote" SG_ 38 SDM2_1_St_LeftCrash "��ײ";
BA_ "GenSigNote" SG_ 38 SDM2_1_St_RightCrash "��ײ";
BA_ "GenSigNote" SG_ 38 SDM2_1_St_CrashIntensity "��ײ�̶�";
BA_ "GenSigNote" SG_ 885 OBC2__Status "OBC����״̬";
BA_ "GenSigNote" SG_ 885 OBC2__CPStatus "CP״̬";
BA_ "GenSigNote" SG_ 885 OBC2__OutputVoltage "OBC�����ѹ";
BA_ "GenSigNote" SG_ 885 OBC2__Status_RelayWeldCheckRslt "�̵���ճ�������״̬";
BA_ "GenSigNote" SG_ 885 OBC2__OutputCurrent "OBC�������";
BA_ "GenSigNote" SG_ 885 OBC2__RQ_S2Relay_OnOff "����220V�������S2���ؼ̵�������/�Ͽ�����";
BA_ "GenSigNote" SG_ 885 OBC2__ChargingStopResponse "OBC����ֹͣ���";
BA_ "GenSigNote" SG_ 1441 BMSCellVol1_N_No1 "�����ѹ";
BA_ "GenSigNote" SG_ 672 BMS1_Checksum "У���";
BA_ "GenSigNote" SG_ 672 BMS1_F_BatteryFaultLevel "��ع���״̬";
BA_ "GenSigNote" SG_ 672 BMS1_St_BatteryMode "���ģʽ";
BA_ "GenSigNote" SG_ 672 BMS1_St_HVIL "������ذ���ѹ����״̬";
BA_ "GenSigNote" SG_ 672 BMS1_N_BatteryCurrent "��ص���";
BA_ "GenSigStartValue" SG_ 672 BMS1_N_BatteryCurrent 800;
BA_ "GenSigNote" SG_ 672 BMS1_N_BatteryVoltage "��ص�ѹ���Ӵ���֮ǰ��";
BA_ "GenSigNote" SG_ 672 BMS1_N_DCLinkVoltage "ĸ�ߵ�ѹ���Ӵ���֮��";
BA_ "GenSigNote" SG_ 672 BMS1_St_MainPositiveRelay "�����̵���״̬";
BA_ "GenSigNote" SG_ 672 BMS1_St_MainNegativeRelay "�����̵���״̬";
BA_ "GenSigNote" SG_ 672 BMS1_St_PrechargeRelay "Ԥ��̵���״̬";
BA_ "GenSigNote" SG_ 672 BMS1_St_QCPositiveRelay "������̵���״̬";
BA_ "GenSigNote" SG_ 672 BMS1_St_QCNegativeRelay "��为�̵���״̬";
BA_ "GenSigNote" SG_ 672 BMS1_RollingCounter "������";
BA_ "GenSigNote" SG_ 1184 BMS2_Checksum "Checksum";
BA_ "GenSigNote" SG_ 1184 BMS2_F_Isolation "��Ե����״̬";
BA_ "GenSigNote" SG_ 1184 BMS2_N_CellSumVoltage "�����ܺ͵�ѹ";
BA_ "GenSigNote" SG_ 1184 BMS2_N_SOE "��ص���SOE";
BA_ "GenSigNote" SG_ 1184 BMS2_N_SOH "��ؽ�����SOH";
BA_ "GenSigNote" SG_ 1184 BMS2_N_RSOC "��ع���SOC";
BA_ "GenSigNote" SG_ 1184 BMS2_RollingCounter "RollingCounter";
BA_ "GenSigNote" SG_ 1186 BMS4_F_CMATempDiff "�¶Ȳ��챨��";
BA_ "GenSigNote" SG_ 1186 BMS4_F_BattOverTemp "��ظ��±���";
BA_ "GenSigNote" SG_ 1186 BMS4_N_CMATempAve "ģ��ƽ���¶�";
BA_ "GenSigStartValue" SG_ 1186 BMS4_N_CMATempAve 40;
BA_ "GenSigNote" SG_ 1186 BMS4_N_CMATempMax "ģ������¶�";
BA_ "GenSigStartValue" SG_ 1186 BMS4_N_CMATempMax 40;
BA_ "GenSigNote" SG_ 1186 BMS4_N_CMATempMin "ģ����С�¶�";
BA_ "GenSigStartValue" SG_ 1186 BMS4_N_CMATempMin 40;
BA_ "GenSigNote" SG_ 1186 BMS4_N_InletTemp "��ȴҺ��ˮ���¶�";
BA_ "GenSigStartValue" SG_ 1186 BMS4_N_InletTemp 40;
BA_ "GenSigNote" SG_ 1186 BMS4_F_BattLowTemp1 "��ص��±���(��ֹDC���)";
BA_ "GenSigNote" SG_ 1186 BMS4_F_BattLowTemp2 "��ص��±�������ֹAC��磩";
BA_ "GenSigNote" SG_ 1186 BMS4_F_BattLowTemp3 "��ص��±�������ֹ�ŵ磩";
BA_ "GenSigNote" SG_ 1186 BMS4_N_BatPwrConsumption "��ع��ʣ������ܵ�ѹ���ص����ĳ˻���";
BA_ "GenSigStartValue" SG_ 1186 BMS4_N_BatPwrConsumption 3600;
BA_ "GenSigNote" SG_ 932 BMS6_Checksum "У���";
BA_ "GenSigNote" SG_ 932 BMS6_St_BatHeatingReq "��ؼ�������";
BA_ "GenSigNote" SG_ 932 BMS6_W_HVBattDanger "���Σ�ձ���";
BA_ "GenSigNote" SG_ 932 BMS6_RollingCounter "������";
BA_ "GenSigNote" SG_ 1188 BMS7_N_SOF10D "���10s���ŵ繦�ʣ���ֵ�ŵ�SOF��";
BA_ "GenSigNote" SG_ 1188 BMS7_N_SOFContinuousD "��س������ŵ繦�ʣ������ŵ�SOF��";
BA_ "GenSigNote" SG_ 1188 BMS7_N_SOF10C "���10s����繦�ʣ���ֵ����SOF��";
BA_ "GenSigNote" SG_ 1188 BMS7_N_SOF30C "���30s����繦�ʣ���������SOF��";
BA_ "GenSigNote" SG_ 1189 BMS8_N_SOF30D "���30s���ŵ繦��";
BA_ "GenSigNote" SG_ 1189 BMS8_N_SOF2D "���2s���ŵ繦��";
BA_ "GenSigNote" SG_ 1189 BMS8_N_SOF2C "���2s����繦��";
BA_ "GenSigNote" SG_ 1190 BMS10_N_CellVoltageAve "ƽ�������ѹ";
BA_ "GenSigNote" SG_ 1190 BMS10_InsChkState "��Ե���״̬";
BA_ "GenSigNote" SG_ 1190 BMS10_RelayChkState "�Ӵ���ճ�����״̬";
BA_ "GenSigNote" SG_ 1190 BMS10_ChargerWorkingEnable "�������ʹ��״̬";
BA_ "GenSigNote" SG_ 1190 BMS10_ChargeVoltageRequest "��������ѹ";
BA_ "GenSigNote" SG_ 1190 BMS10_ChargeCurrentRequest "����������";
BA_ "GenSigNote" SG_ 1190 BMS10_BatteryChargeStatus "���״̬";
BA_ "GenSigNote" SG_ 1680 DevBMS1_N_ColdFanPWM "���PWMֵ(�����ӳ��������ȴ״̬��)";
BA_ "GenSigStartValue" SG_ 1661 NMBMS_SourceID 125;
BA_ "GenSigNote" SG_ 867 BCM1_Checksum "checksum";
BA_ "GenSigNote" SG_ 867 BCM1_RollingCounter "rollingcounter";
BA_ "GenSigNote" SG_ 867 BCM1_St_KL15 "KL_15״̬��On��";
BA_ "GenSigNote" SG_ 867 BCM1_St_KLR "KL_R״̬��Acc��";
BA_ "GenSigNote" SG_ 867 BCM1_St_KL50 "KL_50״̬��Start��";
BA_ "GenSigNote" SG_ 304 BR1_Checksum "Checksum";
BA_ "GenSigNote" SG_ 304 BR1_RollingCounter "Rollingcounter";
BA_ "GenSigNote" SG_ 304 BR1_F_VehicleSpeed "����ֵ�Ƿ�Ϊ��Чֵ";
BA_ "GenSigStartValue" SG_ 304 BR1_F_VehicleSpeed 1;
BA_ "GenSigNote" SG_ 304 BR1_N_VehicleSpeed "����";
BA_ "GenSigNote" SG_ 400 HCU_1_BmsSleep "HCU����BMS����";
BA_ "GenSigNote" SG_ 400 HCU_1_WeldedFaultCheck "�Ӵ����Ͽ�ճ�����";
BA_ "GenSigNote" SG_ 400 HCU_1_InsCheck "��Ե������";
BA_ "GenSigNote" SG_ 400 HCU1_Checksum "Checksum";
BA_ "GenSigNote" SG_ 400 HCU1_RollingCounter "RollingCounter";
BA_ "GenSigNote" SG_ 400 HCU1_St_Ready "����ϵͳ׼������״̬";
BA_ "GenSigNote" SG_ 400 HCU1_F_HVConnectRequest "��ѹ����������Ч";
BA_ "GenSigStartValue" SG_ 400 HCU1_F_HVConnectRequest 1;
BA_ "GenSigNote" SG_ 400 HCU1_St_HVConnectRequest "��ѹ��������";
BA_ "GenSigNote" SG_ 1136 ICM1_Checksum "checksum";
BA_ "GenSigNote" SG_ 1136 ICM1_RollingCounter "Rollingcounter";
BA_ "GenSigNote" SG_ 1136 ICM1_N_Odograph "���";
BA_ "GenSigNote" SG_ 22 SDM1_Checksum "checksum";
BA_ "GenSigNote" SG_ 22 SDM1_RollingCounter "rollingcounter";
BA_ "GenSigNote" SG_ 22 SDM1_St_FrontCrash "ǰײ";
BA_ "GenSigNote" SG_ 22 SDM1_St_BackCrash "��ײ";
BA_ "GenSigNote" SG_ 22 SDM1_St_LeftCrash "��ײ";
BA_ "GenSigNote" SG_ 22 SDM1_St_RightCrash "��ײ";
BA_ "GenSigNote" SG_ 22 SDM1_St_CrashIntensity "��ײ�̶�";
BA_ "GenSigNote" SG_ 869 OBC_Status "OBC����״̬";
BA_ "GenSigNote" SG_ 869 OBC_CPStatus "CP״̬";
BA_ "GenSigNote" SG_ 869 OBC_OutputVoltage "OBC�����ѹ";
BA_ "GenSigNote" SG_ 869 OBC_Status_RelayWeldCheckRslt "�̵���ճ�������״̬";
BA_ "GenSigNote" SG_ 869 OBC_OutputCurrent "OBC�������";
BA_ "GenSigNote" SG_ 869 OBC_RQ_S2Relay_OnOff "����220V�������S2���ؼ̵�������/�Ͽ�����";
BA_ "GenSigNote" SG_ 869 OBC_ChargingStopResponse "OBC����ֹͣ���";
VAL_ 3221225472 BMS9_N_PosInsR_Copy_1 65535 "Error Value" ;
VAL_ 3221225472 BMS9_N_NegInsR 65535 "Error Value" ;
VAL_ 3221225472 BMS9_N_PosInsR 65535 "Error Value" ;
VAL_ 3221225472 BMS2_3_F_CellOverV 1 "Fault" 0 "No Fault" ;
VAL_ 3221225472 BMS2_3_F_CellUnderV 1 "Fault" 0 "No Fault" ;
VAL_ 3221225472 BMS2_3_F_CellVoltagedropout 1 "Fault" 0 "No Fault" ;
VAL_ 3221225472 BMS2_3_F_BattOverV 1 "Fault" 0 "No Fault" ;
VAL_ 3221225472 BMS2_3_F_BattUnderV 1 "Fault" 0 "No Fault" ;
VAL_ 3221225472 BMS2_9_F_BattSupplyingOverI 3 "Level3 Fault" 2 "Level2 Fault" 1 "Level1 Fault" 0 "Not Fault" ;
VAL_ 3221225472 BMS2_9_F_QCNegativeRelay 2 "Close Stuck" 1 "Open Stuck" 0 "Not Fault" ;
VAL_ 3221225472 BMS2_9_F_MainPositiveRelayCoil 2 "GND Stuck" 1 "Open Stuck" 0 "Not Fault" ;
VAL_ 3221225472 BMS2_9_F_MainNegativeRelayCoil 2 "GND Stuck" 1 "Open Stuck" 0 "Not Fault" ;
VAL_ 3221225472 BMS2_9_F_PrechargeRelayCoil 2 "GND Stuck" 1 "Open Stuck" 0 "Not Fault" ;
VAL_ 3221225472 BMS2_9_F_QCPositiveRelayCoil 2 "GND Stuck" 1 "Open Stuck" 0 "Not Fault" ;
VAL_ 3221225472 BMS2_9_F_MainPositiveRelay 2 "Close Stuck" 1 "Open Stuck" 0 "Not Fault" ;
VAL_ 3221225472 BMS2_9_F_QCNegativeRelayCoil 2 "GND Stuck" 1 "Open Stuck" 0 "Not Fault" ;
VAL_ 3221225472 BMS2_9_F_CellBalancingCircuit 1 "Fault" 0 "Not Fault" ;
VAL_ 3221225472 BMS2_9_F_BattOverChgErr 1 "Fault" 0 "Not Fault" ;
VAL_ 3221225472 BMS2_9_F_BattPluginChgOverI 3 "Level3 Fault" 2 "Level2 Fault" 1 "Level1 Fault" 0 "Not Fault" ;
VAL_ 3221225472 BMS2_9_F_PrechargeRelayOpenStuck 1 "Fault" 0 "Not Fault" ;
VAL_ 3221225472 BMS2_9_F_MSDFuse 1 "Fault" 0 "Not Fault" ;
VAL_ 3221225472 BMS2_9_F_HVBattTempRisingOverspe 1 "Fault" 0 "Not Fault" ;
VAL_ 3221225472 BMS2_9_F_BattRegenerativeOverI 3 "Level3 Fault" 2 "Level2 Fault" 1 "Level1 Fault" 0 "Not Fault" ;
VAL_ 3221225472 BMS2_9_F_MainNegativeRelay 2 "Close Stuck" 1 "Open Stuck" 0 "Not Fault" ;
VAL_ 3221225472 BMS2_9_F_PrechargeRelay 2 "Close Stuck" 1 "Open Stuck" 0 "Not Fault" ;
VAL_ 3221225472 BMS2_9_F_QCPositiveRelay 2 "Close Stuck" 1 "Open Stuck" 0 "Not Fault" ;
VAL_ 3221225472 BMS3_F_CellOverV 1 "Fault" 0 "No Fault" ;
VAL_ 3221225472 BMS3_F_CellUnderV 1 "Fault" 0 "No Fault" ;
VAL_ 3221225472 BMS3_F_CellVoltagedropout 1 "Fault" 0 "No Fault" ;
VAL_ 3221225472 BMS3_F_BattOverV 1 "Fault" 0 "No Fault" ;
VAL_ 3221225472 BMS3_F_BattUnderV 1 "Fault" 0 "No Fault" ;
VAL_ 3221225472 HCU_2_RelayOn 1 "Check" 0 "Discheck" ;
VAL_ 3221225472 HCU_2_PWM_LossOfCom 3 "reserved - same as 0x0 for now" 2 "reserved - same as 0x0 for now" 1 "remain the last received command until communicatino recovers" 0 "default - set output to 0%" ;
VAL_ 3221225472 HCU_2_OBCRelayStatus 1 "Relay On" 0 "Relay Off" ;
VAL_ 3221225472 HCU_2_ChargingStopRequest 0 "none" 1 "charging stop" 2 "error" 3 "Invalid" ;
VAL_ 3221225472 HCU_2_ChargerAllow 1 "allow" 0 "Not allow" ;
VAL_ 3221225472 HCU_2_CCStatus 1 "Connected" 0 "Disconnected" ;
VAL_ 3221225472 HCU2_2_RelayOn 1 "Check" 0 "Discheck" ;
VAL_ 3221225472 HCU2_2_PWM_LossOfCom 3 "reserved - same as 0x0 for now" 2 "reserved - same as 0x0 for now" 1 "remain the last received command until communicatino recovers" 0 "default - set output to 0%" ;
VAL_ 3221225472 HCU2_2_OBCRelayStatus 1 "Relay On" 0 "Relay Off" ;
VAL_ 3221225472 HCU2_2_ChargingStopRequest 0 "none" 1 "charging stop" 2 "error" 3 "Invalid" ;
VAL_ 3221225472 HCU2_2_ChargerAllow 1 "allow" 0 "Not allow
" ;
VAL_ 3221225472 HCU2_2_CCStatus 1 "Connected" 0 "Disconnected" ;
VAL_ 1192 BMS12_N_TempMinModule 43 "Module 22 Sensor 2" 42 "Module 22 Sensor 1" 41 "Module 21 Sensor 2" 40 "Module 21 Sensor 1" 39 "Module 20 Sensor 2" 38 "Module 20 Sensor 1" 37 "Module 19 Sensor 2" 36 "Module 19 Sensor 1" 35 "Module 18 Sensor 2" 34 "Module 18 Sensor 1" 33 "Module 17 Sensor 2" 32 "Module 17 Sensor 1" 31 "Module 16 Sensor 2" 30 "Module 16 Sensor 1" 29 "Module 15 Sensor 2 " 28 "Module 15 Sensor 1" 27 "Module 14 Sensor 2" 26 "Module 14 Sensor 1" 25 "Module 13 Sensor 2" 24 "Module 13 Sensor 1" 23 "Module 12 Sensor 2" 22 "Module 12 Sensor 1" 21 "Module 11 Sensor 2" 20 "Module 11 Sensor 1" 19 "Module 10 Sensor 2" 18 "Module 10 Sensor 1" 17 "Module 9 Sensor 2" 16 "Module 9 Sensor 1" 15 "Module 8 Sensor 2" 14 "Module 8 Sensor 1" 13 "Module 7 Sensor 2" 12 "Module 7 Sensor 1" 11 "Module 6 Sensor 2" 10 "Module 6 Sensor 1" 9 "Module 5 Sensor 2" 8 "Module 5 Sensor 1" 7 "Module 4 Sensor 2" 6 "Module 4 Sensor 1" 5 "Module 3 Sensor 2" 4 "Module 3 Sensor 1" 3 "Module 2 Sensor 2" 2 "Module 2 Sensor 1" 1 "Module 1 Sensor 2" 0 "Module 1 Sensor 1" ;
VAL_ 1192 BMS12_N_TempMaxModule 43 "Module 22 Sensor 2" 42 "Module 22 Sensor 1" 41 "Module 21 Sensor 2" 40 "Module 21 Sensor 1" 39 "Module 20 Sensor 2" 38 "Module 20 Sensor 1" 37 "Module 19 Sensor 2" 36 "Module 19 Sensor 1" 35 "Module 18 Sensor 2" 34 "Module 18 Sensor 1" 33 "Module 17 Sensor 2" 32 "Module 17 Sensor 1" 31 "Module 16 Sensor 2" 30 "Module 16 Sensor 1" 29 "Module 15 Sensor 2 " 28 "Module 15 Sensor 1" 27 "Module 14 Sensor 2" 26 "Module 14 Sensor 1" 25 "Module 13 Sensor 2" 24 "Module 13 Sensor 1" 23 "Module 12 Sensor 2" 22 "Module 12 Sensor 1" 21 "Module 11 Sensor 2" 20 "Module 11 Sensor 1" 19 "Module 10 Sensor 2" 18 "Module 10 Sensor 1" 17 "Module 9 Sensor 2" 16 "Module 9 Sensor 1" 15 "Module 8 Sensor 2" 14 "Module 8 Sensor 1" 13 "Module 7 Sensor 2" 12 "Module 7 Sensor 1" 11 "Module 6 Sensor 2" 10 "Module 6 Sensor 1" 9 "Module 5 Sensor 2" 8 "Module 5 Sensor 1" 7 "Module 4 Sensor 2" 6 "Module 4 Sensor 1" 5 "Module 3 Sensor 2" 4 "Module 3 Sensor 1" 3 "Module 2 Sensor 2" 2 "Module 2 Sensor 1" 1 "Module 1 Sensor 2" 0 "Module 1 Sensor 1" ;
VAL_ 1208 BMS2_12_N_TempMaxModule 43 "Module 22 Sensor 2" 42 "Module 22 Sensor 1" 41 "Module 21 Sensor 2" 40 "Module 21 Sensor 1" 39 "Module 20 Sensor 2" 38 "Module 20 Sensor 1" 37 "Module 19 Sensor 2" 36 "Module 19 Sensor 1" 35 "Module 18 Sensor 2" 34 "Module 18 Sensor 1" 33 "Module 17 Sensor 2" 32 "Module 17 Sensor 1" 31 "Module 16 Sensor 2" 30 "Module 16 Sensor 1" 29 "Module 15 Sensor 2 " 28 "Module 15 Sensor 1" 27 "Module 14 Sensor 2" 26 "Module 14 Sensor 1" 25 "Module 13 Sensor 2" 24 "Module 13 Sensor 1" 23 "Module 12 Sensor 2" 22 "Module 12 Sensor 1" 21 "Module 11 Sensor 2" 20 "Module 11 Sensor 1" 19 "Module 10 Sensor 2" 18 "Module 10 Sensor 1" 17 "Module 9 Sensor 2" 16 "Module 9 Sensor 1" 15 "Module 8 Sensor 2" 14 "Module 8 Sensor 1" 13 "Module 7 Sensor 2" 12 "Module 7 Sensor 1" 11 "Module 6 Sensor 2" 10 "Module 6 Sensor 1" 9 "Module 5 Sensor 2" 8 "Module 5 Sensor 1" 7 "Module 4 Sensor 2" 6 "Module 4 Sensor 1" 5 "Module 3 Sensor 2" 4 "Module 3 Sensor 1" 3 "Module 2 Sensor 2" 2 "Module 2 Sensor 1" 1 "Module 1 Sensor 2" 0 "Module 1 Sensor 1" ;
VAL_ 1208 BMS2_12_N_TempMinModule 43 "Module 22 Sensor 2" 42 "Module 22 Sensor 1" 41 "Module 21 Sensor 2" 40 "Module 21 Sensor 1" 39 "Module 20 Sensor 2" 38 "Module 20 Sensor 1" 37 "Module 19 Sensor 2" 36 "Module 19 Sensor 1" 35 "Module 18 Sensor 2" 34 "Module 18 Sensor 1" 33 "Module 17 Sensor 2" 32 "Module 17 Sensor 1" 31 "Module 16 Sensor 2" 30 "Module 16 Sensor 1" 29 "Module 15 Sensor 2 " 28 "Module 15 Sensor 1" 27 "Module 14 Sensor 2" 26 "Module 14 Sensor 1" 25 "Module 13 Sensor 2" 24 "Module 13 Sensor 1" 23 "Module 12 Sensor 2" 22 "Module 12 Sensor 1" 21 "Module 11 Sensor 2" 20 "Module 11 Sensor 1" 19 "Module 10 Sensor 2" 18 "Module 10 Sensor 1" 17 "Module 9 Sensor 2" 16 "Module 9 Sensor 1" 15 "Module 8 Sensor 2" 14 "Module 8 Sensor 1" 13 "Module 7 Sensor 2" 12 "Module 7 Sensor 1" 11 "Module 6 Sensor 2" 10 "Module 6 Sensor 1" 9 "Module 5 Sensor 2" 8 "Module 5 Sensor 1" 7 "Module 4 Sensor 2" 6 "Module 4 Sensor 1" 5 "Module 3 Sensor 2" 4 "Module 3 Sensor 1" 3 "Module 2 Sensor 2" 2 "Module 2 Sensor 1" 1 "Module 1 Sensor 2" 0 "Module 1 Sensor 1" ;
VAL_ 416 HCU2_1_BmsSleep 0 "none" 1 "go to sleep" 2 "wake up" 3 "Invalid" ;
VAL_ 416 HCU2_1_InsCheck 1 "Check" 0 "Discheck" ;
VAL_ 416 HCU2_1_WeldedFaultCheck 1 "Check" 0 "Discheck" ;
VAL_ 416 HCU2_1_St_Ready 1 "Ready" 0 "Not Ready" ;
VAL_ 416 HCU2_1_F_HVConnectRequest 1 "Valid" 0 "Invalid" ;
VAL_ 416 HCU2_1_St_HVConnectRequest 1 "Connect" 0 "Disconnect" ;
VAL_ 1201 BMS2_3_N_CellVoltageMin 8191 "Error Value" ;
VAL_ 1201 BMS2_3_N_CellVoltageMax 8191 "Error Value" ;
VAL_ 1201 BMS2_3_N_NegInsR 65535 "Error Value" ;
VAL_ 1201 BMS2_3_N_PosInsR 65535 "Error Value" ;
VAL_ 1185 BMS3_N_CellVoltageMin 8191 "Error Value" ;
VAL_ 1185 BMS3_N_CellVoltageMax 8191 "Error Value" ;
VAL_ 1185 BMS3_N_NegInsR 65535 "Error Value" ;
VAL_ 1185 BMS3_N_PosInsR 65535 "Error Value" ;
VAL_ 1483 BCM2Diag_VoltRangeFault 2 "History" 1 "Current" 0 "No_Fault" ;
VAL_ 1483 BCM2Diag_TtlVoltSampAbnorm 2 "History" 1 "Current" 0 "No_Fault" ;
VAL_ 1483 BCM2Diag_TempRangeFault 2 "History" 1 "Current" 0 "No_Fault" ;
VAL_ 1483 BCM2Diag_SuppVoltTooLow 2 "History" 1 "Current" 0 "No_Fault" ;
VAL_ 1483 BCM2Diag_SeriousOvercurrFault 2 "History" 1 "Current" 0 "No_Fault" ;
VAL_ 1483 BCM2Diag_SDMCommLost 2 "History" 1 "Current" 0 "No_Fault" ;
VAL_ 1483 BCM2Diag_RTCFault 2 "History" 1 "Current" 0 "No_Fault" ;
VAL_ 1483 BCM2Diag_PrsrSnsrShrtToGnd 2 "History" 1 "Current" 0 "No_Fault" ;
VAL_ 1483 BCM2Diag_PrsrSnsrOC 2 "History" 1 "Current" 0 "No_Fault" ;
VAL_ 1483 BCM2Diag_PrechrgWthLoadFault 2 "History" 1 "Current" 0 "No_Fault" ;
VAL_ 1483 BCM2Diag_PrechrgRelayCantClose 2 "History" 1 "Current" 0 "No_Fault" ;
VAL_ 1483 BCM2Diag_PrechrgFail 2 "History" 1 "Current" 0 "No_Fault" ;
VAL_ 1483 BCM2Diag_PosRelayStuck 2 "History" 1 "Current" 0 "No_Fault" ;
VAL_ 1483 BCM2Diag_PosRelayCantClose 2 "History" 1 "Current" 0 "No_Fault" ;
VAL_ 1483 BCM2Diag_PackVoltTooLowLvl2 2 "History" 1 "Current" 0 "No_Fault" ;
VAL_ 1483 BCM2Diag_PackVoltTooLowLvl1 2 "History" 1 "Current" 0 "No_Fault" ;
VAL_ 1483 BCM2Diag_PackVoltTooHighLvl2 2 "History" 1 "Current" 0 "No_Fault" ;
VAL_ 1483 BCM2Diag_PackVoltTooHighLvl1 2 "History" 1 "Current" 0 "No_Fault" ;
VAL_ 1483 BCM2Diag_NVMFault 2 "History" 1 "Current" 0 "No_Fault" ;
VAL_ 1483 BCM2Diag_NegRelayStuck 2 "History" 1 "Current" 0 "No_Fault" ;
VAL_ 1483 BCM2Diag_NegRelayCantClose 2 "History" 1 "Current" 0 "No_Fault" ;
VAL_ 1483 BCM2Diag_LeakSnsrShrtToGnd 2 "History" 1 "Current" 0 "No_Fault" ;
VAL_ 1483 BCM2Diag_LeakSnsrOC 2 "History" 1 "Current" 0 "No_Fault" ;
VAL_ 1483 BCM2Diag_InsFaultLvl3 2 "History" 1 "Current" 0 "No_Fault" ;
VAL_ 1483 BCM2Diag_InsFaultLvl2 2 "History" 1 "Current" 0 "No_Fault" ;
VAL_ 1483 BCM2Diag_InsFaultLvl1 2 "History" 1 "Current" 0 "No_Fault" ;
VAL_ 1483 BCM2Diag_HVModCommLoss 2 "History" 1 "Current" 0 "No_Fault" ;
VAL_ 1483 BCM2Diag_HVILFault 2 "History" 1 "Current" 0 "No_Fault" ;
VAL_ 1483 BCM2Diag_GenertdCurrTooHighLvl2 2 "History" 1 "Current" 0 "No_Fault" ;
VAL_ 1483 BCM2Diag_GenertdCurrTooHighLvl1 2 "History" 1 "Current" 0 "No_Fault" ;
VAL_ 1483 BCM2Diag_FuseFault 2 "History" 1 "Current" 0 "No_Fault" ;
VAL_ 1483 BCM2Diag_DischrgCurrTooHighLvl2 2 "History" 1 "Current" 0 "No_Fault" ;
VAL_ 1483 BCM2Diag_DischrgCurrTooHighLvl1 2 "History" 1 "Current" 0 "No_Fault" ;
VAL_ 1483 BCM2Diag_CurrSnsrNoComRelayStuck 2 "History" 1 "Current" 0 "No_Fault" ;
VAL_ 1483 BCM2Diag_CurrSnsrFault 2 "History" 1 "Current" 0 "No_Fault" ;
VAL_ 1483 BCM2Diag_CurrSnsrCommTimedout 2 "History" 1 "Current" 0 "No_Fault" ;
VAL_ 1483 BCM2Diag_CellVoltSamplLineBrk 2 "History" 1 "Current" 0 "No_Fault" ;
VAL_ 1483 BCM2Diag_CellVoltDiffHigh 2 "History" 1 "Current" 0 "No_Fault" ;
VAL_ 1483 BCM2Diag_CellUndrVoltLvl3 2 "History" 1 "Current" 0 "No_Fault" ;
VAL_ 1483 BCM2Diag_CellUndrVoltLvl2 2 "History" 1 "Current" 0 "No_Fault" ;
VAL_ 1483 BCM2Diag_CellundrVoltLvl1 2 "History" 1 "Current" 0 "No_Fault" ;
VAL_ 1483 BCM2Diag_CellTempTooLowLvl3 2 "History" 1 "Current" 0 "No_Fault" ;
VAL_ 1483 BCM2Diag_CellTempTooLowLvl2 2 "History" 1 "Current" 0 "No_Fault" ;
VAL_ 1483 BCM2Diag_CellTempTooLowLvl1 2 "History" 1 "Current" 0 "No_Fault" ;
VAL_ 1483 BCM2Diag_CellTempTooHighLvl2 2 "History" 1 "Current" 0 "No_Fault" ;
VAL_ 1483 BCM2Diag_CellTempTooHighLvl1 2 "History" 1 "Current" 0 "No_Fault" ;
VAL_ 1483 BCM2Diag_CellTempTooHighLv3 2 "History" 1 "Current" 0 "No_Fault" ;
VAL_ 1483 BCM2Diag_CellTempSamplLineBrk 2 "History" 1 "Current" 0 "No_Fault" ;
VAL_ 1483 BCM2Diag_CellTempDiffHigh 2 "History" 1 "Current" 0 "No_Fault" ;
VAL_ 1483 BCM2Diag_CellOvrVoltLvl3 2 "History" 1 "Current" 0 "No_Fault" ;
VAL_ 1483 BCM2Diag_CellOvrVoltLvl2 2 "History" 1 "Current" 0 "No_Fault" ;
VAL_ 1483 BCM2Diag_CellOvrVoltLvl1 2 "History" 1 "Current" 0 "No_Fault" ;
VAL_ 1483 BCM2Diag_CellBalancFault 2 "History" 1 "Current" 0 "No_Fault" ;
VAL_ 1483 BCM2Diag_CANCRCFailure 2 "History" 1 "Current" 0 "No_Fault" ;
VAL_ 1483 BCM2Diag_CANCounterAbnormal 2 "History" 1 "Current" 0 "No_Fault" ;
VAL_ 1483 BCM2Diag_BilatrlPosNegRelayStuck 2 "History" 1 "Current" 0 "No_Fault" ;
VAL_ 1483 BCM2Diag_AirTempSnsrShrtToGnd 2 "History" 1 "Current" 0 "No_Fault" ;
VAL_ 1483 BCM2Diag_AirTempSnsrOC 2 "History" 1 "Current" 0 "No_Fault" ;
VAL_ 1483 BCM2Diag_AFECommLost 2 "History" 1 "Current" 0 "No_Fault" ;
VAL_ 1483 BCM2Diag_12VBattVoltTooLow 2 "History" 1 "Current" 0 "No_Fault" ;
VAL_ 1483 BCM2Diag_12VBattVoltTooHigh 2 "History" 1 "Current" 0 "No_Fault" ;
VAL_ 1440 BCM1Diag_VoltRangeFault 2 "History" 1 "Current" 0 "No_Fault" ;
VAL_ 1440 BCM1Diag_TtlVoltSampAbnorm 2 "History" 1 "Current" 0 "No_Fault" ;
VAL_ 1440 BCM1Diag_TempRangeFault 2 "History" 1 "Current" 0 "No_Fault" ;
VAL_ 1440 BCM1Diag_SuppVoltTooLow 2 "History" 1 "Current" 0 "No_Fault" ;
VAL_ 1440 BCM1Diag_SeriousOvercurrFault 2 "History" 1 "Current" 0 "No_Fault" ;
VAL_ 1440 BCM1Diag_SDMCommLost 2 "History" 1 "Current" 0 "No_Fault" ;
VAL_ 1440 BCM1Diag_RTCFault 2 "History" 1 "Current" 0 "No_Fault" ;
VAL_ 1440 BCM1Diag_PrsrSnsrShrtToGnd 2 "History" 1 "Current" 0 "No_Fault" ;
VAL_ 1440 BCM1Diag_PrsrSnsrOC 2 "History" 1 "Current" 0 "No_Fault" ;
VAL_ 1440 BCM1Diag_PrechrgWthLoadFault 2 "History" 1 "Current" 0 "No_Fault" ;
VAL_ 1440 BCM1Diag_PrechrgRelayCantClose 2 "History" 1 "Current" 0 "No_Fault" ;
VAL_ 1440 BCM1Diag_PrechrgFail 2 "History" 1 "Current" 0 "No_Fault" ;
VAL_ 1440 BCM1Diag_PosRelayStuck 2 "History" 1 "Current" 0 "No_Fault" ;
VAL_ 1440 BCM1Diag_PosRelayCantClose 2 "History" 1 "Current" 0 "No_Fault" ;
VAL_ 1440 BCM1Diag_PackVoltTooLowLvl2 2 "History" 1 "Current" 0 "No_Fault" ;
VAL_ 1440 BCM1Diag_PackVoltTooLowLvl1 2 "History" 1 "Current" 0 "No_Fault" ;
VAL_ 1440 BCM1Diag_PackVoltTooHighLvl2 2 "History" 1 "Current" 0 "No_Fault" ;
VAL_ 1440 BCM1Diag_PackVoltTooHighLvl1 2 "History" 1 "Current" 0 "No_Fault" ;
VAL_ 1440 BCM1Diag_NVMFault 2 "History" 1 "Current" 0 "No_Fault" ;
VAL_ 1440 BCM1Diag_NegRelayStuck 2 "History" 1 "Current" 0 "No_Fault" ;
VAL_ 1440 BCM1Diag_NegRelayCantClose 2 "History" 1 "Current" 0 "No_Fault" ;
VAL_ 1440 BCM1Diag_LeakSnsrShrtToGnd 2 "History" 1 "Current" 0 "No_Fault" ;
VAL_ 1440 BCM1Diag_LeakSnsrOC 2 "History" 1 "Current" 0 "No_Fault" ;
VAL_ 1440 BCM1Diag_InsFaultLvl3 2 "History" 1 "Current" 0 "No_Fault" ;
VAL_ 1440 BCM1Diag_InsFaultLvl2 2 "History" 1 "Current" 0 "No_Fault" ;
VAL_ 1440 BCM1Diag_InsFaultLvl1 2 "History" 1 "Current" 0 "No_Fault" ;
VAL_ 1440 BCM1Diag_HVModCommLoss 2 "History" 1 "Current" 0 "No_Fault" ;
VAL_ 1440 BCM1Diag_HVILFault 2 "History" 1 "Current" 0 "No_Fault" ;
VAL_ 1440 BCM1Diag_GenertdCurrTooHighLvl2 2 "History" 1 "Current" 0 "No_Fault" ;
VAL_ 1440 BCM1Diag_GenertdCurrTooHighLvl1 2 "History" 1 "Current" 0 "No_Fault" ;
VAL_ 1440 BCM1Diag_FuseFault 2 "History" 1 "Current" 0 "No_Fault" ;
VAL_ 1440 BCM1Diag_DischrgCurrTooHighLvl2 2 "History" 1 "Current" 0 "No_Fault" ;
VAL_ 1440 BCM1Diag_DischrgCurrTooHighLvl1 2 "History" 1 "Current" 0 "No_Fault" ;
VAL_ 1440 BCM1Diag_CurrSnsrNoComRelayStuck 2 "History" 1 "Current" 0 "No_Fault" ;
VAL_ 1440 BCM1Diag_CurrSnsrFault 2 "History" 1 "Current" 0 "No_Fault" ;
VAL_ 1440 BCM1Diag_CurrSnsrCommTimedout 2 "History" 1 "Current" 0 "No_Fault" ;
VAL_ 1440 BCM1Diag_CellVoltSamplLineBrk 2 "History" 1 "Current" 0 "No_Fault" ;
VAL_ 1440 BCM1Diag_CellVoltDiffHigh 2 "History" 1 "Current" 0 "No_Fault" ;
VAL_ 1440 BCM1Diag_CellUndrVoltLvl3 2 "History" 1 "Current" 0 "No_Fault" ;
VAL_ 1440 BCM1Diag_CellUndrVoltLvl2 2 "History" 1 "Current" 0 "No_Fault" ;
VAL_ 1440 BCM1Diag_CellundrVoltLvl1 2 "History" 1 "Current" 0 "No_Fault" ;
VAL_ 1440 BCM1Diag_CellTempTooLowLvl3 2 "History" 1 "Current" 0 "No_Fault" ;
VAL_ 1440 BCM1Diag_CellTempTooLowLvl2 2 "History" 1 "Current" 0 "No_Fault" ;
VAL_ 1440 BCM1Diag_CellTempTooLowLvl1 2 "History" 1 "Current" 0 "No_Fault" ;
VAL_ 1440 BCM1Diag_CellTempTooHighLvl2 2 "History" 1 "Current" 0 "No_Fault" ;
VAL_ 1440 BCM1Diag_CellTempTooHighLvl1 2 "History" 1 "Current" 0 "No_Fault" ;
VAL_ 1440 BCM1Diag_CellTempTooHighLv3 2 "History" 1 "Current" 0 "No_Fault" ;
VAL_ 1440 BCM1Diag_CellTempSamplLineBrk 2 "History" 1 "Current" 0 "No_Fault" ;
VAL_ 1440 BCM1Diag_CellTempDiffHigh 2 "History" 1 "Current" 0 "No_Fault" ;
VAL_ 1440 BCM1Diag_CellOvrVoltLvl3 2 "History" 1 "Current" 0 "No_Fault" ;
VAL_ 1440 BCM1Diag_CellOvrVoltLvl2 2 "History" 1 "Current" 0 "No_Fault" ;
VAL_ 1440 BCM1Diag_CellOvrVoltLvl1 2 "History" 1 "Current" 0 "No_Fault" ;
VAL_ 1440 BCM1Diag_CellBalancFault 2 "History" 1 "Current" 0 "No_Fault" ;
VAL_ 1440 BCM1Diag_CANCRCFailure 2 "History" 1 "Current" 0 "No_Fault" ;
VAL_ 1440 BCM1Diag_CANCounterAbnormal 2 "History" 1 "Current" 0 "No_Fault" ;
VAL_ 1440 BCM1Diag_BilatrlPosNegRelayStuck 2 "History" 1 "Current" 0 "No_Fault" ;
VAL_ 1440 BCM1Diag_AirTempSnsrShrtToGnd 2 "History" 1 "Current" 0 "No_Fault" ;
VAL_ 1440 BCM1Diag_AirTempSnsrOC 2 "History" 1 "Current" 0 "No_Fault" ;
VAL_ 1440 BCM1Diag_AFECommLost 2 "History" 1 "Current" 0 "No_Fault" ;
VAL_ 1440 BCM1Diag_12VBattVoltTooLow 2 "History" 1 "Current" 0 "No_Fault" ;
VAL_ 1440 BCM1Diag_12VBattVoltTooHigh 2 "History" 1 "Current" 0 "No_Fault" ;
VAL_ 1469 BMS2_CMATemp_N_No9 255 "Error Value" ;
VAL_ 1469 BMS2_CMATemp_N_No24 255 "Error Value" ;
VAL_ 1469 BMS2_CMATemp_N_No23 255 "Error Value" ;
VAL_ 1469 BMS2_CMATemp_N_No22 255 "Error Value" ;
VAL_ 1469 BMS2_CMATemp_N_No21 255 "Error Value" ;
VAL_ 1469 BMS2_CMATemp_N_No20 255 "Error Value" ;
VAL_ 1469 BMS2_CMATemp_N_No19 255 "Error Value" ;
VAL_ 1469 BMS2_CMATemp_N_No18 255 "Error Value" ;
VAL_ 1469 BMS2_CMATemp_N_No17 255 "Error Value" ;
VAL_ 1469 BMS2_CMATemp_N_No16 255 "Error Value" ;
VAL_ 1469 BMS2_CMATemp_N_No15 255 "Error Value" ;
VAL_ 1469 BMS2_CMATemp_N_No14 255 "Error Value" ;
VAL_ 1469 BMS2_CMATemp_N_No13 255 "Error Value" ;
VAL_ 1469 BMS2_CMATemp_N_No12 255 "Error Value" ;
VAL_ 1469 BMS2_CMATemp_N_No11 255 "Error Value" ;
VAL_ 1469 BMS2_CMATemp_N_No10 255 "Error Value" ;
VAL_ 1469 BMS2_CMATemp_N_No1 255 "Error Value" ;
VAL_ 1469 BMS2_CMATemp_N_No3 255 "Error Value" ;
VAL_ 1469 BMS2_CMATemp_N_No4 255 "Error Value" ;
VAL_ 1469 BMS2_CMATemp_N_No5 255 "Error Value" ;
VAL_ 1469 BMS2_CMATemp_N_No6 255 "Error Value" ;
VAL_ 1469 BMS2_CMATemp_N_No7 255 "Error Value" ;
VAL_ 1469 BMS2_CMATemp_N_No8 255 "Error Value" ;
VAL_ 1469 BMS2_CMATemp_N_No2 255 "Error Value" ;
VAL_ 1457 BMS2_CellVol1_N_No1 255 "Error Value" ;
VAL_ 1457 BMS2_CellVol1_N_No3 255 "Error Value" ;
VAL_ 1457 BMS2_CellVol1_N_No4 255 "Error Value" ;
VAL_ 1457 BMS2_CellVol1_N_No5 255 "Error Value" ;
VAL_ 1457 BMS2_CellVol1_N_No6 255 "Error Value" ;
VAL_ 1457 BMS2_CellVol1_N_No7 255 "Error Value" ;
VAL_ 1457 BMS2_CellVol1_N_No8 255 "Error Value" ;
VAL_ 1457 BMS2_CellVol1_N_No2 255 "Error Value" ;
VAL_ 1466 BMS2_CellVol10_N_No73 255 "Error Value" ;
VAL_ 1466 BMS2_CellVol10_N_No75 255 "Error Value" ;
VAL_ 1466 BMS2_CellVol10_N_No76 255 "Error Value" ;
VAL_ 1466 BMS2_CellVol10_N_No77 255 "Error Value" ;
VAL_ 1466 BMS2_CellVol10_N_No78 255 "Error Value" ;
VAL_ 1466 BMS2_CellVol10_N_No79 255 "Error Value" ;
VAL_ 1466 BMS2_CellVol10_N_No80 255 "Error Value" ;
VAL_ 1466 BMS2_CellVol10_N_No74 255 "Error Value" ;
VAL_ 1467 BMS2_CellVol11_N_No81 255 "Error Value" ;
VAL_ 1467 BMS2_CellVol11_N_No83 255 "Error Value" ;
VAL_ 1467 BMS2_CellVol11_N_No84 255 "Error Value" ;
VAL_ 1467 BMS2_CellVol11_N_No85 255 "Error Value" ;
VAL_ 1467 BMS2_CellVol11_N_No86 255 "Error Value" ;
VAL_ 1467 BMS2_CellVol11_N_No87 255 "Error Value" ;
VAL_ 1467 BMS2_CellVol11_N_No88 255 "Error Value" ;
VAL_ 1467 BMS2_CellVol11_N_No82 255 "Error Value" ;
VAL_ 1468 BMS2_CellVol12_N_No89 255 "Error Value" ;
VAL_ 1468 BMS2_CellVol12_N_No91 255 "Error Value" ;
VAL_ 1468 BMS2_CellVol12_N_No92 255 "Error Value" ;
VAL_ 1468 BMS2_CellVol12_N_No93 255 "Error Value" ;
VAL_ 1468 BMS2_CellVol12_N_No94 255 "Error Value" ;
VAL_ 1468 BMS2_CellVol12_N_No95 255 "Error Value" ;
VAL_ 1468 BMS2_CellVol12_N_No96 255 "Error Value" ;
VAL_ 1468 BMS2_CellVol12_N_No90 255 "Error Value" ;
VAL_ 1458 BMS2_CellVol2_N_No9 255 "Error Value" ;
VAL_ 1458 BMS2_CellVol2_N_No11 255 "Error Value" ;
VAL_ 1458 BMS2_CellVol2_N_No12 255 "Error Value" ;
VAL_ 1458 BMS2_CellVol2_N_No13 255 "Error Value" ;
VAL_ 1458 BMS2_CellVol2_N_No14 255 "Error Value" ;
VAL_ 1458 BMS2_CellVol2_N_No15 255 "Error Value" ;
VAL_ 1458 BMS2_CellVol2_N_No16 255 "Error Value" ;
VAL_ 1458 BMS2_CellVol2_N_No10 255 "Error Value" ;
VAL_ 1459 BMS2_CellVol3_N_No17 255 "Error Value" ;
VAL_ 1459 BMS2_CellVol3_N_No19 255 "Error Value" ;
VAL_ 1459 BMS2_CellVol3_N_No20 255 "Error Value" ;
VAL_ 1459 BMS2_CellVol3_N_No21 255 "Error Value" ;
VAL_ 1459 BMS2_CellVol3_N_No22 255 "Error Value" ;
VAL_ 1459 BMS2_CellVol3_N_No23 255 "Error Value" ;
VAL_ 1459 BMS2_CellVol3_N_No24 255 "Error Value" ;
VAL_ 1459 BMS2_CellVol3_N_No18 255 "Error Value" ;
VAL_ 1460 BMS2_CellVol4_N_No25 255 "Error Value" ;
VAL_ 1460 BMS2_CellVol4_N_No27 255 "Error Value" ;
VAL_ 1460 BMS2_CellVol4_N_No28 255 "Error Value" ;
VAL_ 1460 BMS2_CellVol4_N_No29 255 "Error Value" ;
VAL_ 1460 BMS2_CellVol4_N_No30 255 "Error Value" ;
VAL_ 1460 BMS2_CellVol4_N_No31 255 "Error Value" ;
VAL_ 1460 BMS2_CellVol4_N_No32 255 "Error Value" ;
VAL_ 1460 BMS2_CellVol4_N_No26 255 "Error Value" ;
VAL_ 1461 BMS2_CellVol5_N_No33 255 "Error Value" ;
VAL_ 1461 BMS2_CellVol5_N_No35 255 "Error Value" ;
VAL_ 1461 BMS2_CellVol5_N_No36 255 "Error Value" ;
VAL_ 1461 BMS2_CellVol5_N_No37 255 "Error Value" ;
VAL_ 1461 BMS2_CellVol5_N_No38 255 "Error Value" ;
VAL_ 1461 BMS2_CellVol5_N_No39 255 "Error Value" ;
VAL_ 1461 BMS2_CellVol5_N_No40 255 "Error Value" ;
VAL_ 1461 BMS2_CellVol5_N_No34 255 "Error Value" ;
VAL_ 1462 BMS2_CellVol6_N_No41 255 "Error Value" ;
VAL_ 1462 BMS2_CellVol6_N_No43 255 "Error Value" ;
VAL_ 1462 BMS2_CellVol6_N_No44 255 "Error Value" ;
VAL_ 1462 BMS2_CellVol6_N_No45 255 "Error Value" ;
VAL_ 1462 BMS2_CellVol6_N_No46 255 "Error Value" ;
VAL_ 1462 BMS2_CellVol6_N_No47 255 "Error Value" ;
VAL_ 1462 BMS2_CellVol6_N_No48 255 "Error Value" ;
VAL_ 1462 BMS2_CellVol6_N_No42 255 "Error Value" ;
VAL_ 1463 BMS2_CellVol7_N_No49 255 "Error Value" ;
VAL_ 1463 BMS2_CellVol7_N_No51 255 "Error Value" ;
VAL_ 1463 BMS2_CellVol7_N_No52 255 "Error Value" ;
VAL_ 1463 BMS2_CellVol7_N_No53 255 "Error Value" ;
VAL_ 1463 BMS2_CellVol7_N_No54 255 "Error Value" ;
VAL_ 1463 BMS2_CellVol7_N_No55 255 "Error Value" ;
VAL_ 1463 BMS2_CellVol7_N_No56 255 "Error Value" ;
VAL_ 1463 BMS2_CellVol7_N_No50 255 "Error Value" ;
VAL_ 1464 BMS2_CellVol8_N_No57 255 "Error Value" ;
VAL_ 1464 BMS2_CellVol8_N_No59 255 "Error Value" ;
VAL_ 1464 BMS2_CellVol8_N_No60 255 "Error Value" ;
VAL_ 1464 BMS2_CellVol8_N_No61 255 "Error Value" ;
VAL_ 1464 BMS2_CellVol8_N_No62 255 "Error Value" ;
VAL_ 1464 BMS2_CellVol8_N_No63 255 "Error Value" ;
VAL_ 1464 BMS2_CellVol8_N_No64 255 "Error Value" ;
VAL_ 1464 BMS2_CellVol8_N_No58 255 "Error Value" ;
VAL_ 1465 BMS2_CellVol9_N_No65 255 "Error Value" ;
VAL_ 1465 BMS2_CellVol9_N_No67 255 "Error Value" ;
VAL_ 1465 BMS2_CellVol9_N_No68 255 "Error Value" ;
VAL_ 1465 BMS2_CellVol9_N_No69 255 "Error Value" ;
VAL_ 1465 BMS2_CellVol9_N_No70 255 "Error Value" ;
VAL_ 1465 BMS2_CellVol9_N_No71 255 "Error Value" ;
VAL_ 1465 BMS2_CellVol9_N_No72 255 "Error Value" ;
VAL_ 1465 BMS2_CellVol9_N_No66 255 "Error Value" ;
VAL_ 688 BMS2_1_F_BatteryFaultLevel 15 "Error Value" 5 "Very Serious(Power Derating:Cut off relay by BMS2_ after 2s)" 4 "Serious(Power Derating:Cut off relay by HCU vai CAN Command)" 3 "Serious but not relay off(Power Derating to Zero by BMS2_)" 2 "Minor fault but derating(Power Derating by BMS2_)" 1 "Minor fault(No effect on SOF)" 0 "Normal" ;
VAL_ 688 BMS2_1_St_BatteryMode 15 "Error Value" 7 "Failure(Diag-Level 5)" 6 "Battery Heating" 5 "Power off" 4 "DC Charge" 3 "AC Charge" 2 "Supplying" 0 "Init" ;
VAL_ 688 BMS2_1_St_HVIL 1 "Disconnected" 0 "Connected" ;
VAL_ 688 BMS2_1_N_BatteryCurrent 2047 "Error Value" ;
VAL_ 688 BMS2_1_St_PrechargeMode 7 "Error Value" 4 "Precharge Inhibited" 3 "Precharge Failed" 2 "Precharge Finished" 1 "Precharging" 0 "Standby" ;
VAL_ 688 BMS2_1_N_BatteryVoltage 1023 "Error Value" ;
VAL_ 688 BMS2_1_N_DCLinkVoltage 1023 "Error Value" ;
VAL_ 688 BMS2_1_St_MainPositiveRelay 1 "Connected" 0 "Disconnected" ;
VAL_ 688 BMS2_1_St_MainNegativeRelay 1 "Connected" 0 "Disconnected" ;
VAL_ 688 BMS2_1_St_PrechargeRelay 1 "Connected" 0 "Disconnected" ;
VAL_ 688 BMS2_1_St_QCPositiveRelay 1 "Connected" 0 "Disconnected" ;
VAL_ 688 BMS2_1_St_QCNegativeRelay 1 "Connected" 0 "Disconnected" ;
VAL_ 1200 BMS2_2_F_Isolation 1 "Fault" 0 "No Fault" ;
VAL_ 1200 BMS2_2_N_CellSumVoltage 1023 "Error Value" ;
VAL_ 1200 BMS2_2_N_SOE 1023 "Error Value" ;
VAL_ 1200 BMS2_2_N_SOH 255 "Error Value" ;
VAL_ 1200 BMS2_2_N_RSOC 255 "Error Value" ;
VAL_ 1202 BMS2_4_F_CMATempDiff 1 "Fault" 0 "No Fault" ;
VAL_ 1202 BMS2_4_F_BattOverTemp 3 "Level 3, Derating to Zero" 2 "Level 2, Derating(Not Zero)" 1 "Level 1, Warning" 0 "Normal" ;
VAL_ 1202 BMS2_4_N_CMATempAve 255 "Error Value" ;
VAL_ 1202 BMS2_4_N_CMATempMax 255 "Error Value" ;
VAL_ 1202 BMS2_4_N_CMATempMin 255 "Error Value" ;
VAL_ 1202 BMS2_4_N_InletTemp 255 "Error Value" ;
VAL_ 1202 BMS2_4_F_BattLowTemp1 1 "Low Temperature ��Prohibit DC Charge" 0 "Normal" ;
VAL_ 1202 BMS2_4_F_BattLowTemp2 1 "Low Temperature ��Prohibit AC Charge" 0 "Normal" ;
VAL_ 1202 BMS2_4_F_BattLowTemp3 1 "Low Temperature ��Prohibit Discharge" 0 "Normal" ;
VAL_ 1202 BMS2_4_N_BatPwrConsumption 8191 "Error Value" ;
VAL_ 948 BMS2_6_St_BatHeatingReq 1 "Request" 0 "Not Request" ;
VAL_ 948 BMS2_6_W_HVBattDanger 1 "Warning" 0 "Not warning" ;
VAL_ 1204 BMS2_7_N_SOF10D 2047 "Error Value" ;
VAL_ 1204 BMS2_7_N_SOFContinuousD 2047 "Error Value" ;
VAL_ 1204 BMS2_7_N_SOF10C 2047 "Error Value" ;
VAL_ 1204 BMS2_7_N_SOF30C 2047 "Error Value" ;
VAL_ 1205 BMS2_8_N_SOF30D 2047 "Error Value" ;
VAL_ 1205 BMS2_8_N_SOF2D 2047 "Error Value" ;
VAL_ 1205 BMS2_8_N_SOF2C 2047 "Error Value" ;
VAL_ 1206 BMS2_10_DCFCWeldChk 2 "System check completed��please restart vehicle
 1 System checking, please wait
 0 No error" ;
VAL_ 1206 BMS2_10_N_CellVoltageAve 8191 "Error Value" ;
VAL_ 1206 BMS2_10_InsChkState 1 "System checking" 0 "No error" 2 "System check completed" ;
VAL_ 1206 BMS2_10_RelayChkState 1 "System checking
" 0 "No error" 2 "System check completed" ;
VAL_ 1206 BMS2_10_ChargerWorkingEnable 0 "Not Enable
 1 Enable" ;
VAL_ 1206 BMS2_10_BatteryChargeStatus 0 "Idle
 1 Charging" 2 "Normal Charge Finish
 3 Abnormal Charge Fault" ;
VAL_ 1696 DevBMS2_1_N_ColdFanPWM 255 "Error Value" ;
VAL_ 1677 NMBMS2__RepeatFromSleep 1 "occur" 0 "not occur" ;
VAL_ 1677 NMBMS2__RepeatFromPrepare 1 "occur" 0 "not occur" ;
VAL_ 1677 NMBMS2__RepeatFromNormal 1 "occur" 0 "not occur" ;
VAL_ 1677 NMBMS2__RepeatFromReady 1 "occur" 0 "not occur" ;
VAL_ 1677 NMBMS2__NormalFromRepeat 1 "occur" 0 "not occur" ;
VAL_ 1677 NMBMS2__NormalFromReady 1 "occur" 0 "not occur" ;
VAL_ 1677 NMBMS2__WakeFromGW 1 "occur" 0 "not occur" ;
VAL_ 1677 NMBMS2__GWRequest 1 "request" 0 "not request" ;
VAL_ 1677 NMBMS2__WakeSource 4 "External Charging Equipment��DC��" 1 "KL.15" 0 "CAN wakeup" ;
VAL_ 1677 NMBMS2__ActiveSource1 1 "KL15" 0 "not active" ;
VAL_ 1677 NMBMS2__ActiveSource2 1 "Diagnose" 0 "not active" ;
VAL_ 1677 NMBMS2__ActiveSource3 1 "Repeat message timer has not expired" 0 "not active" ;
VAL_ 1677 NMBMS2__ActiveSource4 1 "AC Charging" 0 "not active" ;
VAL_ 1677 NMBMS2__ActiveSource5 1 "DC Charging" 0 "not active" ;
VAL_ 1677 NMBMS2__RepeatReq 1 "request" 0 "not request" ;
VAL_ 883 BCM2_1_St_KL15 1 "Active" 0 "Inactive" ;
VAL_ 883 BCM2_1_St_KLR 1 "Active" 0 "Inactive" ;
VAL_ 883 BCM2_1_St_KL50 1 "Active" 0 "Inactive" ;
VAL_ 320 BR2_1_F_VehicleSpeed 1 "Valid" 0 "Invalid" ;
VAL_ 1152 ICM2_1_N_Odograph 1048575 "Error Value" ;
VAL_ 38 SDM2_1_St_FrontCrash 1 "Front_Crash" 0 "not_Front_Crash" ;
VAL_ 38 SDM2_1_St_BackCrash 1 "Back_Crash" 0 "not_Back_Crash" ;
VAL_ 38 SDM2_1_St_LeftCrash 1 "Left__Crash" 0 "not_Left_Crash" ;
VAL_ 38 SDM2_1_St_RightCrash 1 "Right_Crash" 0 "not_Right_Crash" ;
VAL_ 38 SDM2_1_St_CrashIntensity 7 "Urgent Crash" 6 "Fuel Cutoff" 5 "Fuel Cutoff" 4 "Fuel Cutoff" 3 "Alarm Telephone" 2 "Alarm Telephone" 1 "Hazard Flash, interior light on." 0 "not crash" ;
VAL_ 885 OBC2__Status 0 "idle" 1 "Ready" 2 "Working
" 3 "Charger Fault" ;
VAL_ 885 OBC2__CPStatus 0 "No CP Signal(Charge Mode 1)" 1 "CP Normal (Charge Mode 2, 3)" 2 "CP Abnormal (Charge Mode 2, 3)
" ;
VAL_ 885 OBC2__Status_RelayWeldCheckRslt 0 "Init ��ʼ��״̬��δ��ʼ���������¿�����
" 1 "Pass ճ��������쳣" 2 "OpenFail �̵���ճ��
" 3 "CloseFail �̵����޷��պ�" ;
VAL_ 885 OBC2__RQ_S2Relay_OnOff 1 "Relay On" 0 "Relay Off" ;
VAL_ 885 OBC2__ChargingStopResponse 0 "None" 1 "Charging stop" 2 "Error
" 3 "Invalid" ;
VAL_ 1453 BMSCMATemp_N_No24 255 "Error Value" ;
VAL_ 1453 BMSCMATemp_N_No23 255 "Error Value" ;
VAL_ 1453 BMSCMATemp_N_No22 255 "Error Value" ;
VAL_ 1453 BMSCMATemp_N_No21 255 "Error Value" ;
VAL_ 1453 BMSCMATemp_N_No20 255 "Error Value" ;
VAL_ 1453 BMSCMATemp_N_No19 255 "Error Value" ;
VAL_ 1453 BMSCMATemp_N_No18 255 "Error Value" ;
VAL_ 1453 BMSCMATemp_N_No17 255 "Error Value" ;
VAL_ 1453 BMSCMATemp_N_No16 255 "Error Value" ;
VAL_ 1453 BMSCMATemp_N_No15 255 "Error Value" ;
VAL_ 1453 BMSCMATemp_N_No14 255 "Error Value" ;
VAL_ 1453 BMSCMATemp_N_No13 255 "Error Value" ;
VAL_ 1453 BMSCMATemp_N_No9 255 "Error Value" ;
VAL_ 1453 BMSCMATemp_N_No12 255 "Error Value" ;
VAL_ 1453 BMSCMATemp_N_No11 255 "Error Value" ;
VAL_ 1453 BMSCMATemp_N_No10 255 "Error Value" ;
VAL_ 1453 BMSCMATemp_N_No1 255 "Error Value" ;
VAL_ 1453 BMSCMATemp_N_No3 255 "Error Value" ;
VAL_ 1453 BMSCMATemp_N_No4 255 "Error Value" ;
VAL_ 1453 BMSCMATemp_N_No5 255 "Error Value" ;
VAL_ 1453 BMSCMATemp_N_No6 255 "Error Value" ;
VAL_ 1453 BMSCMATemp_N_No7 255 "Error Value" ;
VAL_ 1453 BMSCMATemp_N_No8 255 "Error Value" ;
VAL_ 1453 BMSCMATemp_N_No2 255 "Error Value" ;
VAL_ 1441 BMSCellVol1_N_No1 255 "Error Value" ;
VAL_ 1441 BMSCellVol1_N_No3 255 "Error Value" ;
VAL_ 1441 BMSCellVol1_N_No4 255 "Error Value" ;
VAL_ 1441 BMSCellVol1_N_No5 255 "Error Value" ;
VAL_ 1441 BMSCellVol1_N_No6 255 "Error Value" ;
VAL_ 1441 BMSCellVol1_N_No7 255 "Error Value" ;
VAL_ 1441 BMSCellVol1_N_No8 255 "Error Value" ;
VAL_ 1441 BMSCellVol1_N_No2 255 "Error Value" ;
VAL_ 1450 BMSCellVol10_N_No73 255 "Error Value" ;
VAL_ 1450 BMSCellVol10_N_No75 255 "Error Value" ;
VAL_ 1450 BMSCellVol10_N_No76 255 "Error Value" ;
VAL_ 1450 BMSCellVol10_N_No77 255 "Error Value" ;
VAL_ 1450 BMSCellVol10_N_No78 255 "Error Value" ;
VAL_ 1450 BMSCellVol10_N_No79 255 "Error Value" ;
VAL_ 1450 BMSCellVol10_N_No80 255 "Error Value" ;
VAL_ 1450 BMSCellVol10_N_No74 255 "Error Value" ;
VAL_ 1451 BMSCellVol11_N_No81 255 "Error Value" ;
VAL_ 1451 BMSCellVol11_N_No83 255 "Error Value" ;
VAL_ 1451 BMSCellVol11_N_No84 255 "Error Value" ;
VAL_ 1451 BMSCellVol11_N_No85 255 "Error Value" ;
VAL_ 1451 BMSCellVol11_N_No86 255 "Error Value" ;
VAL_ 1451 BMSCellVol11_N_No87 255 "Error Value" ;
VAL_ 1451 BMSCellVol11_N_No88 255 "Error Value" ;
VAL_ 1451 BMSCellVol11_N_No82 255 "Error Value" ;
VAL_ 1452 BMSCellVol12_N_No89 255 "Error Value" ;
VAL_ 1452 BMSCellVol12_N_No91 255 "Error Value" ;
VAL_ 1452 BMSCellVol12_N_No92 255 "Error Value" ;
VAL_ 1452 BMSCellVol12_N_No93 255 "Error Value" ;
VAL_ 1452 BMSCellVol12_N_No94 255 "Error Value" ;
VAL_ 1452 BMSCellVol12_N_No95 255 "Error Value" ;
VAL_ 1452 BMSCellVol12_N_No96 255 "Error Value" ;
VAL_ 1452 BMSCellVol12_N_No90 255 "Error Value" ;
VAL_ 1442 BMSCellVol2_N_No9 255 "Error Value" ;
VAL_ 1442 BMSCellVol2_N_No11 255 "Error Value" ;
VAL_ 1442 BMSCellVol2_N_No12 255 "Error Value" ;
VAL_ 1442 BMSCellVol2_N_No13 255 "Error Value" ;
VAL_ 1442 BMSCellVol2_N_No14 255 "Error Value" ;
VAL_ 1442 BMSCellVol2_N_No15 255 "Error Value" ;
VAL_ 1442 BMSCellVol2_N_No16 255 "Error Value" ;
VAL_ 1442 BMSCellVol2_N_No10 255 "Error Value" ;
VAL_ 1443 BMSCellVol3_N_No17 255 "Error Value" ;
VAL_ 1443 BMSCellVol3_N_No19 255 "Error Value" ;
VAL_ 1443 BMSCellVol3_N_No20 255 "Error Value" ;
VAL_ 1443 BMSCellVol3_N_No21 255 "Error Value" ;
VAL_ 1443 BMSCellVol3_N_No22 255 "Error Value" ;
VAL_ 1443 BMSCellVol3_N_No23 255 "Error Value" ;
VAL_ 1443 BMSCellVol3_N_No24 255 "Error Value" ;
VAL_ 1443 BMSCellVol3_N_No18 255 "Error Value" ;
VAL_ 1444 BMSCellVol4_N_No25 255 "Error Value" ;
VAL_ 1444 BMSCellVol4_N_No27 255 "Error Value" ;
VAL_ 1444 BMSCellVol4_N_No28 255 "Error Value" ;
VAL_ 1444 BMSCellVol4_N_No29 255 "Error Value" ;
VAL_ 1444 BMSCellVol4_N_No30 255 "Error Value" ;
VAL_ 1444 BMSCellVol4_N_No31 255 "Error Value" ;
VAL_ 1444 BMSCellVol4_N_No32 255 "Error Value" ;
VAL_ 1444 BMSCellVol4_N_No26 255 "Error Value" ;
VAL_ 1445 BMSCellVol5_N_No33 255 "Error Value" ;
VAL_ 1445 BMSCellVol5_N_No35 255 "Error Value" ;
VAL_ 1445 BMSCellVol5_N_No36 255 "Error Value" ;
VAL_ 1445 BMSCellVol5_N_No37 255 "Error Value" ;
VAL_ 1445 BMSCellVol5_N_No38 255 "Error Value" ;
VAL_ 1445 BMSCellVol5_N_No39 255 "Error Value" ;
VAL_ 1445 BMSCellVol5_N_No40 255 "Error Value" ;
VAL_ 1445 BMSCellVol5_N_No34 255 "Error Value" ;
VAL_ 1446 BMSCellVol6_N_No41 255 "Error Value" ;
VAL_ 1446 BMSCellVol6_N_No43 255 "Error Value" ;
VAL_ 1446 BMSCellVol6_N_No44 255 "Error Value" ;
VAL_ 1446 BMSCellVol6_N_No45 255 "Error Value" ;
VAL_ 1446 BMSCellVol6_N_No46 255 "Error Value" ;
VAL_ 1446 BMSCellVol6_N_No47 255 "Error Value" ;
VAL_ 1446 BMSCellVol6_N_No48 255 "Error Value" ;
VAL_ 1446 BMSCellVol6_N_No42 255 "Error Value" ;
VAL_ 1447 BMSCellVol7_N_No49 255 "Error Value" ;
VAL_ 1447 BMSCellVol7_N_No51 255 "Error Value" ;
VAL_ 1447 BMSCellVol7_N_No52 255 "Error Value" ;
VAL_ 1447 BMSCellVol7_N_No53 255 "Error Value" ;
VAL_ 1447 BMSCellVol7_N_No54 255 "Error Value" ;
VAL_ 1447 BMSCellVol7_N_No55 255 "Error Value" ;
VAL_ 1447 BMSCellVol7_N_No56 255 "Error Value" ;
VAL_ 1447 BMSCellVol7_N_No50 255 "Error Value" ;
VAL_ 1448 BMSCellVol8_N_No57 255 "Error Value" ;
VAL_ 1448 BMSCellVol8_N_No59 255 "Error Value" ;
VAL_ 1448 BMSCellVol8_N_No60 255 "Error Value" ;
VAL_ 1448 BMSCellVol8_N_No61 255 "Error Value" ;
VAL_ 1448 BMSCellVol8_N_No62 255 "Error Value" ;
VAL_ 1448 BMSCellVol8_N_No63 255 "Error Value" ;
VAL_ 1448 BMSCellVol8_N_No64 255 "Error Value" ;
VAL_ 1448 BMSCellVol8_N_No58 255 "Error Value" ;
VAL_ 1449 BMSCellVol9_N_No65 255 "Error Value" ;
VAL_ 1449 BMSCellVol9_N_No67 255 "Error Value" ;
VAL_ 1449 BMSCellVol9_N_No68 255 "Error Value" ;
VAL_ 1449 BMSCellVol9_N_No69 255 "Error Value" ;
VAL_ 1449 BMSCellVol9_N_No70 255 "Error Value" ;
VAL_ 1449 BMSCellVol9_N_No71 255 "Error Value" ;
VAL_ 1449 BMSCellVol9_N_No72 255 "Error Value" ;
VAL_ 1449 BMSCellVol9_N_No66 255 "Error Value" ;
VAL_ 672 BMS1_F_BatteryFaultLevel 15 "Error Value" 5 "Very Serious(Power Derating:Cut off relay by BMS after 2s)" 4 "Serious(Power Derating:Cut off relay by HCU vai CAN Command)" 3 "Serious but not relay off(Power Derating to Zero by BMS)" 2 "Minor fault but derating(Power Derating by BMS)" 1 "Minor fault(No effect on SOF)" 0 "Normal" ;
VAL_ 672 BMS1_St_BatteryMode 15 "Error Value" 7 "Failure(Diag-Level 5)" 6 "Battery Heating" 5 "Power off" 4 "DC Charge" 3 "AC Charge" 2 "Supplying" 0 "Init" ;
VAL_ 672 BMS1_St_HVIL 1 "Disconnected" 0 "Connected" ;
VAL_ 672 BMS1_N_BatteryCurrent 2047 "Error Value" ;
VAL_ 672 BMS1_St_PrechargeMode 7 "Error Value" 4 "Precharge Inhibited" 3 "Precharge Failed" 2 "Precharge Finished" 1 "Precharging" 0 "Standby" ;
VAL_ 672 BMS1_N_BatteryVoltage 1023 "Error Value" ;
VAL_ 672 BMS1_N_DCLinkVoltage 1023 "Error Value" ;
VAL_ 672 BMS1_St_MainPositiveRelay 1 "Connected" 0 "Disconnected" ;
VAL_ 672 BMS1_St_MainNegativeRelay 1 "Connected" 0 "Disconnected" ;
VAL_ 672 BMS1_St_PrechargeRelay 1 "Connected" 0 "Disconnected" ;
VAL_ 672 BMS1_St_QCPositiveRelay 1 "Connected" 0 "Disconnected" ;
VAL_ 672 BMS1_St_QCNegativeRelay 1 "Connected" 0 "Disconnected" ;
VAL_ 1184 BMS2_F_Isolation 1 "Fault" 0 "No Fault" ;
VAL_ 1184 BMS2_N_CellSumVoltage 1023 "Error Value" ;
VAL_ 1184 BMS2_N_SOE 1023 "Error Value" ;
VAL_ 1184 BMS2_N_SOH 255 "Error Value" ;
VAL_ 1184 BMS2_N_RSOC 255 "Error Value" ;
VAL_ 1186 BMS4_F_CMATempDiff 1 "Fault" 0 "No Fault" ;
VAL_ 1186 BMS4_F_BattOverTemp 3 "Level 3, Derating to Zero" 2 "Level 2, Derating(Not Zero)" 1 "Level 1, Warning" 0 "Normal" ;
VAL_ 1186 BMS4_N_CMATempAve 255 "Error Value" ;
VAL_ 1186 BMS4_N_CMATempMax 255 "Error Value" ;
VAL_ 1186 BMS4_N_CMATempMin 255 "Error Value" ;
VAL_ 1186 BMS4_N_InletTemp 255 "Error Value" ;
VAL_ 1186 BMS4_F_BattLowTemp1 1 "Fault" 0 "Normal" ;
VAL_ 1186 BMS4_F_BattLowTemp2 1 "Fault" 0 "Normal" ;
VAL_ 1186 BMS4_F_BattLowTemp3 1 "Fault" 0 "Normal" ;
VAL_ 1186 BMS4_N_BatPwrConsumption 8191 "Error Value" ;
VAL_ 932 BMS6_St_BatHeatingReq 1 "Request" 0 "Not Request" ;
VAL_ 932 BMS6_W_HVBattDanger 1 "Warning" 0 "Not warning" ;
VAL_ 1188 BMS7_N_SOF10D 2047 "Error Value" ;
VAL_ 1188 BMS7_N_SOFContinuousD 2047 "Error Value" ;
VAL_ 1188 BMS7_N_SOF10C 2047 "Error Value" ;
VAL_ 1188 BMS7_N_SOF30C 2047 "Error Value" ;
VAL_ 1189 BMS8_N_SOF30D 2047 "Error Value" ;
VAL_ 1189 BMS8_N_SOF2D 2047 "Error Value" ;
VAL_ 1189 BMS8_N_SOF2C 2047 "Error Value" ;
VAL_ 1190 BMS10_N_CellVoltageAve 8191 "Error Value" ;
VAL_ 1190 BMS10_InsChkState 2 "System check completed
" 1 "System checking
" 0 "No error" ;
VAL_ 1190 BMS10_RelayChkState 2 "System check completed
" 1 "System checking
" 0 "No error" ;
VAL_ 1190 BMS10_ChargerWorkingEnable 0 "Not Enable
" 1 "Enable" ;
VAL_ 1190 BMS10_BatteryChargeStatus 0 "Idle
" 1 "Charging" 2 "Normal Charge Finish
" 3 "Abnormal Charge Fault" ;
VAL_ 1680 DevBMS1_N_ColdFanPWM 255 "Error Value" ;
VAL_ 1661 NMBMS_RepeatFromSleep 1 "occur" 0 "not occur" ;
VAL_ 1661 NMBMS_RepeatFromPrepare 1 "occur" 0 "not occur" ;
VAL_ 1661 NMBMS_RepeatFromNormal 1 "occur" 0 "not occur" ;
VAL_ 1661 NMBMS_RepeatFromReady 1 "occur" 0 "not occur" ;
VAL_ 1661 NMBMS_NormalFromRepeat 1 "occur" 0 "not occur" ;
VAL_ 1661 NMBMS_NormalFromReady 1 "occur" 0 "not occur" ;
VAL_ 1661 NMBMS_WakeFromGW 1 "occur" 0 "not occur" ;
VAL_ 1661 NMBMS_GWRequest 1 "request" 0 "not request" ;
VAL_ 1661 NMBMS_WakeSource 4 "External Charging Equipment��DC��" 1 "KL.15" 0 "CAN wakeup" ;
VAL_ 1661 NMBMS_ActiveSource1 1 "KL15" 0 "not active" ;
VAL_ 1661 NMBMS_ActiveSource2 1 "Diagnose" 0 "not active" ;
VAL_ 1661 NMBMS_ActiveSource3 1 "Repeat message timer has not expired" 0 "not active" ;
VAL_ 1661 NMBMS_ActiveSource4 1 "AC Charging" 0 "not active" ;
VAL_ 1661 NMBMS_ActiveSource5 1 "DC Charging" 0 "not active" ;
VAL_ 1661 NMBMS_RepeatReq 1 "request" 0 "not request" ;
VAL_ 867 BCM1_St_KL15 1 "Active" 0 "Inactive" ;
VAL_ 867 BCM1_St_KLR 1 "Active" 0 "Inactive" ;
VAL_ 867 BCM1_St_KL50 1 "Active" 0 "Inactive" ;
VAL_ 304 BR1_F_VehicleSpeed 1 "Valid" 0 "Invalid" ;
VAL_ 400 HCU_1_BmsSleep 0 "none" 1 "go to sleep" 2 "wake up" 3 "Invalid" ;
VAL_ 400 HCU_1_WeldedFaultCheck 1 "Check" 0 "Discheck" ;
VAL_ 400 HCU_1_InsCheck 1 "Check" 0 "Discheck" ;
VAL_ 400 HCU1_St_Ready 1 "Ready" 0 "Not Ready" ;
VAL_ 400 HCU1_F_HVConnectRequest 1 "Valid" 0 "Invalid" ;
VAL_ 400 HCU1_St_HVConnectRequest 1 "Connect" 0 "Disconnect" ;
VAL_ 1136 ICM1_N_Odograph 1048575 "Error Value" ;
VAL_ 22 SDM1_St_FrontCrash 1 "Front_Crash" 0 "not_Front_Crash" ;
VAL_ 22 SDM1_St_BackCrash 1 "Back_Crash" 0 "not_Back_Crash" ;
VAL_ 22 SDM1_St_LeftCrash 1 "Left__Crash" 0 "not_Left_Crash" ;
VAL_ 22 SDM1_St_RightCrash 1 "Right_Crash" 0 "not_Right_Crash" ;
VAL_ 22 SDM1_St_CrashIntensity 7 "Urgent Crash" 6 "Fuel Cutoff" 5 "Fuel Cutoff" 4 "Fuel Cutoff" 3 "Alarm Telephone" 2 "Alarm Telephone" 1 "Hazard Flash, interior light on." 0 "not crash" ;
VAL_ 869 OBC_Status 0 "idle" 1 "Ready" 2 "Working
" 3 "Charger Fault" ;
VAL_ 869 OBC_CPStatus 0 "No CP Signal(Charge Mode 1)" 1 "CP Normal (Charge Mode 2, 3)" 2 "CP Abnormal (Charge Mode 2, 3)
" ;
VAL_ 869 OBC_Status_RelayWeldCheckRslt 0 "Init ��ʼ��״̬��δ��ʼ���������¿�����
" 1 "Pass ճ��������쳣" 2 "OpenFail �̵���ճ��
" 3 "CloseFail �̵����޷��պ�" ;
VAL_ 869 OBC_RQ_S2Relay_OnOff 1 "Relay On" 0 "Relay Off" ;
VAL_ 869 OBC_ChargingStopResponse 0 "None" 1 "Charging stop" 2 "Error
" 3 "Invalid" ;
